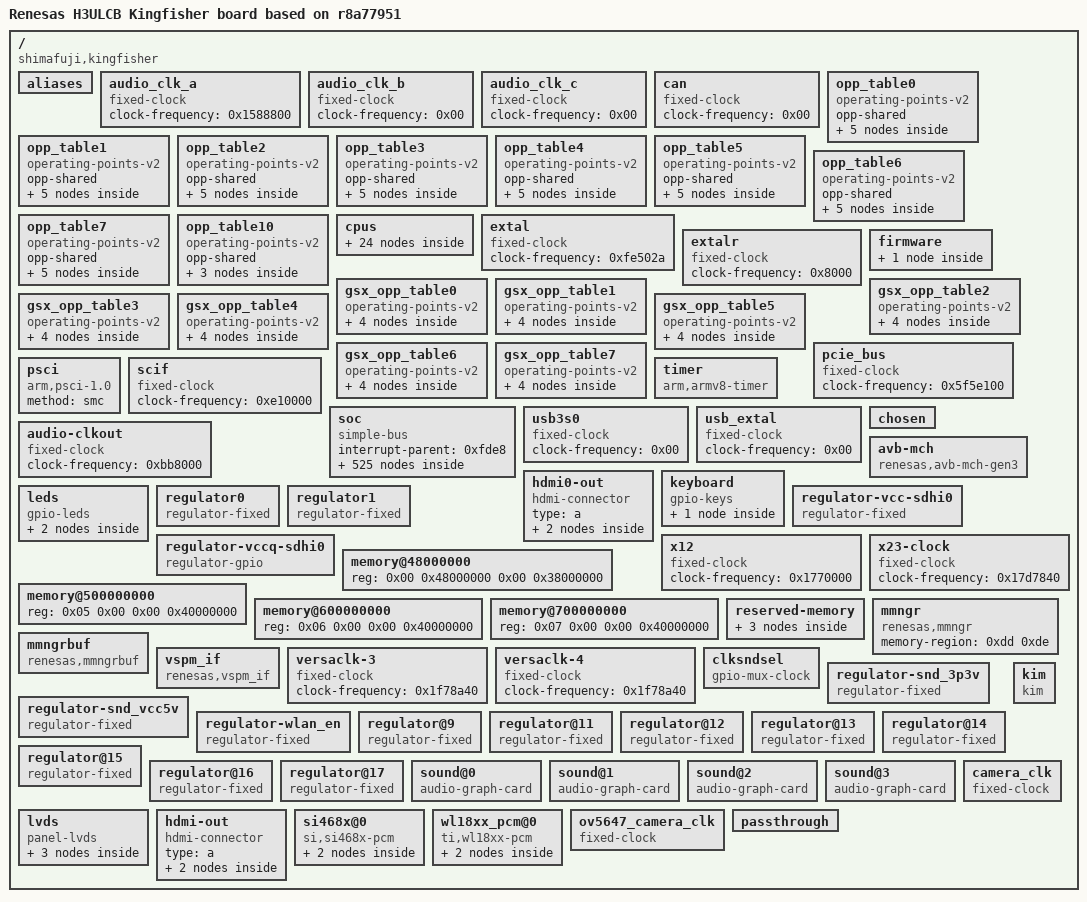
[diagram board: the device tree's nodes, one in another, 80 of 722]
/dts-v1/;

/ {
	compatible = "shimafuji,kingfisher\0renesas,h3ulcb\0renesas,r8a7795";
	#address-cells = <0x02>;
	#size-cells = <0x02>;
	model = "Renesas H3ULCB Kingfisher board based on r8a77951";

	aliases {
		i2c0 = "/soc/i2c@e6500000";
		i2c1 = "/soc/i2c@e6508000";
		i2c2 = "/soc/i2c@e6510000";
		i2c3 = "/soc/i2c@e66d0000";
		i2c4 = "/soc/i2c@e66d8000";
		i2c5 = "/soc/i2c@e66e0000";
		i2c6 = "/soc/i2c@e66e8000";
		i2c7 = "/soc/i2c@e60b0000";
		spi0 = "/soc/spi@e6e90000";
		spi1 = "/soc/spi@e6ea0000";
		spi2 = "/soc/spi@e6c00000";
		spi3 = "/soc/spi@e6c10000";
		serial0 = "/soc/serial@e6e88000";
		ethernet0 = "/soc/ethernet@e6800000";
		mmc0 = "/soc/mmc@ee140000";
		mmc1 = "/soc/mmc@ee100000";
		serial1 = "/soc/serial@e6540000";
		serial2 = "/soc/serial@e6e68000";
		serial3 = "/soc/serial@e6550000";
		mmc2 = "/soc/mmc@ee160000";
	};

	audio_clk_a {
		compatible = "fixed-clock";
		#clock-cells = <0x00>;
		clock-frequency = <0x1588800>;
		phandle = <0x79>;
	};

	audio_clk_b {
		compatible = "fixed-clock";
		#clock-cells = <0x00>;
		clock-frequency = <0x00>;
		phandle = <0xe9>;
	};

	audio_clk_c {
		compatible = "fixed-clock";
		#clock-cells = <0x00>;
		clock-frequency = <0x00>;
		phandle = <0x7a>;
	};

	can {
		compatible = "fixed-clock";
		#clock-cells = <0x00>;
		clock-frequency = <0x00>;
		phandle = <0x58>;
	};

	opp_table0 {
		compatible = "operating-points-v2";
		opp-shared;
		phandle = <0x0d>;

		opp-500000000 {
			opp-hz = <0x00 0x1dcd6500>;
			opp-microvolt = <0xcaa30>;
			clock-latency-ns = <0x493e0>;
		};

		opp-1000000000 {
			opp-hz = <0x00 0x3b9aca00>;
			opp-microvolt = <0xcaa30>;
			clock-latency-ns = <0x493e0>;
		};

		opp-1500000000 {
			opp-hz = <0x00 0x59682f00>;
			opp-microvolt = <0xcaa30>;
			clock-latency-ns = <0x493e0>;
			opp-suspend;
		};

		opp-1600000000 {
			opp-hz = <0x00 0x5f5e1000>;
			opp-microvolt = <0xdbba0>;
			clock-latency-ns = <0x493e0>;
			turbo-mode;
		};

		opp-1700000000 {
			opp-hz = <0x00 0x6553f100>;
			opp-microvolt = <0xea600>;
			clock-latency-ns = <0x493e0>;
			turbo-mode;
		};
	};

	opp_table1 {
		compatible = "operating-points-v2";
		opp-shared;
		phandle = <0x0e>;

		opp-500000000 {
			opp-hz = <0x00 0x1dcd6500>;
			opp-microvolt = <0xc8320>;
			clock-latency-ns = <0x493e0>;
		};

		opp-1000000000 {
			opp-hz = <0x00 0x3b9aca00>;
			opp-microvolt = <0xc8320>;
			clock-latency-ns = <0x493e0>;
		};

		opp-1500000000 {
			opp-hz = <0x00 0x59682f00>;
			opp-microvolt = <0xc8320>;
			clock-latency-ns = <0x493e0>;
			opp-suspend;
		};

		opp-1600000000 {
			opp-hz = <0x00 0x5f5e1000>;
			opp-microvolt = <0xd9490>;
			clock-latency-ns = <0x493e0>;
			turbo-mode;
		};

		opp-1700000000 {
			opp-hz = <0x00 0x6553f100>;
			opp-microvolt = <0xe7ef0>;
			clock-latency-ns = <0x493e0>;
			turbo-mode;
		};
	};

	opp_table2 {
		compatible = "operating-points-v2";
		opp-shared;
		phandle = <0x0f>;

		opp-500000000 {
			opp-hz = <0x00 0x1dcd6500>;
			opp-microvolt = <0xc5c10>;
			clock-latency-ns = <0x493e0>;
		};

		opp-1000000000 {
			opp-hz = <0x00 0x3b9aca00>;
			opp-microvolt = <0xc5c10>;
			clock-latency-ns = <0x493e0>;
		};

		opp-1500000000 {
			opp-hz = <0x00 0x59682f00>;
			opp-microvolt = <0xc5c10>;
			clock-latency-ns = <0x493e0>;
			opp-suspend;
		};

		opp-1600000000 {
			opp-hz = <0x00 0x5f5e1000>;
			opp-microvolt = <0xd6d80>;
			clock-latency-ns = <0x493e0>;
			turbo-mode;
		};

		opp-1700000000 {
			opp-hz = <0x00 0x6553f100>;
			opp-microvolt = <0xe30d0>;
			clock-latency-ns = <0x493e0>;
			turbo-mode;
		};
	};

	opp_table3 {
		compatible = "operating-points-v2";
		opp-shared;
		phandle = <0x10>;

		opp-500000000 {
			opp-hz = <0x00 0x1dcd6500>;
			opp-microvolt = "\0\f5";
			clock-latency-ns = <0x493e0>;
		};

		opp-1000000000 {
			opp-hz = <0x00 0x3b9aca00>;
			opp-microvolt = "\0\f5";
			clock-latency-ns = <0x493e0>;
		};

		opp-1500000000 {
			opp-hz = <0x00 0x59682f00>;
			opp-microvolt = "\0\f5";
			clock-latency-ns = <0x493e0>;
			opp-suspend;
		};

		opp-1600000000 {
			opp-hz = <0x00 0x5f5e1000>;
			opp-microvolt = <0xd4670>;
			clock-latency-ns = <0x493e0>;
			turbo-mode;
		};

		opp-1700000000 {
			opp-hz = <0x00 0x6553f100>;
			opp-microvolt = <0xde2b0>;
			clock-latency-ns = <0x493e0>;
			turbo-mode;
		};
	};

	opp_table4 {
		compatible = "operating-points-v2";
		opp-shared;
		phandle = <0x11>;

		opp-500000000 {
			opp-hz = <0x00 0x1dcd6500>;
			opp-microvolt = <0xc0df0>;
			clock-latency-ns = <0x493e0>;
		};

		opp-1000000000 {
			opp-hz = <0x00 0x3b9aca00>;
			opp-microvolt = <0xc0df0>;
			clock-latency-ns = <0x493e0>;
		};

		opp-1500000000 {
			opp-hz = <0x00 0x59682f00>;
			opp-microvolt = <0xc0df0>;
			clock-latency-ns = <0x493e0>;
			opp-suspend;
		};

		opp-1600000000 {
			opp-hz = <0x00 0x5f5e1000>;
			opp-microvolt = <0xd1f60>;
			clock-latency-ns = <0x493e0>;
			turbo-mode;
		};

		opp-1700000000 {
			opp-hz = <0x00 0x6553f100>;
			opp-microvolt = <0xd9490>;
			clock-latency-ns = <0x493e0>;
			turbo-mode;
		};
	};

	opp_table5 {
		compatible = "operating-points-v2";
		opp-shared;
		phandle = <0x12>;

		opp-500000000 {
			opp-hz = <0x00 0x1dcd6500>;
			opp-microvolt = <0xbe6e0>;
			clock-latency-ns = <0x493e0>;
		};

		opp-1000000000 {
			opp-hz = <0x00 0x3b9aca00>;
			opp-microvolt = <0xbe6e0>;
			clock-latency-ns = <0x493e0>;
		};

		opp-1500000000 {
			opp-hz = <0x00 0x59682f00>;
			opp-microvolt = <0xbe6e0>;
			clock-latency-ns = <0x493e0>;
			opp-suspend;
		};

		opp-1600000000 {
			opp-hz = <0x00 0x5f5e1000>;
			opp-microvolt = <0xcf850>;
			clock-latency-ns = <0x493e0>;
			turbo-mode;
		};

		opp-1700000000 {
			opp-hz = <0x00 0x6553f100>;
			opp-microvolt = <0xd6d80>;
			clock-latency-ns = <0x493e0>;
			turbo-mode;
		};
	};

	opp_table6 {
		compatible = "operating-points-v2";
		opp-shared;
		phandle = <0x13>;

		opp-500000000 {
			opp-hz = <0x00 0x1dcd6500>;
			opp-microvolt = <0xbbfd0>;
			clock-latency-ns = <0x493e0>;
		};

		opp-1000000000 {
			opp-hz = <0x00 0x3b9aca00>;
			opp-microvolt = <0xbbfd0>;
			clock-latency-ns = <0x493e0>;
		};

		opp-1500000000 {
			opp-hz = <0x00 0x59682f00>;
			opp-microvolt = <0xbbfd0>;
			clock-latency-ns = <0x493e0>;
			opp-suspend;
		};

		opp-1600000000 {
			opp-hz = <0x00 0x5f5e1000>;
			opp-microvolt = <0xcd140>;
			clock-latency-ns = <0x493e0>;
			turbo-mode;
		};

		opp-1700000000 {
			opp-hz = <0x00 0x6553f100>;
			opp-microvolt = <0xd4670>;
			clock-latency-ns = <0x493e0>;
			turbo-mode;
		};
	};

	opp_table7 {
		compatible = "operating-points-v2";
		opp-shared;
		phandle = <0x14>;

		opp-500000000 {
			opp-hz = <0x00 0x1dcd6500>;
			opp-microvolt = <0xb98c0>;
			clock-latency-ns = <0x493e0>;
		};

		opp-1000000000 {
			opp-hz = <0x00 0x3b9aca00>;
			opp-microvolt = <0xb98c0>;
			clock-latency-ns = <0x493e0>;
		};

		opp-1500000000 {
			opp-hz = <0x00 0x59682f00>;
			opp-microvolt = <0xb98c0>;
			clock-latency-ns = <0x493e0>;
			opp-suspend;
		};

		opp-1600000000 {
			opp-hz = <0x00 0x5f5e1000>;
			opp-microvolt = <0xcaa30>;
			clock-latency-ns = <0x493e0>;
			turbo-mode;
		};

		opp-1700000000 {
			opp-hz = <0x00 0x6553f100>;
			opp-microvolt = <0xd1f60>;
			clock-latency-ns = <0x493e0>;
			turbo-mode;
		};
	};

	opp_table10 {
		compatible = "operating-points-v2";
		opp-shared;
		phandle = <0x18>;

		opp-800000000 {
			opp-hz = <0x00 0x2faf0800>;
			opp-microvolt = <0xc8320>;
			clock-latency-ns = <0x493e0>;
		};

		opp-1000000000 {
			opp-hz = <0x00 0x3b9aca00>;
			opp-microvolt = <0xc8320>;
			clock-latency-ns = <0x493e0>;
		};

		opp-1200000000 {
			opp-hz = <0x00 0x47868c00>;
			opp-microvolt = <0xc8320>;
			clock-latency-ns = <0x493e0>;
			opp-suspend;
		};
	};

	cpus {
		#address-cells = <0x01>;
		#size-cells = <0x00>;

		cpu-map {

			cluster0 {

				core0 {
					cpu = <0x01>;
				};

				core1 {
					cpu = <0x02>;
				};

				core2 {
					cpu = <0x03>;
				};

				core3 {
					cpu = <0x04>;
				};
			};

			cluster1 {

				core0 {
					cpu = <0x05>;
				};

				core1 {
					cpu = <0x06>;
				};

				core2 {
					cpu = <0x07>;
				};

				core3 {
					cpu = <0x08>;
				};
			};
		};

		cpu@0 {
			compatible = "arm,cortex-a57";
			reg = <0x00>;
			device_type = "cpu";
			power-domains = <0x09 0x00>;
			next-level-cache = <0x0a>;
			enable-method = "psci";
			cpu-idle-states = <0x0b>;
			dynamic-power-coefficient = <0x356>;
			cooling-min-level = <0x00>;
			cooling-max-level = <0x02>;
			clocks = <0x0c 0x00 0x00>;
			operating-points-v2 = <0x0d 0x0e 0x0f 0x10 0x11 0x12 0x13 0x14>;
			capacity-dmips-mhz = <0x400>;
			#cooling-cells = <0x02>;
			cpu-supply = <0x15>;
			phandle = <0x01>;
		};

		cpu@1 {
			compatible = "arm,cortex-a57";
			reg = <0x01>;
			device_type = "cpu";
			power-domains = <0x09 0x01>;
			next-level-cache = <0x0a>;
			enable-method = "psci";
			cpu-idle-states = <0x0b>;
			clocks = <0x0c 0x00 0x00>;
			operating-points-v2 = <0x0d 0x0e 0x0f 0x10 0x11 0x12 0x13 0x14>;
			capacity-dmips-mhz = <0x400>;
			#cooling-cells = <0x02>;
			phandle = <0x02>;
		};

		cpu@2 {
			compatible = "arm,cortex-a57";
			reg = <0x02>;
			device_type = "cpu";
			power-domains = <0x09 0x02>;
			next-level-cache = <0x0a>;
			enable-method = "psci";
			cpu-idle-states = <0x0b>;
			clocks = <0x0c 0x00 0x00>;
			operating-points-v2 = <0x0d 0x0e 0x0f 0x10 0x11 0x12 0x13 0x14>;
			capacity-dmips-mhz = <0x400>;
			#cooling-cells = <0x02>;
			phandle = <0x03>;
		};

		cpu@3 {
			compatible = "arm,cortex-a57";
			reg = <0x03>;
			device_type = "cpu";
			power-domains = <0x09 0x03>;
			next-level-cache = <0x0a>;
			enable-method = "psci";
			cpu-idle-states = <0x0b>;
			clocks = <0x0c 0x00 0x00>;
			operating-points-v2 = <0x0d 0x0e 0x0f 0x10 0x11 0x12 0x13 0x14>;
			capacity-dmips-mhz = <0x400>;
			#cooling-cells = <0x02>;
			phandle = <0x04>;
		};

		cpu@100 {
			compatible = "arm,cortex-a53";
			reg = <0x100>;
			device_type = "cpu";
			power-domains = <0x09 0x05>;
			next-level-cache = <0x16>;
			enable-method = "psci";
			cpu-idle-states = <0x17>;
			#cooling-cells = <0x02>;
			dynamic-power-coefficient = <0x115>;
			cooling-min-level = <0x00>;
			cooling-max-level = <0x02>;
			clocks = <0x0c 0x00 0x01>;
			operating-points-v2 = <0x18>;
			capacity-dmips-mhz = <0x21c>;
			phandle = <0x05>;
		};

		cpu@101 {
			compatible = "arm,cortex-a53";
			reg = <0x101>;
			device_type = "cpu";
			power-domains = <0x09 0x06>;
			next-level-cache = <0x16>;
			enable-method = "psci";
			cpu-idle-states = <0x17>;
			clocks = <0x0c 0x00 0x01>;
			operating-points-v2 = <0x18>;
			capacity-dmips-mhz = <0x21c>;
			phandle = <0x06>;
		};

		cpu@102 {
			compatible = "arm,cortex-a53";
			reg = <0x102>;
			device_type = "cpu";
			power-domains = <0x09 0x07>;
			next-level-cache = <0x16>;
			enable-method = "psci";
			cpu-idle-states = <0x17>;
			clocks = <0x0c 0x00 0x01>;
			operating-points-v2 = <0x18>;
			capacity-dmips-mhz = <0x21c>;
			phandle = <0x07>;
		};

		cpu@103 {
			compatible = "arm,cortex-a53";
			reg = <0x103>;
			device_type = "cpu";
			power-domains = <0x09 0x08>;
			next-level-cache = <0x16>;
			enable-method = "psci";
			cpu-idle-states = <0x17>;
			clocks = <0x0c 0x00 0x01>;
			operating-points-v2 = <0x18>;
			capacity-dmips-mhz = <0x21c>;
			phandle = <0x08>;
		};

		cache-controller-0 {
			compatible = "cache";
			power-domains = <0x09 0x0c>;
			cache-unified;
			cache-level = <0x02>;
			phandle = <0x0a>;
		};

		cache-controller-1 {
			compatible = "cache";
			power-domains = <0x09 0x15>;
			cache-unified;
			cache-level = <0x02>;
			phandle = <0x16>;
		};

		idle-states {
			entry-method = "psci";

			cpu-sleep-0 {
				compatible = "arm,idle-state";
				arm,psci-suspend-param = <0x10000>;
				local-timer-stop;
				entry-latency-us = <0x190>;
				exit-latency-us = <0x1f4>;
				min-residency-us = <0xfa0>;
				phandle = <0x0b>;
			};

			cpu-sleep-1 {
				compatible = "arm,idle-state";
				arm,psci-suspend-param = <0x10000>;
				local-timer-stop;
				entry-latency-us = <0x2bc>;
				exit-latency-us = <0x2bc>;
				min-residency-us = <0x1388>;
				phandle = <0x17>;
			};
		};
	};

	extal {
		compatible = "fixed-clock";
		#clock-cells = <0x00>;
		clock-frequency = <0xfe502a>;
		phandle = <0x1c>;
	};

	extalr {
		compatible = "fixed-clock";
		#clock-cells = <0x00>;
		clock-frequency = <0x8000>;
		phandle = <0x1d>;
	};

	firmware {

		optee {
			compatible = "linaro,optee-tz";
			method = "smc";
		};
	};

	gsx_opp_table0 {
		compatible = "operating-points-v2";
		phandle = <0xa5>;

		opp-200000000 {
			opp-hz = <0x00 0xbebc200>;
			opp-microvolt = <0xcaa30>;
		};

		opp-300000000 {
			opp-hz = <0x00 0x11e1a300>;
			opp-microvolt = <0xcaa30>;
		};

		opp-400000000 {
			opp-hz = <0x00 0x17d78400>;
			opp-microvolt = <0xcaa30>;
		};

		opp-600000000 {
			opp-hz = <0x00 0x23c34600>;
			opp-microvolt = <0xcaa30>;
		};
	};

	gsx_opp_table1 {
		compatible = "operating-points-v2";
		phandle = <0xa6>;

		opp-200000000 {
			opp-hz = <0x00 0xbebc200>;
			opp-microvolt = <0xc8320>;
		};

		opp-300000000 {
			opp-hz = <0x00 0x11e1a300>;
			opp-microvolt = <0xc8320>;
		};

		opp-400000000 {
			opp-hz = <0x00 0x17d78400>;
			opp-microvolt = <0xc8320>;
		};

		opp-600000000 {
			opp-hz = <0x00 0x23c34600>;
			opp-microvolt = <0xc8320>;
		};
	};

	gsx_opp_table2 {
		compatible = "operating-points-v2";
		phandle = <0xa7>;

		opp-200000000 {
			opp-hz = <0x00 0xbebc200>;
			opp-microvolt = <0xc5c10>;
		};

		opp-300000000 {
			opp-hz = <0x00 0x11e1a300>;
			opp-microvolt = <0xc5c10>;
		};

		opp-400000000 {
			opp-hz = <0x00 0x17d78400>;
			opp-microvolt = <0xc5c10>;
		};

		opp-600000000 {
			opp-hz = <0x00 0x23c34600>;
			opp-microvolt = <0xc5c10>;
		};
	};

	gsx_opp_table3 {
		compatible = "operating-points-v2";
		phandle = <0xa8>;

		opp-200000000 {
			opp-hz = <0x00 0xbebc200>;
			opp-microvolt = "\0\f5";
		};

		opp-300000000 {
			opp-hz = <0x00 0x11e1a300>;
			opp-microvolt = "\0\f5";
		};

		opp-400000000 {
			opp-hz = <0x00 0x17d78400>;
			opp-microvolt = "\0\f5";
		};

		opp-600000000 {
			opp-hz = <0x00 0x23c34600>;
			opp-microvolt = "\0\f5";
		};
	};

	gsx_opp_table4 {
		compatible = "operating-points-v2";
		phandle = <0xa9>;

		opp-200000000 {
			opp-hz = <0x00 0xbebc200>;
			opp-microvolt = <0xc0df0>;
		};

		opp-300000000 {
			opp-hz = <0x00 0x11e1a300>;
			opp-microvolt = <0xc0df0>;
		};

		opp-400000000 {
			opp-hz = <0x00 0x17d78400>;
			opp-microvolt = <0xc0df0>;
		};

		opp-600000000 {
			opp-hz = <0x00 0x23c34600>;
			opp-microvolt = <0xc0df0>;
		};
	};

	gsx_opp_table5 {
		compatible = "operating-points-v2";
		phandle = <0xaa>;

		opp-200000000 {
			opp-hz = <0x00 0xbebc200>;
			opp-microvolt = <0xbe6e0>;
		};

		opp-300000000 {
			opp-hz = <0x00 0x11e1a300>;
			opp-microvolt = <0xbe6e0>;
		};

		opp-400000000 {
			opp-hz = <0x00 0x17d78400>;
			opp-microvolt = <0xbe6e0>;
		};

		opp-600000000 {
			opp-hz = <0x00 0x23c34600>;
			opp-microvolt = <0xbe6e0>;
		};
	};

	gsx_opp_table6 {
		compatible = "operating-points-v2";
		phandle = <0xab>;

		opp-200000000 {
			opp-hz = <0x00 0xbebc200>;
			opp-microvolt = <0xbbfd0>;
		};

		opp-300000000 {
			opp-hz = <0x00 0x11e1a300>;
			opp-microvolt = <0xbbfd0>;
		};

		opp-400000000 {
			opp-hz = <0x00 0x17d78400>;
			opp-microvolt = <0xbbfd0>;
		};

		opp-600000000 {
			opp-hz = <0x00 0x23c34600>;
			opp-microvolt = <0xbbfd0>;
		};
	};

	gsx_opp_table7 {
		compatible = "operating-points-v2";
		phandle = <0xac>;

		opp-200000000 {
			opp-hz = <0x00 0xbebc200>;
			opp-microvolt = <0xb98c0>;
		};

		opp-300000000 {
			opp-hz = <0x00 0x11e1a300>;
			opp-microvolt = <0xb98c0>;
		};

		opp-400000000 {
			opp-hz = <0x00 0x17d78400>;
			opp-microvolt = <0xb98c0>;
		};

		opp-600000000 {
			opp-hz = <0x00 0x23c34600>;
			opp-microvolt = <0xb98c0>;
		};
	};

	pcie_bus {
		compatible = "fixed-clock";
		#clock-cells = <0x00>;
		clock-frequency = <0x5f5e100>;
		status = "okay";
		phandle = <0xae>;
	};

	psci {
		compatible = "arm,psci-1.0\0arm,psci-0.2";
		method = "smc";
	};

	scif {
		compatible = "fixed-clock";
		#clock-cells = <0x00>;
		clock-frequency = <0xe10000>;
		phandle = <0x48>;
	};

	soc {
		compatible = "simple-bus";
		interrupt-parent = <0xfde8>;
		#address-cells = <0x02>;
		#size-cells = <0x02>;
		ranges;
		phandle = <0xea>;

		mfis@e6260000 {
			compatible = "renesas,mfis-lock-r8a7795\0renesas,mfis-lock";
			reg = <0x00 0xe6260000 0x00 0x1000>;
			#hwlock-cells = <0x01>;
			phandle = <0xeb>;
		};

		watchdog@e6020000 {
			compatible = "renesas,r8a7795-wdt\0renesas,rcar-gen3-wdt";
			reg = <0x00 0xe6020000 0x00 0x0c>;
			clocks = <0x0c 0x01 0x192>;
			power-domains = <0x09 0x20>;
			resets = <0x0c 0x192>;
			status = "okay";
			timeout-sec = <0x3c>;
			phandle = <0xec>;
		};

		gpio@e6050000 {
			compatible = "renesas,gpio-r8a7795\0renesas,rcar-gen3-gpio";
			reg = <0x00 0xe6050000 0x00 0x50>;
			interrupts = <0x00 0x04 0x04>;
			#gpio-cells = <0x02>;
			gpio-controller;
			gpio-ranges = <0x19 0x00 0x00 0x10>;
			#interrupt-cells = <0x02>;
			interrupt-controller;
			clocks = <0x0c 0x01 0x390>;
			power-domains = <0x09 0x20>;
			resets = <0x0c 0x390>;
			phandle = <0xed>;
		};

		gpio@e6051000 {
			compatible = "renesas,gpio-r8a7795\0renesas,rcar-gen3-gpio";
			reg = <0x00 0xe6051000 0x00 0x50>;
			interrupts = <0x00 0x05 0x04>;
			#gpio-cells = <0x02>;
			gpio-controller;
			gpio-ranges = <0x19 0x00 0x20 0x1d>;
			#interrupt-cells = <0x02>;
			interrupt-controller;
			clocks = <0x0c 0x01 0x38f>;
			power-domains = <0x09 0x20>;
			resets = <0x0c 0x38f>;
			phandle = <0xa4>;
		};

		gpio@e6052000 {
			compatible = "renesas,gpio-r8a7795\0renesas,rcar-gen3-gpio";
			reg = <0x00 0xe6052000 0x00 0x50>;
			interrupts = <0x00 0x06 0x04>;
			#gpio-cells = <0x02>;
			gpio-controller;
			gpio-ranges = <0x19 0x00 0x40 0x0f>;
			#interrupt-cells = <0x02>;
			interrupt-controller;
			clocks = <0x0c 0x01 0x38e>;
			power-domains = <0x09 0x20>;
			resets = <0x0c 0x38e>;
			phandle = <0x57>;

			gpio@3 {
				gpio-hog;
				gpios = <0x03 0x00>;
				output-high;
				line-name = "BL PWM 100%";
			};
		};

		gpio@e6053000 {
			compatible = "renesas,gpio-r8a7795\0renesas,rcar-gen3-gpio";
			reg = <0x00 0xe6053000 0x00 0x50>;
			interrupts = <0x00 0x07 0x04>;
			#gpio-cells = <0x02>;
			gpio-controller;
			gpio-ranges = <0x19 0x00 0x60 0x10>;
			#interrupt-cells = <0x02>;
			interrupt-controller;
			clocks = <0x0c 0x01 0x38d>;
			power-domains = <0x09 0x20>;
			resets = <0x0c 0x38d>;
			phandle = <0x31>;
		};

		gpio@e6054000 {
			compatible = "renesas,gpio-r8a7795\0renesas,rcar-gen3-gpio";
			reg = <0x00 0xe6054000 0x00 0x50>;
			interrupts = <0x00 0x08 0x04>;
			#gpio-cells = <0x02>;
			gpio-controller;
			gpio-ranges = <0x19 0x00 0x80 0x12>;
			#interrupt-cells = <0x02>;
			interrupt-controller;
			clocks = <0x0c 0x01 0x38c>;
			power-domains = <0x09 0x20>;
			resets = <0x0c 0x38c>;
			phandle = <0xee>;

			most_rst {
				gpio-hog;
				gpios = <0x0e 0x00>;
				output-high;
				line-name = "MOST RST";
			};
		};

		gpio@e6055000 {
			compatible = "renesas,gpio-r8a7795\0renesas,rcar-gen3-gpio";
			reg = <0x00 0xe6055000 0x00 0x50>;
			interrupts = <0x00 0x09 0x04>;
			#gpio-cells = <0x02>;
			gpio-controller;
			gpio-ranges = <0x19 0x00 0xa0 0x1a>;
			#interrupt-cells = <0x02>;
			interrupt-controller;
			clocks = <0x0c 0x01 0x38b>;
			power-domains = <0x09 0x20>;
			resets = <0x0c 0x38b>;
			phandle = <0x26>;
		};

		gpio@e6055400 {
			compatible = "renesas,gpio-r8a7795\0renesas,rcar-gen3-gpio";
			reg = <0x00 0xe6055400 0x00 0x50>;
			interrupts = <0x00 0x0a 0x04>;
			#gpio-cells = <0x02>;
			gpio-controller;
			gpio-ranges = <0x19 0x00 0xc0 0x20>;
			#interrupt-cells = <0x02>;
			interrupt-controller;
			clocks = <0x0c 0x01 0x38a>;
			power-domains = <0x09 0x20>;
			resets = <0x0c 0x38a>;
			phandle = <0x2e>;

			audio_sw {
				gpio-hog;
				gpios = <0x15 0x00>;
				output-high;
				line-name = "Onboard MCh Audio";
			};
		};

		gpio@e6055800 {
			compatible = "renesas,gpio-r8a7795\0renesas,rcar-gen3-gpio";
			reg = <0x00 0xe6055800 0x00 0x50>;
			interrupts = <0x00 0x0b 0x04>;
			#gpio-cells = <0x02>;
			gpio-controller;
			gpio-ranges = <0x19 0x00 0xe0 0x04>;
			#interrupt-cells = <0x02>;
			interrupt-controller;
			clocks = <0x0c 0x01 0x389>;
			power-domains = <0x09 0x20>;
			resets = <0x0c 0x389>;
			phandle = <0x45>;
		};

		pinctrl@e6060000 {
			compatible = "renesas,pfc-r8a7795";
			reg = <0x00 0xe6060000 0x00 0x50c>;
			pinctrl-0 = <0x1a>;
			pinctrl-names = "default";
			phandle = <0x19>;

			avb {
				phandle = <0x55>;

				mux {
					groups = "avb_link\0avb_mdio\0avb_mii";
					function = "avb";
				};

				pins_mdio {
					groups = "avb_mdio";
					drive-strength = <0x18>;
				};

				pins_mii_tx {
					pins = "PIN_AVB_TX_CTL\0PIN_AVB_TXC\0PIN_AVB_TD0\0PIN_AVB_TD1\0PIN_AVB_TD2\0PIN_AVB_TD3";
					drive-strength = <0x0c>;
				};
			};

			i2c2 {
				groups = "i2c2_a";
				function = "i2c2";
				phandle = <0x20>;
			};

			irq0 {
				groups = "intc_ex_irq0";
				function = "intc_ex";
				phandle = <0x46>;
			};

			scif2 {
				groups = "scif2_data_a";
				function = "scif2";
				phandle = <0x5e>;
			};

			scif_clk {
				groups = "scif_clk_a";
				function = "scif_clk";
				phandle = <0x1a>;
			};

			sd0 {
				groups = "sdhi0_data4\0sdhi0_ctrl";
				function = "sdhi0";
				power-source = <0xce4>;
				phandle = <0x9a>;
			};

			sd0_uhs {
				groups = "sdhi0_data4\0sdhi0_ctrl";
				function = "sdhi0";
				power-source = <0x708>;
				phandle = <0x9b>;
			};

			sd2 {
				groups = "sdhi2_data8\0sdhi2_ctrl\0sdhi2_ds";
				function = "sdhi2";
				power-source = <0x708>;
				phandle = <0x9e>;
			};

			sound {
				groups = "ssi01239_ctrl\0ssi0_data\0ssi1_data_a";
				function = "ssi";
				phandle = <0x7b>;
			};

			sound-clk {
				groups = "audio_clk_a_a\0audio_clk_b_a\0audio_clk_c_a\0audio_clkout_a\0audio_clkout3_a";
				function = "audio_clk";
				phandle = <0x7c>;
			};

			usb1 {
				groups = "usb1";
				function = "usb1";
				phandle = <0x99>;
			};

			can0 {
				groups = "can0_data_a";
				function = "can0";
				phandle = <0x59>;
			};

			can1 {
				groups = "can1_data";
				function = "can1";
				phandle = <0x5a>;
			};

			canfd0 {
				groups = "canfd0_data_a";
				function = "canfd0";
				phandle = <0x5b>;
			};

			canfd1 {
				groups = "canfd1_data";
				function = "canfd1";
				phandle = <0x5c>;
			};

			du {
				groups = "du_rgb888\0du_sync\0du_clk_out_0\0du_disp";
				function = "du";
				phandle = <0xd4>;
			};

			hscif0 {
				groups = "hscif0_data\0hscif0_ctrl";
				function = "hscif0";
				phandle = <0x49>;
			};

			hscif1 {
				groups = "hscif1_data_a\0hscif1_ctrl_a";
				function = "hscif1";
				phandle = <0x4b>;
			};

			scif1 {
				groups = "scif1_data_b";
				function = "scif1";
				phandle = <0x5d>;
			};

			sdhi3 {
				groups = "sdhi3_data4\0sdhi3_ctrl";
				function = "sdhi3";
				power-source = <0xce4>;
				phandle = <0xa2>;
			};

			sound-pcm {
				groups = "ssi349_ctrl\0ssi3_data\0ssi4_data\0ssi6_ctrl\0ssi6_data\0ssi78_ctrl\0ssi7_data\0ssi8_data";
				function = "ssi";
				phandle = <0x7d>;
			};

			usb0 {
				groups = "usb0";
				function = "usb0";
				phandle = <0x98>;
			};

			vin5 {
				groups = "vin5_data8\0vin5_sync\0vin5_clk";
				function = "vin5";
				phandle = <0x69>;
			};
		};

		timer@e60f0000 {
			compatible = "renesas,r8a7795-cmt0\0renesas,rcar-gen3-cmt0";
			reg = <0x00 0xe60f0000 0x00 0x1004>;
			interrupts = <0x00 0x8e 0x04 0x00 0x8f 0x04>;
			clocks = <0x0c 0x01 0x12f>;
			clock-names = "fck";
			power-domains = <0x09 0x20>;
			resets = <0x0c 0x12f>;
			status = "disabled";
			phandle = <0xef>;
		};

		timer@e6130000 {
			compatible = "renesas,r8a7795-cmt1\0renesas,rcar-gen3-cmt1";
			reg = <0x00 0xe6130000 0x00 0x1004>;
			interrupts = <0x00 0x78 0x04 0x00 0x79 0x04 0x00 0x7a 0x04 0x00 0x7b 0x04 0x00 0x7c 0x04 0x00 0x7d 0x04 0x00 0x7e 0x04 0x00 0x7f 0x04>;
			clocks = <0x0c 0x01 0x12e>;
			clock-names = "fck";
			power-domains = <0x09 0x20>;
			resets = <0x0c 0x12e>;
			status = "disabled";
			phandle = <0xf0>;
		};

		timer@e6140000 {
			compatible = "renesas,r8a7795-cmt1\0renesas,rcar-gen3-cmt1";
			reg = <0x00 0xe6140000 0x00 0x1004>;
			interrupts = <0x00 0x18e 0x04 0x00 0x18f 0x04 0x00 0x190 0x04 0x00 0x191 0x04 0x00 0x192 0x04 0x00 0x193 0x04 0x00 0x194 0x04 0x00 0x195 0x04>;
			clocks = <0x0c 0x01 0x12d>;
			clock-names = "fck";
			power-domains = <0x09 0x20>;
			resets = <0x0c 0x12d>;
			status = "disabled";
			phandle = <0xf1>;
		};

		timer@e6148000 {
			compatible = "renesas,r8a7795-cmt1\0renesas,rcar-gen3-cmt1";
			reg = <0x00 0xe6148000 0x00 0x1004>;
			interrupts = <0x00 0x1d6 0x04 0x00 0x1d7 0x04 0x00 0x1d8 0x04 0x00 0x1d9 0x04 0x00 0x1da 0x04 0x00 0x1db 0x04 0x00 0x1dc 0x04 0x00 0x1dd 0x04>;
			clocks = <0x0c 0x01 0x12c>;
			clock-names = "fck";
			power-domains = <0x09 0x20>;
			resets = <0x0c 0x12c>;
			status = "disabled";
			phandle = <0xf2>;
		};

		avs@e60a013c {
			compatible = "renesas,r8a77951-avs\0renesas,rcar-gen3-avs";
			reg = <0x00 0xe60a013c 0x00 0x04>;
			clocks = <0x0c 0x01 0x39d>;
			resets = <0x0c 0x39d>;
			target_devices = <0x01 0x02 0x03 0x04 0x1b>;
			phandle = <0xf3>;
		};

		clock-controller@e6150000 {
			compatible = "renesas,r8a7795-cpg-mssr";
			reg = <0x00 0xe6150000 0x00 0x1000>;
			clocks = <0x1c 0x1d>;
			clock-names = "extal\0extalr";
			#clock-cells = <0x02>;
			#power-domain-cells = <0x00>;
			#reset-cells = <0x01>;
			phandle = <0x0c>;
		};

		reset-controller@e6160000 {
			compatible = "renesas,r8a7795-rst";
			reg = <0x00 0xe6160000 0x00 0x200>;
			phandle = <0xf4>;
		};

		system-controller@e6180000 {
			compatible = "renesas,r8a7795-sysc";
			reg = <0x00 0xe6180000 0x00 0x400>;
			#power-domain-cells = <0x01>;
			phandle = <0x09>;
		};

		thermal@e6198000 {
			compatible = "renesas,r8a7795-thermal";
			reg = <0x00 0xe6198000 0x00 0x100 0x00 0xe61a0000 0x00 0x100 0x00 0xe61a8000 0x00 0x100>;
			interrupts = <0x00 0x43 0x04 0x00 0x44 0x04 0x00 0x45 0x04>;
			clocks = <0x0c 0x01 0x20a>;
			power-domains = <0x09 0x20>;
			resets = <0x0c 0x20a>;
			#thermal-sensor-cells = <0x01>;
			phandle = <0xf5>;
		};

		interrupt-controller@e61c0000 {
			compatible = "renesas,intc-ex-r8a7795\0renesas,irqc";
			#interrupt-cells = <0x02>;
			interrupt-controller;
			reg = <0x00 0xe61c0000 0x00 0x200>;
			interrupts = <0x00 0x00 0x04 0x00 0x01 0x04 0x00 0x02 0x04 0x00 0x03 0x04 0x00 0x12 0x04 0x00 0xa1 0x04>;
			power-domains = <0x09 0x20>;
			phandle = <0x47>;
		};

		timer@e61e0000 {
			compatible = "renesas,tmu-r8a7795\0renesas,tmu";
			reg = <0x00 0xe61e0000 0x00 0x30>;
			interrupts = <0x00 0x88 0x04 0x00 0x89 0x04 0x00 0x8a 0x04>;
			clocks = <0x0c 0x01 0x7d>;
			clock-names = "fck";
			power-domains = <0x09 0x20>;
			resets = <0x0c 0x7d>;
			status = "disabled";
			phandle = <0xf6>;
		};

		timer@e6fc0000 {
			compatible = "renesas,tmu-r8a7795\0renesas,tmu";
			reg = <0x00 0xe6fc0000 0x00 0x30>;
			interrupts = <0x00 0x80 0x04 0x00 0x81 0x04 0x00 0x82 0x04>;
			clocks = <0x0c 0x01 0x7c>;
			clock-names = "fck";
			power-domains = <0x09 0x20>;
			resets = <0x0c 0x7c>;
			status = "disabled";
			phandle = <0xf7>;
		};

		timer@e6fd0000 {
			compatible = "renesas,tmu-r8a7795\0renesas,tmu";
			reg = <0x00 0xe6fd0000 0x00 0x30>;
			interrupts = <0x00 0x12f 0x04 0x00 0x130 0x04 0x00 0x131 0x04>;
			clocks = <0x0c 0x01 0x7b>;
			clock-names = "fck";
			power-domains = <0x09 0x20>;
			resets = <0x0c 0x7b>;
			status = "disabled";
			phandle = <0xf8>;
		};

		timer@e6fe0000 {
			compatible = "renesas,tmu-r8a7795\0renesas,tmu";
			reg = <0x00 0xe6fe0000 0x00 0x30>;
			interrupts = <0x00 0x83 0x04 0x00 0x84 0x04 0x00 0x85 0x04>;
			clocks = <0x0c 0x01 0x7a>;
			clock-names = "fck";
			power-domains = <0x09 0x20>;
			resets = <0x0c 0x7a>;
			status = "disabled";
			phandle = <0xf9>;
		};

		timer@ffc00000 {
			compatible = "renesas,tmu-r8a7795\0renesas,tmu";
			reg = <0x00 0xffc00000 0x00 0x30>;
			interrupts = <0x00 0x196 0x04 0x00 0x197 0x04 0x00 0x198 0x04>;
			clocks = <0x0c 0x01 0x79>;
			clock-names = "fck";
			power-domains = <0x09 0x20>;
			resets = <0x0c 0x79>;
			status = "disabled";
			phandle = <0xfa>;
		};

		i2c@e6500000 {
			#address-cells = <0x01>;
			#size-cells = <0x00>;
			compatible = "renesas,i2c-r8a7795\0renesas,rcar-gen3-i2c";
			reg = <0x00 0xe6500000 0x00 0x40>;
			interrupts = <0x00 0x11f 0x04>;
			clocks = <0x0c 0x01 0x3a3>;
			power-domains = <0x09 0x20>;
			resets = <0x0c 0x3a3>;
			dmas = <0x1e 0x91 0x1e 0x90 0x1f 0x91 0x1f 0x90>;
			dma-names = "tx\0rx\0tx\0rx";
			i2c-scl-internal-delay-ns = <0x6e>;
			status = "disabled";
			phandle = <0xfb>;
		};

		i2c@e6508000 {
			#address-cells = <0x01>;
			#size-cells = <0x00>;
			compatible = "renesas,i2c-r8a7795\0renesas,rcar-gen3-i2c";
			reg = <0x00 0xe6508000 0x00 0x40>;
			interrupts = <0x00 0x120 0x04>;
			clocks = <0x0c 0x01 0x3a2>;
			power-domains = <0x09 0x20>;
			resets = <0x0c 0x3a2>;
			dmas = <0x1e 0x93 0x1e 0x92 0x1f 0x93 0x1f 0x92>;
			dma-names = "tx\0rx\0tx\0rx";
			i2c-scl-internal-delay-ns = <0x06>;
			status = "disabled";
			phandle = <0xfc>;
		};

		i2c@e6510000 {
			#address-cells = <0x01>;
			#size-cells = <0x00>;
			compatible = "renesas,i2c-r8a7795\0renesas,rcar-gen3-i2c";
			reg = <0x00 0xe6510000 0x00 0x40>;
			interrupts = <0x00 0x11e 0x04>;
			clocks = <0x0c 0x01 0x3a1>;
			power-domains = <0x09 0x20>;
			resets = <0x0c 0x3a1>;
			dmas = <0x1e 0x95 0x1e 0x94 0x1f 0x95 0x1f 0x94>;
			dma-names = "tx\0rx\0tx\0rx";
			i2c-scl-internal-delay-ns = <0x06>;
			status = "okay";
			pinctrl-0 = <0x20>;
			pinctrl-names = "default";
			clock-frequency = <0x186a0>;
			phandle = <0xfd>;

			codec@10 {
				compatible = "asahi-kasei,ak4613";
				#sound-dai-cells = <0x00>;
				reg = <0x10>;
				clocks = <0x21 0x03>;
				asahi-kasei,in1-single-end;
				asahi-kasei,in2-single-end;
				asahi-kasei,out1-single-end;
				asahi-kasei,out2-single-end;
				asahi-kasei,out3-single-end;
				asahi-kasei,out4-single-end;
				asahi-kasei,out5-single-end;
				asahi-kasei,out6-single-end;
				phandle = <0xfe>;

				port {

					endpoint {
						remote-endpoint = <0x22>;
						phandle = <0x80>;
					};
				};
			};

			clk-multiplier@4f {
				#clock-cells = <0x00>;
				compatible = "cirrus,cs2000-cp";
				reg = <0x4f>;
				clocks = <0x23 0x24>;
				clock-names = "clk_in\0ref_clk";
				assigned-clocks = <0x25>;
				assigned-clock-rates = <0x1770000>;
				phandle = <0x25>;
			};

			i2c-switch@71 {
				compatible = "nxp,pca9548";
				#address-cells = <0x01>;
				#size-cells = <0x00>;
				reg = <0x71>;
				reset-gpios = <0x26 0x03 0x01>;
				i2c-mux-idle-disconnect;
				phandle = <0xff>;

				i2c@0 {
					#address-cells = <0x01>;
					#size-cells = <0x00>;
					reg = <0x00>;
				};

				i2c@1 {
					#address-cells = <0x01>;
					#size-cells = <0x00>;
					reg = <0x01>;
				};

				i2c@2 {
					#address-cells = <0x01>;
					#size-cells = <0x00>;
					reg = <0x02>;
				};

				i2c@3 {
					#address-cells = <0x01>;
					#size-cells = <0x00>;
					reg = <0x03>;
				};

				i2c@4 {
					#address-cells = <0x01>;
					#size-cells = <0x00>;
					reg = <0x04>;

					hdmi@3d {
						compatible = "adi,adv7513";
						reg = <0x3d>;
						pd-gpios = <0x27 0x05 0x01>;
						interlace-allowed;
						adi,input-depth = <0x08>;
						adi,input-colorspace = "rgb";
						adi,input-clock = "1x";
						adi,input-style = <0x01>;
						adi,input-justification = "evenly";
						adi,clock-delay = <0x4b0>;
						limit-frequency = <0x5f5e100>;

						ports {
							#address-cells = <0x01>;
							#size-cells = <0x00>;

							port@0 {
								reg = <0x00>;

								endpoint {
									remote-endpoint = <0x28>;
									phandle = <0xd5>;
								};
							};

							port@1 {
								reg = <0x01>;

								endpoint {
									remote-endpoint = <0x29>;
									phandle = <0xe6>;
								};
							};
						};
					};
				};

				i2c@5 {
					#address-cells = <0x01>;
					#size-cells = <0x00>;
					reg = <0x05>;
				};

				i2c@6 {
					#address-cells = <0x01>;
					#size-cells = <0x00>;
					reg = <0x06>;

					edt-ft5x06@38 {
						compatible = "edt,edt-ft5x06";
						reg = <0x38>;
						interrupt-parent = <0x26>;
						interrupts = <0x06 0x02>;
						phandle = <0x100>;
					};
				};

				i2c@7 {
					#address-cells = <0x01>;
					#size-cells = <0x00>;
					reg = <0x07>;

					audio-codec@44 {
						#sound-dai-cells = <0x00>;
						compatible = "ti,pcm3168a";
						reg = <0x44>;
						clocks = <0x2a>;
						clock-names = "scki";
						tdm;
						VDD1-supply = <0x2b>;
						VDD2-supply = <0x2b>;
						VCCAD1-supply = <0x2c>;
						VCCAD2-supply = <0x2c>;
						VCCDA1-supply = <0x2c>;
						VCCDA2-supply = <0x2c>;
						phandle = <0x101>;

						port {

							endpoint {
								remote-endpoint = <0x2d>;
								clocks = <0x2a>;
								phandle = <0x8a>;
							};
						};
					};

					lsm9ds0_acc_mag@1d {
						compatible = "st,lsm9ds0-imu";
						reg = <0x1d>;
					};

					lsm9ds0_gyr@6b {
						compatible = "st,lsm9ds0-gyro";
						reg = <0x6b>;
					};
				};
			};

			gpio@74 {
				compatible = "ti,tca9539";
				reg = <0x74>;
				gpio-controller;
				#gpio-cells = <0x02>;
				phandle = <0x4a>;

				audio-out-off-hog {
					gpio-hog;
					gpios = <0x00 0x00>;
					output-high;
					line-name = "Audio_Out_OFF";
				};

				hub-pwen-hog {
					gpio-hog;
					gpios = <0x06 0x00>;
					output-high;
					line-name = "HUB pwen";
				};

				hub-rst-hog {
					gpio-hog;
					gpios = <0x07 0x00>;
					output-high;
					line-name = "HUB rst";
				};

				otg-extlpn-hog {
					gpio-hog;
					gpios = <0x09 0x00>;
					output-high;
					line-name = "OTG EXTLPn";
				};

				otg-offvbusn-hog {
					gpio-hog;
					gpios = <0x08 0x00>;
					output-low;
					line-name = "OTG OFFVBUSn";
				};

				snd-rst-hog {
					gpio-hog;
					gpios = <0x0f 0x00>;
					output-high;
					line-name = "SND_RST";
				};
			};

			gpio@75 {
				compatible = "ti,tca9539";
				reg = <0x75>;
				gpio-controller;
				#gpio-cells = <0x02>;
				interrupt-controller;
				interrupt-parent = <0x2e>;
				interrupts = <0x04 0x02>;
				phandle = <0x27>;

				gps_rst {
					gpio-hog;
					gpios = <0x06 0x00>;
					output-high;
					line-name = "GPS rst";
				};

				fpdl_shdn {
					gpio-hog;
					gpios = <0x09 0x00>;
					output-high;
					line-name = "FPDLink shdn";
				};
			};
		};

		i2c@e66d0000 {
			#address-cells = <0x01>;
			#size-cells = <0x00>;
			compatible = "renesas,i2c-r8a7795\0renesas,rcar-gen3-i2c";
			reg = <0x00 0xe66d0000 0x00 0x40>;
			interrupts = <0x00 0x122 0x04>;
			clocks = <0x0c 0x01 0x3a0>;
			power-domains = <0x09 0x20>;
			resets = <0x0c 0x3a0>;
			dmas = <0x2f 0x97 0x2f 0x96>;
			dma-names = "tx\0rx";
			i2c-scl-internal-delay-ns = <0x6e>;
			status = "disabled";
			phandle = <0x102>;
		};

		i2c@e66d8000 {
			#address-cells = <0x01>;
			#size-cells = <0x00>;
			compatible = "renesas,i2c-r8a7795\0renesas,rcar-gen3-i2c";
			reg = <0x00 0xe66d8000 0x00 0x40>;
			interrupts = <0x00 0x13 0x04>;
			clocks = <0x0c 0x01 0x39f>;
			power-domains = <0x09 0x20>;
			resets = <0x0c 0x39f>;
			dmas = <0x2f 0x99 0x2f 0x98>;
			dma-names = "tx\0rx";
			i2c-scl-internal-delay-ns = <0x6e>;
			status = "okay";
			clock-frequency = <0x61a80>;
			phandle = <0x103>;

			clock-generator@6a {
				compatible = "idt,5p49v5925";
				reg = <0x6a>;
				#clock-cells = <0x01>;
				clocks = <0x30>;
				clock-names = "xin";
				phandle = <0xca>;
			};

			i2c-switch@71 {
				compatible = "nxp,pca9548";
				#address-cells = <0x01>;
				#size-cells = <0x00>;
				reg = <0x71>;
				reset-gpios = <0x31 0x0f 0x01>;
				phandle = <0x104>;

				i2c@0 {
					#address-cells = <0x01>;
					#size-cells = <0x00>;
					reg = <0x00>;
				};

				i2c@1 {
					#address-cells = <0x01>;
					#size-cells = <0x00>;
					reg = <0x01>;
					phandle = <0x105>;

					deser@2c {
						compatible = "maxim,max9286\0ti,ub9x4";
						#address-cells = <0x01>;
						#size-cells = <0x00>;
						reg = <0x2c 0x3a>;
						reg-names = "max9286\0ub9x4";
						regs = <0x0c 0x0d 0x0e 0x0f>;
						maxim,sensor_delay = <0x15e>;
						shutdown-gpios = <0x32 0x0d 0x01>;
						poc0-supply = <0x33>;
						poc1-supply = <0x34>;
						poc2-supply = <0x35>;
						poc3-supply = <0x36>;

						ports {
							#address-cells = <0x01>;
							#size-cells = <0x00>;

							port@0 {
								reg = <0x00>;

								endpoint {
									remote-endpoint = <0x37>;
									phandle = <0x3c>;
								};
							};

							port@1 {
								reg = <0x01>;

								endpoint {
									remote-endpoint = <0x38>;
									phandle = <0x3d>;
								};
							};

							port@2 {
								reg = <0x02>;

								endpoint {
									remote-endpoint = <0x39>;
									phandle = <0x3e>;
								};
							};

							port@3 {
								reg = <0x03>;

								endpoint {
									remote-endpoint = <0x3a>;
									phandle = <0x3f>;
								};
							};

							port@4 {
								reg = <0x04>;

								endpoint {
									clock-lanes = <0x00>;
									data-lanes = <0x01 0x02 0x03 0x04>;
									remote-endpoint = <0x3b>;
									phandle = <0xbe>;
								};
							};
						};

						i2c@0 {
							#address-cells = <0x01>;
							#size-cells = <0x00>;
							reg = <0x00>;

							camera@60 {
								compatible = "ovti,ov490";
								group = <0x05>;
								reg = <0x60 0x0c>;

								port {

									endpoint {
										remote-endpoint = <0x3c>;
										phandle = <0x37>;
									};
								};
							};
						};

						i2c@1 {
							#address-cells = <0x01>;
							#size-cells = <0x00>;
							reg = <0x01>;

							camera@61 {
								compatible = "ovti,ov490";
								group = <0x05>;
								reg = <0x61 0x0d>;

								port {

									endpoint {
										remote-endpoint = <0x3d>;
										phandle = <0x38>;
									};
								};
							};
						};

						i2c@2 {
							#address-cells = <0x01>;
							#size-cells = <0x00>;
							reg = <0x02>;

							camera@62 {
								compatible = "ovti,ov490";
								group = <0x05>;
								reg = <0x62 0x0e>;

								port {

									endpoint {
										remote-endpoint = <0x3e>;
										phandle = <0x39>;
									};
								};
							};
						};

						i2c@3 {
							#address-cells = <0x01>;
							#size-cells = <0x00>;
							reg = <0x03>;

							camera@63 {
								compatible = "ovti,ov490";
								group = <0x05>;
								reg = <0x63 0x0f>;

								port {

									endpoint {
										remote-endpoint = <0x3f>;
										phandle = <0x3a>;
									};
								};
							};
						};
					};
				};

				i2c@3 {
					#address-cells = <0x01>;
					#size-cells = <0x00>;
					reg = <0x03>;
				};

				i2c@4 {
					#address-cells = <0x01>;
					#size-cells = <0x00>;
					reg = <0x04>;

					ov5647@36 {
						compatible = "ovti,ov5647";
						reg = <0x36>;
						clocks = <0x40>;
						phandle = <0x106>;

						port@0 {

							endpoint {
								clock-lanes = <0x00>;
								data-lanes = <0x01 0x02>;
								remote-endpoint = <0x41>;
								phandle = <0xb5>;
							};
						};
					};
				};

				i2c@5 {
					#address-cells = <0x01>;
					#size-cells = <0x00>;
					reg = <0x05>;

					ov5642@3c {
						compatible = "ovti,ov5642";
						reg = <0x3c>;
						clocks = <0x42>;
						clock-names = "mclk";
						pwdn-gpios = <0x43 0x08 0x00>;
						resetb-gpios = <0x43 0x09 0x00>;
						phandle = <0x107>;

						port@0 {

							endpoint {
								remote-endpoint = <0x44>;
								phandle = <0x6c>;
							};
						};
					};
				};

				i2c@7 {
					#address-cells = <0x01>;
					#size-cells = <0x00>;
					reg = <0x07>;
					phandle = <0x108>;

					gpio@5c {
						compatible = "maxim,max7325";
						reg = <0x5c>;
						gpio-controller;
						#gpio-cells = <0x02>;
						phandle = <0x32>;

						video_a_des_cfg2 {
							gpio-hog;
							gpios = <0x04 0x00>;
							input;
							line-name = "Video-A cfg2";
						};

						video_a_des_cfg1 {
							gpio-hog;
							gpios = <0x06 0x00>;
							input;
							line-name = "Video-A cfg1";
						};

						video_a_des_cfg0 {
							gpio-hog;
							gpios = <0x07 0x00>;
							input;
							line-name = "Video-A cfg0";
						};

						video_a_pwr_shdn {
							gpio-hog;
							gpios = <0x0e 0x00>;
							output-high;
							line-name = "Video-A PWR_SHDN";
						};

						video_a_led {
							gpio-hog;
							gpios = <0x0c 0x00>;
							output-low;
							line-name = "Video-A LED";
						};
					};
				};
			};

			gpio@76 {
				compatible = "ti,tca9539";
				reg = <0x76>;
				gpio-controller;
				#gpio-cells = <0x02>;
				interrupt-controller;
				interrupt-parent = <0x45>;
				interrupts = <0x03 0x02>;
				phandle = <0x43>;

				port_b_a0 {
					gpio-hog;
					gpios = <0x00 0x00>;
					output-low;
					line-name = "Video-B A0";
				};

				port_b_a1 {
					gpio-hog;
					gpios = <0x01 0x00>;
					output-high;
					line-name = "Video-B A1";
				};

				port_a_a0 {
					gpio-hog;
					gpios = <0x02 0x00>;
					output-low;
					line-name = "Video-A A0";
				};

				port_a_a1 {
					gpio-hog;
					gpios = <0x03 0x00>;
					output-high;
					line-name = "Video-A A1";
				};

				rpi_cam_io_1 {
					gpio-hog;
					gpios = <0x0a 0x00>;
					output-high;
					line-name = "RaspB_IO1";
				};

				rpi_cam_io_0 {
					gpio-hog;
					gpios = <0x0b 0x00>;
					output-high;
					line-name = "RaspB_IO0";
				};

				sam_rst {
					gpio-hog;
					gpios = <0x04 0x00>;
					output-high;
					line-name = "SAM RST";
				};

				sam_pwr {
					gpio-hog;
					gpios = <0x05 0x00>;
					output-low;
					line-name = "SAM PWR";
				};

				lvds_vs_fpdl {
					gpio-hog;
					gpios = <0x0e 0x00>;
					output-high;
					line-name = "LVDS switch";
				};
			};

			gpio@77 {
				compatible = "ti,tca9539";
				reg = <0x77>;
				gpio-controller;
				#gpio-cells = <0x02>;
				phandle = <0xdf>;

				mpcie_wake {
					gpio-hog;
					gpios = <0x00 0x00>;
					output-low;
					line-name = "mPCIe WAKE#";
				};

				mpcie_wdisable {
					gpio-hog;
					gpios = <0x01 0x00>;
					output-high;
					line-name = "mPCIe W_DISABLE";
				};

				mpcie_clreq {
					gpio-hog;
					gpios = <0x02 0x00>;
					input;
					line-name = "mPCIe CLKREQ#";
				};

				mpcie_ovc {
					gpio-hog;
					gpios = <0x03 0x00>;
					input;
					line-name = "mPCIe OVC";
				};
			};
		};

		i2c@e66e0000 {
			#address-cells = <0x01>;
			#size-cells = <0x00>;
			compatible = "renesas,i2c-r8a7795\0renesas,rcar-gen3-i2c";
			reg = <0x00 0xe66e0000 0x00 0x40>;
			interrupts = <0x00 0x14 0x04>;
			clocks = <0x0c 0x01 0x397>;
			power-domains = <0x09 0x20>;
			resets = <0x0c 0x397>;
			dmas = <0x2f 0x9b 0x2f 0x9a>;
			dma-names = "tx\0rx";
			i2c-scl-internal-delay-ns = <0x6e>;
			status = "disabled";
			phandle = <0x109>;
		};

		i2c@e66e8000 {
			#address-cells = <0x01>;
			#size-cells = <0x00>;
			compatible = "renesas,i2c-r8a7795\0renesas,rcar-gen3-i2c";
			reg = <0x00 0xe66e8000 0x00 0x40>;
			interrupts = <0x00 0x15 0x04>;
			clocks = <0x0c 0x01 0x396>;
			power-domains = <0x09 0x20>;
			resets = <0x0c 0x396>;
			dmas = <0x2f 0x9d 0x2f 0x9c>;
			dma-names = "tx\0rx";
			i2c-scl-internal-delay-ns = <0x06>;
			status = "disabled";
			phandle = <0x10a>;
		};

		i2c@e60b0000 {
			#address-cells = <0x01>;
			#size-cells = <0x00>;
			compatible = "renesas,iic-r8a7795\0renesas,rcar-gen3-iic\0renesas,rmobile-iic";
			reg = <0x00 0xe60b0000 0x00 0x425>;
			interrupts = <0x00 0xad 0x04>;
			clocks = <0x0c 0x01 0x39e>;
			power-domains = <0x09 0x20>;
			resets = <0x0c 0x39e>;
			dmas = <0x2f 0x11 0x2f 0x10>;
			dma-names = "tx\0rx";
			status = "okay";
			clock-frequency = <0x61a80>;
			phandle = <0x10b>;

			pmic@30 {
				pinctrl-0 = <0x46>;
				pinctrl-names = "default";
				compatible = "rohm,bd9571mwv";
				reg = <0x30>;
				interrupt-parent = <0x47>;
				interrupts = <0x00 0x08>;
				interrupt-controller;
				#interrupt-cells = <0x02>;
				gpio-controller;
				#gpio-cells = <0x02>;
				rohm,ddr-backup-power = <0x0f>;
				rohm,rstbmode-pulse;
				phandle = <0x10c>;

				regulators {

					dvfs {
						regulator-name = "dvfs";
						regulator-min-microvolt = <0xb71b0>;
						regulator-max-microvolt = <0xfb770>;
						regulator-boot-on;
						regulator-always-on;
						phandle = <0x15>;
					};
				};
			};
		};

		serial@e6540000 {
			compatible = "renesas,hscif-r8a7795\0renesas,rcar-gen3-hscif\0renesas,hscif";
			reg = <0x00 0xe6540000 0x00 0x60>;
			interrupts = <0x00 0x9a 0x04>;
			clocks = <0x0c 0x01 0x208 0x0c 0x00 0x10 0x48>;
			clock-names = "fck\0brg_int\0scif_clk";
			dmas = <0x1e 0x31 0x1e 0x30 0x1f 0x31 0x1f 0x30>;
			dma-names = "tx\0rx\0tx\0rx";
			power-domains = <0x09 0x20>;
			resets = <0x0c 0x208>;
			status = "okay";
			pinctrl-0 = <0x49>;
			pinctrl-names = "default";
			uart-has-rtscts;
			phandle = <0x10d>;

			bluetooth {
				compatible = "ti,wl1837-st";
				enable-gpios = <0x4a 0x03 0x00>;
			};
		};

		serial@e6550000 {
			compatible = "renesas,hscif-r8a7795\0renesas,rcar-gen3-hscif\0renesas,hscif";
			reg = <0x00 0xe6550000 0x00 0x60>;
			interrupts = <0x00 0x9b 0x04>;
			clocks = <0x0c 0x01 0x207 0x0c 0x00 0x10 0x48>;
			clock-names = "fck\0brg_int\0scif_clk";
			dmas = <0x1e 0x33 0x1e 0x32 0x1f 0x33 0x1f 0x32>;
			dma-names = "tx\0rx\0tx\0rx";
			power-domains = <0x09 0x20>;
			resets = <0x0c 0x207>;
			status = "okay";
			pinctrl-0 = <0x4b>;
			pinctrl-names = "default";
			phandle = <0x10e>;
		};

		serial@e6560000 {
			compatible = "renesas,hscif-r8a7795\0renesas,rcar-gen3-hscif\0renesas,hscif";
			reg = <0x00 0xe6560000 0x00 0x60>;
			interrupts = <0x00 0x90 0x04>;
			clocks = <0x0c 0x01 0x206 0x0c 0x00 0x10 0x48>;
			clock-names = "fck\0brg_int\0scif_clk";
			dmas = <0x1e 0x35 0x1e 0x34 0x1f 0x35 0x1f 0x34>;
			dma-names = "tx\0rx\0tx\0rx";
			power-domains = <0x09 0x20>;
			resets = <0x0c 0x206>;
			status = "disabled";
			phandle = <0x10f>;
		};

		serial@e66a0000 {
			compatible = "renesas,hscif-r8a7795\0renesas,rcar-gen3-hscif\0renesas,hscif";
			reg = <0x00 0xe66a0000 0x00 0x60>;
			interrupts = <0x00 0x91 0x04>;
			clocks = <0x0c 0x01 0x205 0x0c 0x00 0x10 0x48>;
			clock-names = "fck\0brg_int\0scif_clk";
			dmas = <0x2f 0x37 0x2f 0x36>;
			dma-names = "tx\0rx";
			power-domains = <0x09 0x20>;
			resets = <0x0c 0x205>;
			status = "disabled";
			phandle = <0x110>;
		};

		serial@e66b0000 {
			compatible = "renesas,hscif-r8a7795\0renesas,rcar-gen3-hscif\0renesas,hscif";
			reg = <0x00 0xe66b0000 0x00 0x60>;
			interrupts = <0x00 0x92 0x04>;
			clocks = <0x0c 0x01 0x204 0x0c 0x00 0x10 0x48>;
			clock-names = "fck\0brg_int\0scif_clk";
			dmas = <0x2f 0x39 0x2f 0x38>;
			dma-names = "tx\0rx";
			power-domains = <0x09 0x20>;
			resets = <0x0c 0x204>;
			status = "disabled";
			phandle = <0x111>;
		};

		usb@e6590000 {
			compatible = "renesas,usbhs-r8a7795\0renesas,rcar-gen3-usbhs";
			reg = <0x00 0xe6590000 0x00 0x200>;
			interrupts = <0x00 0x6b 0x04>;
			clocks = <0x0c 0x01 0x2c0 0x0c 0x01 0x2bf>;
			dmas = <0x4c 0x00 0x4c 0x01 0x4d 0x00 0x4d 0x01>;
			dma-names = "ch0\0ch1\0ch2\0ch3";
			renesas,buswait = <0x0b>;
			phys = <0x4e 0x03>;
			phy-names = "usb";
			power-domains = <0x09 0x20>;
			resets = <0x0c 0x2c0 0x0c 0x2bf>;
			status = "okay";
			dr_mode = "otg";
			phandle = <0x112>;
		};

		usb@e659c000 {
			compatible = "renesas,usbhs-r8a7795\0renesas,rcar-gen3-usbhs";
			reg = <0x00 0xe659c000 0x00 0x200>;
			interrupts = <0x00 0x25 0x04>;
			clocks = <0x0c 0x01 0x2c1 0x0c 0x01 0x2bc>;
			dmas = <0x4f 0x00 0x4f 0x01 0x50 0x00 0x50 0x01>;
			dma-names = "ch0\0ch1\0ch2\0ch3";
			renesas,buswait = <0x0b>;
			phys = <0x51 0x03>;
			phy-names = "usb";
			power-domains = <0x09 0x20>;
			resets = <0x0c 0x2c1 0x0c 0x2bc>;
			status = "disabled";
			phandle = <0x113>;
		};

		dma-controller@e65a0000 {
			compatible = "renesas,r8a7795-usb-dmac\0renesas,usb-dmac";
			reg = <0x00 0xe65a0000 0x00 0x100>;
			interrupts = <0x00 0x6d 0x04 0x00 0x6d 0x04>;
			interrupt-names = "ch0\0ch1";
			clocks = <0x0c 0x01 0x14a>;
			power-domains = <0x09 0x20>;
			resets = <0x0c 0x14a>;
			#dma-cells = <0x01>;
			dma-channels = <0x02>;
			phandle = <0x4c>;
		};

		dma-controller@e65b0000 {
			compatible = "renesas,r8a7795-usb-dmac\0renesas,usb-dmac";
			reg = <0x00 0xe65b0000 0x00 0x100>;
			interrupts = <0x00 0x6e 0x04 0x00 0x6e 0x04>;
			interrupt-names = "ch0\0ch1";
			clocks = <0x0c 0x01 0x14b>;
			power-domains = <0x09 0x20>;
			resets = <0x0c 0x14b>;
			#dma-cells = <0x01>;
			dma-channels = <0x02>;
			phandle = <0x4d>;
		};

		dma-controller@e6460000 {
			compatible = "renesas,r8a7795-usb-dmac\0renesas,usb-dmac";
			reg = <0x00 0xe6460000 0x00 0x100>;
			interrupts = <0x00 0x22 0x04 0x00 0x22 0x04>;
			interrupt-names = "ch0\0ch1";
			clocks = <0x0c 0x01 0x146>;
			power-domains = <0x09 0x20>;
			resets = <0x0c 0x146>;
			#dma-cells = <0x01>;
			dma-channels = <0x02>;
			phandle = <0x4f>;
		};

		dma-controller@e6470000 {
			compatible = "renesas,r8a7795-usb-dmac\0renesas,usb-dmac";
			reg = <0x00 0xe6470000 0x00 0x100>;
			interrupts = <0x00 0x23 0x04 0x00 0x23 0x04>;
			interrupt-names = "ch0\0ch1";
			clocks = <0x0c 0x01 0x149>;
			power-domains = <0x09 0x20>;
			resets = <0x0c 0x149>;
			#dma-cells = <0x01>;
			dma-channels = <0x02>;
			phandle = <0x50>;
		};

		usb-phy@e65ee000 {
			compatible = "renesas,r8a7795-usb3-phy\0renesas,rcar-gen3-usb3-phy";
			reg = <0x00 0xe65ee000 0x00 0x90>;
			clocks = <0x0c 0x01 0x148 0x52 0x53>;
			clock-names = "usb3-if\0usb3s_clk\0usb_extal";
			power-domains = <0x09 0x20>;
			resets = <0x0c 0x148>;
			#phy-cells = <0x00>;
			status = "disabled";
			phandle = <0x114>;
		};

		crypto@e6601000 {
			compatible = "arm,cryptocell-630p-ree";
			interrupts = <0x00 0x47 0x04>;
			reg = <0x00 0xe6601000 0x00 0x1000>;
			power-domains = <0x09 0x20>;
			phandle = <0x115>;
		};

		dma-controller@e6700000 {
			compatible = "renesas,dmac-r8a7795\0renesas,rcar-dmac";
			reg = <0x00 0xe6700000 0x00 0x10000>;
			interrupts = <0x00 0xc7 0x04 0x00 0xc8 0x04 0x00 0xc9 0x04 0x00 0xca 0x04 0x00 0xcb 0x04 0x00 0xcc 0x04 0x00 0xcd 0x04 0x00 0xce 0x04 0x00 0xcf 0x04 0x00 0xd0 0x04 0x00 0xd1 0x04 0x00 0xd2 0x04 0x00 0xd3 0x04 0x00 0xd4 0x04 0x00 0xd5 0x04 0x00 0xd6 0x04 0x00 0xd7 0x04>;
			interrupt-names = "error\0ch0\0ch1\0ch2\0ch3\0ch4\0ch5\0ch6\0ch7\0ch8\0ch9\0ch10\0ch11\0ch12\0ch13\0ch14\0ch15";
			clocks = <0x0c 0x01 0xdb>;
			clock-names = "fck";
			power-domains = <0x09 0x20>;
			resets = <0x0c 0xdb>;
			#dma-cells = <0x01>;
			dma-channels = <0x10>;
			phandle = <0x2f>;
		};

		dma-controller@e7300000 {
			compatible = "renesas,dmac-r8a7795\0renesas,rcar-dmac";
			reg = <0x00 0xe7300000 0x00 0x10000>;
			interrupts = <0x00 0xdc 0x04 0x00 0xd8 0x04 0x00 0xd9 0x04 0x00 0xda 0x04 0x00 0xdb 0x04 0x00 0x134 0x04 0x00 0x135 0x04 0x00 0x136 0x04 0x00 0x137 0x04 0x00 0x138 0x04 0x00 0x139 0x04 0x00 0x13a 0x04 0x00 0x13b 0x04 0x00 0x13c 0x04 0x00 0x13d 0x04 0x00 0x13e 0x04 0x00 0x13f 0x04>;
			interrupt-names = "error\0ch0\0ch1\0ch2\0ch3\0ch4\0ch5\0ch6\0ch7\0ch8\0ch9\0ch10\0ch11\0ch12\0ch13\0ch14\0ch15";
			clocks = <0x0c 0x01 0xda>;
			clock-names = "fck";
			power-domains = <0x09 0x20>;
			resets = <0x0c 0xda>;
			#dma-cells = <0x01>;
			dma-channels = <0x10>;
			phandle = <0x1e>;
		};

		dma-controller@e7310000 {
			compatible = "renesas,dmac-r8a7795\0renesas,rcar-dmac";
			reg = <0x00 0xe7310000 0x00 0x10000>;
			interrupts = <0x00 0x1a0 0x04 0x00 0x1a1 0x04 0x00 0x1a2 0x04 0x00 0x1a3 0x04 0x00 0x1a4 0x04 0x00 0x1a5 0x04 0x00 0x1a6 0x04 0x00 0x1a7 0x04 0x00 0x1a8 0x04 0x00 0x1a9 0x04 0x00 0x1aa 0x04 0x00 0x1ab 0x04 0x00 0x1ac 0x04 0x00 0x1ad 0x04 0x00 0x1ae 0x04 0x00 0x1af 0x04 0x00 0x18d 0x04>;
			interrupt-names = "error\0ch0\0ch1\0ch2\0ch3\0ch4\0ch5\0ch6\0ch7\0ch8\0ch9\0ch10\0ch11\0ch12\0ch13\0ch14\0ch15";
			clocks = <0x0c 0x01 0xd9>;
			clock-names = "fck";
			power-domains = <0x09 0x20>;
			resets = <0x0c 0xd9>;
			#dma-cells = <0x01>;
			dma-channels = <0x10>;
			phandle = <0x1f>;
		};

		iommu@e67b0000 {
			compatible = "renesas,ipmmu-r8a7795";
			reg = <0x00 0xe67b0000 0x00 0x1000>;
			interrupts = <0x00 0xc4 0x04 0x00 0xc5 0x04>;
			power-domains = <0x09 0x20>;
			#iommu-cells = <0x01>;
			phandle = <0x54>;
		};

		iommu@e6740000 {
			compatible = "renesas,ipmmu-r8a7795";
			reg = <0x00 0xe6740000 0x00 0x1000>;
			renesas,ipmmu-main = <0x54 0x00>;
			power-domains = <0x09 0x20>;
			#iommu-cells = <0x01>;
			status = "disabled";
			phandle = <0x116>;
		};

		iommu@e7740000 {
			compatible = "renesas,ipmmu-r8a7795";
			reg = <0x00 0xe7740000 0x00 0x1000>;
			renesas,ipmmu-main = <0x54 0x01>;
			power-domains = <0x09 0x20>;
			#iommu-cells = <0x01>;
			phandle = <0x9f>;
		};

		iommu@e6570000 {
			compatible = "renesas,ipmmu-r8a7795";
			reg = <0x00 0xe6570000 0x00 0x1000>;
			renesas,ipmmu-main = <0x54 0x02>;
			power-domains = <0x09 0x20>;
			#iommu-cells = <0x01>;
			status = "disabled";
			phandle = <0x117>;
		};

		iommu@ff8b0000 {
			compatible = "renesas,ipmmu-r8a7795";
			reg = <0x00 0xff8b0000 0x00 0x1000>;
			renesas,ipmmu-main = <0x54 0x03>;
			power-domains = <0x09 0x18>;
			#iommu-cells = <0x01>;
			status = "disabled";
			phandle = <0x118>;
		};

		iommu@ec670000 {
			compatible = "renesas,ipmmu-r8a7795";
			reg = <0x00 0xec670000 0x00 0x1000>;
			renesas,ipmmu-main = <0x54 0x04>;
			power-domains = <0x09 0x20>;
			#iommu-cells = <0x01>;
			status = "disabled";
			phandle = <0x119>;
		};

		iommu@fd800000 {
			compatible = "renesas,ipmmu-r8a7795";
			reg = <0x00 0xfd800000 0x00 0x1000>;
			renesas,ipmmu-main = <0x54 0x06>;
			power-domains = <0x09 0x20>;
			#iommu-cells = <0x01>;
			status = "disabled";
			phandle = <0x11a>;
		};

		iommu@fd950000 {
			compatible = "renesas,ipmmu-r8a7795";
			reg = <0x00 0xfd950000 0x00 0x1000>;
			renesas,ipmmu-main = <0x54 0x07>;
			power-domains = <0x09 0x20>;
			#iommu-cells = <0x01>;
			status = "disabled";
			phandle = <0x11b>;
		};

		iommu@fd960000 {
			compatible = "renesas,ipmmu-r8a7795";
			reg = <0x00 0xfd960000 0x00 0x1000>;
			renesas,ipmmu-main = <0x54 0x08>;
			power-domains = <0x09 0x20>;
			#iommu-cells = <0x01>;
			status = "disabled";
			phandle = <0x11c>;
		};

		iommu@fd970000 {
			compatible = "renesas,ipmmu-r8a7795";
			reg = <0x00 0xfd970000 0x00 0x1000>;
			renesas,ipmmu-main = <0x54 0x09>;
			power-domains = <0x09 0x20>;
			#iommu-cells = <0x01>;
			status = "disabled";
			phandle = <0x11d>;
		};

		iommu@ffc80000 {
			compatible = "renesas,ipmmu-r8a7795";
			reg = <0x00 0xffc80000 0x00 0x1000>;
			renesas,ipmmu-main = <0x54 0x0a>;
			power-domains = <0x09 0x20>;
			#iommu-cells = <0x01>;
			status = "disabled";
			phandle = <0x11e>;
		};

		iommu@fe6b0000 {
			compatible = "renesas,ipmmu-mmu-r8a7795";
			reg = <0x00 0xfe6b0000 0x00 0x1000>;
			renesas,ipmmu-main = <0x54 0x0c>;
			power-domains = <0x09 0x0e>;
			#iommu-cells = <0x01>;
			status = "disabled";
			phandle = <0x11f>;
		};

		iommu@fe6f0000 {
			compatible = "renesas,ipmmu-mmu-r8a7795";
			reg = <0x00 0xfe6f0000 0x00 0x1000>;
			renesas,ipmmu-main = <0x54 0x0d>;
			power-domains = <0x09 0x0e>;
			#iommu-cells = <0x01>;
			status = "disabled";
			phandle = <0x120>;
		};

		iommu@febd0000 {
			compatible = "renesas,ipmmu-r8a7795";
			reg = <0x00 0xfebd0000 0x00 0x1000>;
			renesas,ipmmu-main = <0x54 0x0e>;
			power-domains = <0x09 0x20>;
			#iommu-cells = <0x01>;
			phandle = <0x121>;
		};

		iommu@febe0000 {
			compatible = "renesas,ipmmu-r8a7795";
			reg = <0x00 0xfebe0000 0x00 0x1000>;
			renesas,ipmmu-main = <0x54 0x0f>;
			power-domains = <0x09 0x20>;
			#iommu-cells = <0x01>;
			status = "disabled";
			phandle = <0x122>;
		};

		iommu@fe990000 {
			compatible = "renesas,ipmmu-mmu-r8a7795";
			reg = <0x00 0xfe990000 0x00 0x1000>;
			renesas,ipmmu-main = <0x54 0x10>;
			power-domains = <0x09 0x09>;
			#iommu-cells = <0x01>;
			status = "disabled";
			phandle = <0x123>;
		};

		iommu@fe980000 {
			compatible = "renesas,ipmmu-mmu-r8a7795";
			reg = <0x00 0xfe980000 0x00 0x1000>;
			renesas,ipmmu-main = <0x54 0x11>;
			power-domains = <0x09 0x09>;
			#iommu-cells = <0x01>;
			phandle = <0x124>;
		};

		qos@e67e0000 {
			compatible = "renesas,qos";
			reg = <0x00 0xe67e0000 0x00 0x10090>;
		};

		ethernet@e6800000 {
			compatible = "renesas,etheravb-r8a7795\0renesas,etheravb-rcar-gen3";
			reg = <0x00 0xe6800000 0x00 0x800 0x00 0xe6a00000 0x00 0x10000>;
			interrupts = <0x00 0x27 0x04 0x00 0x28 0x04 0x00 0x29 0x04 0x00 0x2a 0x04 0x00 0x2b 0x04 0x00 0x2c 0x04 0x00 0x2d 0x04 0x00 0x2e 0x04 0x00 0x2f 0x04 0x00 0x30 0x04 0x00 0x31 0x04 0x00 0x32 0x04 0x00 0x33 0x04 0x00 0x34 0x04 0x00 0x35 0x04 0x00 0x36 0x04 0x00 0x37 0x04 0x00 0x38 0x04 0x00 0x39 0x04 0x00 0x3a 0x04 0x00 0x3b 0x04 0x00 0x3c 0x04 0x00 0x3d 0x04 0x00 0x3e 0x04 0x00 0x3f 0x04>;
			interrupt-names = "ch0\0ch1\0ch2\0ch3\0ch4\0ch5\0ch6\0ch7\0ch8\0ch9\0ch10\0ch11\0ch12\0ch13\0ch14\0ch15\0ch16\0ch17\0ch18\0ch19\0ch20\0ch21\0ch22\0ch23\0ch24";
			clocks = <0x0c 0x01 0x32c>;
			power-domains = <0x09 0x20>;
			resets = <0x0c 0x32c>;
			phy-mode = "rgmii";
			rx-internal-delay-ps = <0x00>;
			tx-internal-delay-ps = <0x7d0>;
			#address-cells = <0x01>;
			#size-cells = <0x00>;
			status = "okay";
			pinctrl-0 = <0x55>;
			pinctrl-names = "default";
			phy-handle = <0x56>;
			phandle = <0x125>;

			ethernet-phy@0 {
				rxc-skew-ps = <0x5dc>;
				reg = <0x00>;
				interrupt-parent = <0x57>;
				interrupts = <0x0b 0x08>;
				reset-gpios = <0x57 0x0a 0x01>;
				phandle = <0x56>;
			};
		};

		can@e6c30000 {
			compatible = "renesas,can-r8a7795\0renesas,rcar-gen3-can";
			reg = <0x00 0xe6c30000 0x00 0x1000>;
			interrupts = <0x00 0xba 0x04>;
			clocks = <0x0c 0x01 0x394 0x0c 0x00 0x27 0x58>;
			clock-names = "clkp1\0clkp2\0can_clk";
			assigned-clocks = <0x0c 0x00 0x27>;
			assigned-clock-rates = <0x2625a00>;
			power-domains = <0x09 0x20>;
			resets = <0x0c 0x394>;
			status = "okay";
			pinctrl-0 = <0x59>;
			pinctrl-names = "default";
			phandle = <0x126>;
		};

		can@e6c38000 {
			compatible = "renesas,can-r8a7795\0renesas,rcar-gen3-can";
			reg = <0x00 0xe6c38000 0x00 0x1000>;
			interrupts = <0x00 0xbb 0x04>;
			clocks = <0x0c 0x01 0x393 0x0c 0x00 0x27 0x58>;
			clock-names = "clkp1\0clkp2\0can_clk";
			assigned-clocks = <0x0c 0x00 0x27>;
			assigned-clock-rates = <0x2625a00>;
			power-domains = <0x09 0x20>;
			resets = <0x0c 0x393>;
			status = "okay";
			pinctrl-0 = <0x5a>;
			pinctrl-names = "default";
			phandle = <0x127>;
		};

		can@e66c0000 {
			compatible = "renesas,r8a7795-canfd\0renesas,rcar-gen3-canfd";
			reg = <0x00 0xe66c0000 0x00 0x8000>;
			interrupts = <0x00 0x1d 0x04 0x00 0x1e 0x04>;
			clocks = <0x0c 0x01 0x392 0x0c 0x00 0x27 0x58>;
			clock-names = "fck\0canfd\0can_clk";
			assigned-clocks = <0x0c 0x00 0x27>;
			assigned-clock-rates = <0x2625a00>;
			power-domains = <0x09 0x20>;
			resets = <0x0c 0x392>;
			status = "disabled";
			pinctrl-0 = <0x5b 0x5c>;
			pinctrl-names = "default";
			phandle = <0x128>;

			channel0 {
				status = "okay";
			};

			channel1 {
				status = "okay";
			};
		};

		pwm@e6e30000 {
			compatible = "renesas,pwm-r8a7795\0renesas,pwm-rcar";
			reg = <0x00 0xe6e30000 0x00 0x08>;
			clocks = <0x0c 0x01 0x20b>;
			power-domains = <0x09 0x20>;
			resets = <0x0c 0x20b>;
			#pwm-cells = <0x02>;
			status = "disabled";
			phandle = <0x129>;
		};

		pwm@e6e31000 {
			compatible = "renesas,pwm-r8a7795\0renesas,pwm-rcar";
			reg = <0x00 0xe6e31000 0x00 0x08>;
			clocks = <0x0c 0x01 0x20b>;
			power-domains = <0x09 0x20>;
			resets = <0x0c 0x20b>;
			#pwm-cells = <0x02>;
			status = "disabled";
			phandle = <0x12a>;
		};

		pwm@e6e32000 {
			compatible = "renesas,pwm-r8a7795\0renesas,pwm-rcar";
			reg = <0x00 0xe6e32000 0x00 0x08>;
			clocks = <0x0c 0x01 0x20b>;
			power-domains = <0x09 0x20>;
			resets = <0x0c 0x20b>;
			#pwm-cells = <0x02>;
			status = "disabled";
			phandle = <0x12b>;
		};

		pwm@e6e33000 {
			compatible = "renesas,pwm-r8a7795\0renesas,pwm-rcar";
			reg = <0x00 0xe6e33000 0x00 0x08>;
			clocks = <0x0c 0x01 0x20b>;
			power-domains = <0x09 0x20>;
			resets = <0x0c 0x20b>;
			#pwm-cells = <0x02>;
			status = "disabled";
			phandle = <0x12c>;
		};

		pwm@e6e34000 {
			compatible = "renesas,pwm-r8a7795\0renesas,pwm-rcar";
			reg = <0x00 0xe6e34000 0x00 0x08>;
			clocks = <0x0c 0x01 0x20b>;
			power-domains = <0x09 0x20>;
			resets = <0x0c 0x20b>;
			#pwm-cells = <0x02>;
			status = "disabled";
			phandle = <0x12d>;
		};

		pwm@e6e35000 {
			compatible = "renesas,pwm-r8a7795\0renesas,pwm-rcar";
			reg = <0x00 0xe6e35000 0x00 0x08>;
			clocks = <0x0c 0x01 0x20b>;
			power-domains = <0x09 0x20>;
			resets = <0x0c 0x20b>;
			#pwm-cells = <0x02>;
			status = "disabled";
			phandle = <0x12e>;
		};

		pwm@e6e36000 {
			compatible = "renesas,pwm-r8a7795\0renesas,pwm-rcar";
			reg = <0x00 0xe6e36000 0x00 0x08>;
			clocks = <0x0c 0x01 0x20b>;
			power-domains = <0x09 0x20>;
			resets = <0x0c 0x20b>;
			#pwm-cells = <0x02>;
			status = "disabled";
			phandle = <0x12f>;
		};

		serial@e6e60000 {
			compatible = "renesas,scif-r8a7795\0renesas,rcar-gen3-scif\0renesas,scif";
			reg = <0x00 0xe6e60000 0x00 0x40>;
			interrupts = <0x00 0x98 0x04>;
			clocks = <0x0c 0x01 0xcf 0x0c 0x00 0x10 0x48>;
			clock-names = "fck\0brg_int\0scif_clk";
			dmas = <0x1e 0x51 0x1e 0x50 0x1f 0x51 0x1f 0x50>;
			dma-names = "tx\0rx\0tx\0rx";
			power-domains = <0x09 0x20>;
			resets = <0x0c 0xcf>;
			status = "disabled";
			phandle = <0x130>;
		};

		serial@e6e68000 {
			compatible = "renesas,scif-r8a7795\0renesas,rcar-gen3-scif\0renesas,scif";
			reg = <0x00 0xe6e68000 0x00 0x40>;
			interrupts = <0x00 0x99 0x04>;
			clocks = <0x0c 0x01 0xce 0x0c 0x00 0x10 0x48>;
			clock-names = "fck\0brg_int\0scif_clk";
			dmas = <0x1e 0x53 0x1e 0x52 0x1f 0x53 0x1f 0x52>;
			dma-names = "tx\0rx\0tx\0rx";
			power-domains = <0x09 0x20>;
			resets = <0x0c 0xce>;
			status = "okay";
			pinctrl-0 = <0x5d>;
			pinctrl-names = "default";
			phandle = <0x131>;
		};

		serial@e6e88000 {
			compatible = "renesas,scif-r8a7795\0renesas,rcar-gen3-scif\0renesas,scif";
			reg = <0x00 0xe6e88000 0x00 0x40>;
			interrupts = <0x00 0xa4 0x04>;
			clocks = <0x0c 0x01 0x136 0x0c 0x00 0x10 0x48>;
			clock-names = "fck\0brg_int\0scif_clk";
			power-domains = <0x09 0x20>;
			resets = <0x0c 0x136>;
			status = "disabled";
			pinctrl-0 = <0x5e>;
			pinctrl-names = "default";
			phandle = <0x132>;
		};

		serial@e6c50000 {
			compatible = "renesas,scif-r8a7795\0renesas,rcar-gen3-scif\0renesas,scif";
			reg = <0x00 0xe6c50000 0x00 0x40>;
			interrupts = <0x00 0x17 0x04>;
			clocks = <0x0c 0x01 0xcc 0x0c 0x00 0x10 0x48>;
			clock-names = "fck\0brg_int\0scif_clk";
			dmas = <0x2f 0x57 0x2f 0x56>;
			dma-names = "tx\0rx";
			power-domains = <0x09 0x20>;
			resets = <0x0c 0xcc>;
			status = "disabled";
			phandle = <0x133>;
		};

		serial@e6c40000 {
			compatible = "renesas,scif-r8a7795\0renesas,rcar-gen3-scif\0renesas,scif";
			reg = <0x00 0xe6c40000 0x00 0x40>;
			interrupts = <0x00 0x10 0x04>;
			clocks = <0x0c 0x01 0xcb 0x0c 0x00 0x10 0x48>;
			clock-names = "fck\0brg_int\0scif_clk";
			dmas = <0x2f 0x59 0x2f 0x58>;
			dma-names = "tx\0rx";
			power-domains = <0x09 0x20>;
			resets = <0x0c 0xcb>;
			status = "disabled";
			phandle = <0x134>;
		};

		serial@e6f30000 {
			compatible = "renesas,scif-r8a7795\0renesas,rcar-gen3-scif\0renesas,scif";
			reg = <0x00 0xe6f30000 0x00 0x40>;
			interrupts = <0x00 0x11 0x04>;
			clocks = <0x0c 0x01 0xca 0x0c 0x00 0x10 0x48>;
			clock-names = "fck\0brg_int\0scif_clk";
			dmas = <0x1e 0x5b 0x1e 0x5a 0x1f 0x5b 0x1f 0x5a>;
			dma-names = "tx\0rx\0tx\0rx";
			power-domains = <0x09 0x20>;
			resets = <0x0c 0xca>;
			status = "disabled";
			phandle = <0x135>;
		};

		pwm@e6e80000 {
			compatible = "renesas,tpu-r8a7795\0renesas,tpu";
			reg = <0x00 0xe6e80000 0x00 0x148>;
			interrupts = <0x00 0x87 0x04>;
			clocks = <0x0c 0x01 0x130>;
			power-domains = <0x09 0x20>;
			resets = <0x0c 0x130>;
			#pwm-cells = <0x03>;
			status = "disabled";
			phandle = <0x136>;
		};

		mlp@ec520000 {
			compatible = "rcar,medialb-dim2";
			reg = <0x00 0xec520000 0x00 0x800>;
			interrupts = <0x00 0x180 0x04 0x00 0x181 0x04 0x00 0x182 0x04 0x00 0x183 0x04 0x00 0x184 0x04>;
			clocks = <0x0c 0x01 0x322>;
			power-domains = <0x09 0x20>;
			status = "disabled";
			phandle = <0x137>;
		};

		spi@e6e90000 {
			compatible = "renesas,msiof-r8a7795\0renesas,rcar-gen3-msiof";
			reg = <0x00 0xe6e90000 0x00 0x64>;
			interrupts = <0x00 0x9c 0x04>;
			clocks = <0x0c 0x01 0xd3 0x0c 0x00 0x26>;
			clock-names = "msiof_clk\0mso";
			assigned-clocks = <0x0c 0x00 0x26>;
			assigned-clock-rates = <0x1312d00>;
			dmas = <0x1e 0x41 0x1e 0x40 0x1f 0x41 0x1f 0x40>;
			dma-names = "tx\0rx\0tx\0rx";
			power-domains = <0x09 0x20>;
			resets = <0x0c 0xd3>;
			#address-cells = <0x01>;
			#size-cells = <0x00>;
			status = "disabled";
			phandle = <0x138>;
		};

		spi@e6ea0000 {
			compatible = "renesas,msiof-r8a7795\0renesas,rcar-gen3-msiof";
			reg = <0x00 0xe6ea0000 0x00 0x64>;
			interrupts = <0x00 0x9d 0x04>;
			clocks = <0x0c 0x01 0xd2 0x0c 0x00 0x26>;
			clock-names = "msiof_clk\0mso";
			assigned-clocks = <0x0c 0x00 0x26>;
			assigned-clock-rates = <0x1312d00>;
			dmas = <0x1e 0x43 0x1e 0x42 0x1f 0x43 0x1f 0x42>;
			dma-names = "tx\0rx\0tx\0rx";
			power-domains = <0x09 0x20>;
			resets = <0x0c 0xd2>;
			#address-cells = <0x01>;
			#size-cells = <0x00>;
			status = "disabled";
			phandle = <0x139>;
		};

		spi@e6c00000 {
			compatible = "renesas,msiof-r8a7795\0renesas,rcar-gen3-msiof";
			reg = <0x00 0xe6c00000 0x00 0x64>;
			interrupts = <0x00 0x9e 0x04>;
			clocks = <0x0c 0x01 0xd1 0x0c 0x00 0x26>;
			clock-names = "msiof_clk\0mso";
			assigned-clocks = <0x0c 0x00 0x26>;
			assigned-clock-rates = <0x1312d00>;
			dmas = <0x2f 0x45 0x2f 0x44>;
			dma-names = "tx\0rx";
			power-domains = <0x09 0x20>;
			resets = <0x0c 0xd1>;
			#address-cells = <0x01>;
			#size-cells = <0x00>;
			status = "disabled";
			phandle = <0x13a>;
		};

		spi@e6c10000 {
			compatible = "renesas,msiof-r8a7795\0renesas,rcar-gen3-msiof";
			reg = <0x00 0xe6c10000 0x00 0x64>;
			interrupts = <0x00 0x9f 0x04>;
			clocks = <0x0c 0x01 0xd0 0x0c 0x00 0x26>;
			clock-names = "msiof_clk\0mso";
			assigned-clocks = <0x0c 0x00 0x26>;
			assigned-clock-rates = <0x1312d00>;
			dmas = <0x2f 0x47 0x2f 0x46>;
			dma-names = "tx\0rx";
			power-domains = <0x09 0x20>;
			resets = <0x0c 0xd0>;
			#address-cells = <0x01>;
			#size-cells = <0x00>;
			status = "disabled";
			phandle = <0x13b>;
		};

		rpc0@ee200000 {
			compatible = "renesas,r8a77951-rpc-if\0renesas,rcar-gen3-rpc-if";
			reg = <0x00 0xee200000 0x00 0x1f0 0x00 0x8000000 0x00 0x4000000 0x00 0xee208000 0x00 0x100>;
			interrupts = <0x00 0x26 0x04>;
			clocks = <0x0c 0x01 0x395>;
			power-domains = <0x09 0x20>;
			#address-cells = <0x01>;
			#size-cells = <0x00>;
			status = "okay";
			phandle = <0x13c>;

			flash@0 {
				compatible = "cfi-flash";
				reg = <0x00>;

				partitions {
					compatible = "fixed-partitions";
					#address-cells = <0x01>;
					#size-cells = <0x01>;

					bootparam@0 {
						reg = <0x00 0x40000>;
						read-only;
					};

					bl2@00040000 {
						reg = <0x40000 0x140000>;
						read-only;
					};

					cert_header_sa6@00180000 {
						reg = <0x180000 0x40000>;
						read-only;
					};

					bl31@001C0000 {
						reg = <0x1c0000 0x40000>;
						read-only;
					};

					tee@00200000 {
						reg = <0x200000 0x440000>;
						read-only;
					};

					uboot@00640000 {
						reg = <0x640000 0xc0000>;
						read-only;
					};

					uboot-env@00700000 {
						reg = <0x700000 0x40000>;
						read-only;
					};

					dtb@00740000 {
						reg = <0x740000 0x80000>;
					};

					kernel@007C0000 {
						reg = <0x7c0000 0x1400000>;
					};

					user@01BC0000 {
						reg = <0x1bc0000 0x2440000>;
					};
				};
			};
		};

		video@e6ef0000 {
			compatible = "renesas,vin-r8a7795";
			reg = <0x00 0xe6ef0000 0x00 0x1000>;
			interrupts = <0x00 0xbc 0x04>;
			clocks = <0x0c 0x01 0x32b>;
			power-domains = <0x09 0x20>;
			resets = <0x0c 0x32b>;
			renesas,id = <0x00>;
			status = "okay";
			phandle = <0x13d>;

			ports {
				#address-cells = <0x01>;
				#size-cells = <0x00>;

				port@1 {
					#address-cells = <0x01>;
					#size-cells = <0x00>;
					reg = <0x01>;

					endpoint@0 {
						reg = <0x00>;
						remote-endpoint = <0x5f>;
						phandle = <0xb6>;
					};

					endpoint@2 {
						reg = <0x02>;
						remote-endpoint = <0x60>;
						phandle = <0xbf>;
					};
				};
			};
		};

		video@e6ef1000 {
			compatible = "renesas,vin-r8a7795";
			reg = <0x00 0xe6ef1000 0x00 0x1000>;
			interrupts = <0x00 0xbd 0x04>;
			clocks = <0x0c 0x01 0x32a>;
			power-domains = <0x09 0x20>;
			resets = <0x0c 0x32a>;
			renesas,id = <0x01>;
			status = "okay";
			phandle = <0x13e>;

			ports {
				#address-cells = <0x01>;
				#size-cells = <0x00>;

				port@1 {
					#address-cells = <0x01>;
					#size-cells = <0x00>;
					reg = <0x01>;

					endpoint@0 {
						reg = <0x00>;
						remote-endpoint = <0x61>;
						phandle = <0xb7>;
					};

					endpoint@2 {
						reg = <0x02>;
						remote-endpoint = <0x62>;
						phandle = <0xc0>;
					};
				};
			};
		};

		video@e6ef2000 {
			compatible = "renesas,vin-r8a7795";
			reg = <0x00 0xe6ef2000 0x00 0x1000>;
			interrupts = <0x00 0xbe 0x04>;
			clocks = <0x0c 0x01 0x329>;
			power-domains = <0x09 0x20>;
			resets = <0x0c 0x329>;
			renesas,id = <0x02>;
			status = "okay";
			phandle = <0x13f>;

			ports {
				#address-cells = <0x01>;
				#size-cells = <0x00>;

				port@1 {
					#address-cells = <0x01>;
					#size-cells = <0x00>;
					reg = <0x01>;

					endpoint@0 {
						reg = <0x00>;
						remote-endpoint = <0x63>;
						phandle = <0xb8>;
					};

					endpoint@2 {
						reg = <0x02>;
						remote-endpoint = <0x64>;
						phandle = <0xc1>;
					};
				};
			};
		};

		video@e6ef3000 {
			compatible = "renesas,vin-r8a7795";
			reg = <0x00 0xe6ef3000 0x00 0x1000>;
			interrupts = <0x00 0xbf 0x04>;
			clocks = <0x0c 0x01 0x328>;
			power-domains = <0x09 0x20>;
			resets = <0x0c 0x328>;
			renesas,id = <0x03>;
			status = "okay";
			phandle = <0x140>;

			ports {
				#address-cells = <0x01>;
				#size-cells = <0x00>;

				port@1 {
					#address-cells = <0x01>;
					#size-cells = <0x00>;
					reg = <0x01>;

					endpoint@0 {
						reg = <0x00>;
						remote-endpoint = <0x65>;
						phandle = <0xb9>;
					};

					endpoint@2 {
						reg = <0x02>;
						remote-endpoint = <0x66>;
						phandle = <0xc2>;
					};
				};
			};
		};

		video@e6ef4000 {
			compatible = "renesas,vin-r8a7795";
			reg = <0x00 0xe6ef4000 0x00 0x1000>;
			interrupts = <0x00 0xae 0x04>;
			clocks = <0x0c 0x01 0x327>;
			power-domains = <0x09 0x20>;
			resets = <0x0c 0x327>;
			renesas,id = <0x04>;
			status = "okay";
			phandle = <0x141>;

			ports {
				#address-cells = <0x01>;
				#size-cells = <0x00>;

				port@1 {
					#address-cells = <0x01>;
					#size-cells = <0x00>;
					reg = <0x01>;

					endpoint@0 {
						reg = <0x00>;
						remote-endpoint = <0x67>;
						phandle = <0xba>;
					};

					endpoint@3 {
						reg = <0x03>;
						remote-endpoint = <0x68>;
						phandle = <0xc3>;
					};
				};
			};
		};

		video@e6ef5000 {
			compatible = "renesas,vin-r8a7795";
			reg = <0x00 0xe6ef5000 0x00 0x1000>;
			interrupts = <0x00 0xaf 0x04>;
			clocks = <0x0c 0x01 0x326>;
			power-domains = <0x09 0x20>;
			resets = <0x0c 0x326>;
			renesas,id = <0x05>;
			status = "okay";
			pinctrl-0 = <0x69>;
			pinctrl-names = "default";
			phandle = <0x142>;

			ports {
				#address-cells = <0x01>;
				#size-cells = <0x00>;

				port@1 {
					#address-cells = <0x01>;
					#size-cells = <0x00>;
					reg = <0x01>;

					endpoint@0 {
						reg = <0x00>;
						remote-endpoint = <0x6a>;
						phandle = <0xbb>;
					};

					endpoint@3 {
						reg = <0x03>;
						remote-endpoint = <0x6b>;
						phandle = <0xc4>;
					};
				};

				port@0 {

					endpoint@0 {
						bus-width = <0x08>;
						vsync-active = <0x01>;
						hsync-active = <0x00>;
						data-enable-active = <0x00>;
						remote-endpoint = <0x6c>;
						phandle = <0x44>;
					};
				};
			};
		};

		video@e6ef6000 {
			compatible = "renesas,vin-r8a7795";
			reg = <0x00 0xe6ef6000 0x00 0x1000>;
			interrupts = <0x00 0xb0 0x04>;
			clocks = <0x0c 0x01 0x325>;
			power-domains = <0x09 0x20>;
			resets = <0x0c 0x325>;
			renesas,id = <0x06>;
			status = "disabled";
			phandle = <0x143>;

			ports {
				#address-cells = <0x01>;
				#size-cells = <0x00>;

				port@1 {
					#address-cells = <0x01>;
					#size-cells = <0x00>;
					reg = <0x01>;

					endpoint@0 {
						reg = <0x00>;
						remote-endpoint = <0x6d>;
						phandle = <0xbc>;
					};

					endpoint@3 {
						reg = <0x03>;
						remote-endpoint = <0x6e>;
						phandle = <0xc5>;
					};
				};
			};
		};

		video@e6ef7000 {
			compatible = "renesas,vin-r8a7795";
			reg = <0x00 0xe6ef7000 0x00 0x1000>;
			interrupts = <0x00 0xab 0x04>;
			clocks = <0x0c 0x01 0x324>;
			power-domains = <0x09 0x20>;
			resets = <0x0c 0x324>;
			renesas,id = <0x07>;
			status = "disabled";
			phandle = <0x144>;

			ports {
				#address-cells = <0x01>;
				#size-cells = <0x00>;

				port@1 {
					#address-cells = <0x01>;
					#size-cells = <0x00>;
					reg = <0x01>;

					endpoint@0 {
						reg = <0x00>;
						remote-endpoint = <0x6f>;
						phandle = <0xbd>;
					};

					endpoint@3 {
						reg = <0x03>;
						remote-endpoint = <0x70>;
						phandle = <0xc6>;
					};
				};
			};
		};

		rif@e6f40000 {
			compatible = "renesas,r8a7795-drif\0renesas,rcar-gen3-drif";
			reg = <0x00 0xe6f40000 0x00 0x64>;
			interrupts = <0x00 0x0c 0x04>;
			clocks = <0x0c 0x01 0x203>;
			clock-names = "fck";
			dmas = <0x1e 0x20 0x1f 0x20>;
			dma-names = "rx\0rx";
			power-domains = <0x09 0x20>;
			resets = <0x0c 0x203>;
			renesas,bonding = <0x71>;
			status = "disabled";
			phandle = <0x72>;
		};

		rif@e6f50000 {
			compatible = "renesas,r8a7795-drif\0renesas,rcar-gen3-drif";
			reg = <0x00 0xe6f50000 0x00 0x64>;
			interrupts = <0x00 0x0d 0x04>;
			clocks = <0x0c 0x01 0x202>;
			clock-names = "fck";
			dmas = <0x1e 0x22 0x1f 0x22>;
			dma-names = "rx\0rx";
			power-domains = <0x09 0x20>;
			resets = <0x0c 0x202>;
			renesas,bonding = <0x72>;
			status = "disabled";
			phandle = <0x71>;
		};

		rif@e6f60000 {
			compatible = "renesas,r8a7795-drif\0renesas,rcar-gen3-drif";
			reg = <0x00 0xe6f60000 0x00 0x64>;
			interrupts = <0x00 0x0e 0x04>;
			clocks = <0x0c 0x01 0x201>;
			clock-names = "fck";
			dmas = <0x1e 0x24 0x1f 0x24>;
			dma-names = "rx\0rx";
			power-domains = <0x09 0x20>;
			resets = <0x0c 0x201>;
			renesas,bonding = <0x73>;
			status = "disabled";
			phandle = <0x74>;
		};

		rif@e6f70000 {
			compatible = "renesas,r8a7795-drif\0renesas,rcar-gen3-drif";
			reg = <0x00 0xe6f70000 0x00 0x64>;
			interrupts = <0x00 0x0f 0x04>;
			clocks = <0x0c 0x01 0x200>;
			clock-names = "fck";
			dmas = <0x1e 0x26 0x1f 0x26>;
			dma-names = "rx\0rx";
			power-domains = <0x09 0x20>;
			resets = <0x0c 0x200>;
			renesas,bonding = <0x74>;
			status = "disabled";
			phandle = <0x73>;
		};

		rif@e6f80000 {
			compatible = "renesas,r8a7795-drif\0renesas,rcar-gen3-drif";
			reg = <0x00 0xe6f80000 0x00 0x64>;
			interrupts = <0x00 0x18 0x04>;
			clocks = <0x0c 0x01 0x1ff>;
			clock-names = "fck";
			dmas = <0x1e 0x28 0x1f 0x28>;
			dma-names = "rx\0rx";
			power-domains = <0x09 0x20>;
			resets = <0x0c 0x1ff>;
			renesas,bonding = <0x75>;
			status = "disabled";
			phandle = <0x76>;
		};

		rif@e6f90000 {
			compatible = "renesas,r8a7795-drif\0renesas,rcar-gen3-drif";
			reg = <0x00 0xe6f90000 0x00 0x64>;
			interrupts = <0x00 0x19 0x04>;
			clocks = <0x0c 0x01 0x1fe>;
			clock-names = "fck";
			dmas = <0x1e 0x2a 0x1f 0x2a>;
			dma-names = "rx\0rx";
			power-domains = <0x09 0x20>;
			resets = <0x0c 0x1fe>;
			renesas,bonding = <0x76>;
			status = "disabled";
			phandle = <0x75>;
		};

		rif@e6fa0000 {
			compatible = "renesas,r8a7795-drif\0renesas,rcar-gen3-drif";
			reg = <0x00 0xe6fa0000 0x00 0x64>;
			interrupts = <0x00 0x1a 0x04>;
			clocks = <0x0c 0x01 0x1fd>;
			clock-names = "fck";
			dmas = <0x1e 0x2c 0x1f 0x2c>;
			dma-names = "rx\0rx";
			power-domains = <0x09 0x20>;
			resets = <0x0c 0x1fd>;
			renesas,bonding = <0x77>;
			status = "disabled";
			phandle = <0x78>;
		};

		rif@e6fb0000 {
			compatible = "renesas,r8a7795-drif\0renesas,rcar-gen3-drif";
			reg = <0x00 0xe6fb0000 0x00 0x64>;
			interrupts = <0x00 0x1b 0x04>;
			clocks = <0x0c 0x01 0x1fc>;
			clock-names = "fck";
			dmas = <0x1e 0x2e 0x1f 0x2e>;
			dma-names = "rx\0rx";
			power-domains = <0x09 0x20>;
			resets = <0x0c 0x1fc>;
			renesas,bonding = <0x78>;
			status = "disabled";
			phandle = <0x77>;
		};

		sound@ec500000 {
			compatible = "renesas,rcar_sound-r8a7795\0renesas,rcar_sound-gen3";
			reg = <0x00 0xec500000 0x00 0x1000 0x00 0xec5a0000 0x00 0x100 0x00 0xec540000 0x00 0x1000 0x00 0xec541000 0x00 0x280 0x00 0xec760000 0x00 0x200 0x00 0xec000000 0x00 0x1000 0x00 0xec008000 0x00 0x1000 0x00 0xec100000 0x00 0x100000>;
			reg-names = "scu\0adg\0ssiu\0ssi\0audmapp";
			clocks = <0x0c 0x01 0x3ed 0x0c 0x01 0x3ee 0x0c 0x01 0x3ef 0x0c 0x01 0x3f0 0x0c 0x01 0x3f1 0x0c 0x01 0x3f2 0x0c 0x01 0x3f3 0x0c 0x01 0x3f4 0x0c 0x01 0x3f5 0x0c 0x01 0x3f6 0x0c 0x01 0x3f7 0x0c 0x01 0x3fe 0x0c 0x01 0x3ff 0x0c 0x01 0x400 0x0c 0x01 0x401 0x0c 0x01 0x402 0x0c 0x01 0x403 0x0c 0x01 0x404 0x0c 0x01 0x405 0x0c 0x01 0x406 0x0c 0x01 0x407 0x0c 0x01 0x3fc 0x0c 0x01 0x3fd 0x0c 0x01 0x3fc 0x0c 0x01 0x3fd 0x0c 0x01 0x3fb 0x0c 0x01 0x3fa 0x79 0x25 0x7a 0x0c 0x00 0x09>;
			clock-names = "ssi-all\0ssi.9\0ssi.8\0ssi.7\0ssi.6\0ssi.5\0ssi.4\0ssi.3\0ssi.2\0ssi.1\0ssi.0\0src.9\0src.8\0src.7\0src.6\0src.5\0src.4\0src.3\0src.2\0src.1\0src.0\0mix.1\0mix.0\0ctu.1\0ctu.0\0dvc.0\0dvc.1\0clk_a\0clk_b\0clk_c\0clk_i";
			power-domains = <0x09 0x20>;
			resets = <0x0c 0x3ed 0x0c 0x3ee 0x0c 0x3ef 0x0c 0x3f0 0x0c 0x3f1 0x0c 0x3f2 0x0c 0x3f3 0x0c 0x3f4 0x0c 0x3f5 0x0c 0x3f6 0x0c 0x3f7>;
			reset-names = "ssi-all\0ssi.9\0ssi.8\0ssi.7\0ssi.6\0ssi.5\0ssi.4\0ssi.3\0ssi.2\0ssi.1\0ssi.0";
			status = "okay";
			pinctrl-0 = <0x7b 0x7c 0x7d>;
			pinctrl-names = "default";
			#sound-dai-cells = <0x01>;
			#clock-cells = <0x01>;
			clock-frequency = <0xbb8000 0xac4400>;
			phandle = <0x21>;

			rcar_sound,dvc {

				dvc-0 {
					dmas = <0x7e 0xbc>;
					dma-names = "tx";
					phandle = <0x83>;
				};

				dvc-1 {
					dmas = <0x7e 0xbe>;
					dma-names = "tx";
					phandle = <0x86>;
				};
			};

			rcar_sound,mix {

				mix-0 {
					phandle = <0x145>;
				};

				mix-1 {
					phandle = <0x146>;
				};
			};

			rcar_sound,ctu {

				ctu-0 {
					phandle = <0x147>;
				};

				ctu-1 {
					phandle = <0x148>;
				};

				ctu-2 {
					phandle = <0x149>;
				};

				ctu-3 {
					phandle = <0x14a>;
				};

				ctu-4 {
					phandle = <0x14b>;
				};

				ctu-5 {
					phandle = <0x14c>;
				};

				ctu-6 {
					phandle = <0x14d>;
				};

				ctu-7 {
					phandle = <0x14e>;
				};
			};

			rcar_sound,src {

				src-0 {
					interrupts = <0x00 0x160 0x04>;
					dmas = <0x7f 0x85 0x7e 0x9a>;
					dma-names = "rx\0tx";
					phandle = <0x82>;
				};

				src-1 {
					interrupts = <0x00 0x161 0x04>;
					dmas = <0x7f 0x87 0x7e 0x9c>;
					dma-names = "rx\0tx";
					phandle = <0x85>;
				};

				src-2 {
					interrupts = <0x00 0x162 0x04>;
					dmas = <0x7f 0x89 0x7e 0x9e>;
					dma-names = "rx\0tx";
					phandle = <0x14f>;
				};

				src-3 {
					interrupts = <0x00 0x163 0x04>;
					dmas = <0x7f 0x8b 0x7e 0xa0>;
					dma-names = "rx\0tx";
					phandle = <0x150>;
				};

				src-4 {
					interrupts = <0x00 0x164 0x04>;
					dmas = <0x7f 0x8d 0x7e 0xb0>;
					dma-names = "rx\0tx";
					phandle = <0x151>;
				};

				src-5 {
					interrupts = <0x00 0x165 0x04>;
					dmas = <0x7f 0x8f 0x7e 0xb2>;
					dma-names = "rx\0tx";
					phandle = <0x152>;
				};

				src-6 {
					interrupts = <0x00 0x166 0x04>;
					dmas = <0x7f 0x91 0x7e 0xb4>;
					dma-names = "rx\0tx";
					phandle = <0x153>;
				};

				src-7 {
					interrupts = <0x00 0x167 0x04>;
					dmas = <0x7f 0x93 0x7e 0xb6>;
					dma-names = "rx\0tx";
					phandle = <0x154>;
				};

				src-8 {
					interrupts = <0x00 0x168 0x04>;
					dmas = <0x7f 0x95 0x7e 0xb8>;
					dma-names = "rx\0tx";
					phandle = <0x155>;
				};

				src-9 {
					interrupts = <0x00 0x169 0x04>;
					dmas = <0x7f 0x97 0x7e 0xba>;
					dma-names = "rx\0tx";
					phandle = <0x156>;
				};
			};

			rcar_sound,ssiu {

				ssiu-0 {
					dmas = <0x7f 0x15 0x7e 0x16>;
					dma-names = "rx\0tx";
					phandle = <0x157>;
				};

				ssiu-1 {
					dmas = <0x7f 0x35 0x7e 0x36>;
					dma-names = "rx\0tx";
					phandle = <0x158>;
				};

				ssiu-2 {
					dmas = <0x7f 0x37 0x7e 0x38>;
					dma-names = "rx\0tx";
					phandle = <0x159>;
				};

				ssiu-3 {
					dmas = <0x7f 0x47 0x7e 0x48>;
					dma-names = "rx\0tx";
					phandle = <0x15a>;
				};

				ssiu-4 {
					dmas = <0x7f 0x3f 0x7e 0x40>;
					dma-names = "rx\0tx";
					phandle = <0x15b>;
				};

				ssiu-5 {
					dmas = <0x7f 0x43 0x7e 0x44>;
					dma-names = "rx\0tx";
					phandle = <0x15c>;
				};

				ssiu-6 {
					dmas = <0x7f 0x4f 0x7e 0x50>;
					dma-names = "rx\0tx";
					phandle = <0x15d>;
				};

				ssiu-7 {
					dmas = <0x7f 0x53 0x7e 0x54>;
					dma-names = "rx\0tx";
					phandle = <0x15e>;
				};

				ssiu-8 {
					dmas = <0x7f 0x49 0x7e 0x4a>;
					dma-names = "rx\0tx";
					phandle = <0x15f>;
				};

				ssiu-9 {
					dmas = <0x7f 0x4b 0x7e 0x4c>;
					dma-names = "rx\0tx";
					phandle = <0x160>;
				};

				ssiu-10 {
					dmas = <0x7f 0x57 0x7e 0x58>;
					dma-names = "rx\0tx";
					phandle = <0x161>;
				};

				ssiu-11 {
					dmas = <0x7f 0x59 0x7e 0x5a>;
					dma-names = "rx\0tx";
					phandle = <0x162>;
				};

				ssiu-12 {
					dmas = <0x7f 0x5f 0x7e 0x60>;
					dma-names = "rx\0tx";
					phandle = <0x163>;
				};

				ssiu-13 {
					dmas = <0x7f 0xc3 0x7e 0xc4>;
					dma-names = "rx\0tx";
					phandle = <0x164>;
				};

				ssiu-14 {
					dmas = <0x7f 0xc7 0x7e 0xc8>;
					dma-names = "rx\0tx";
					phandle = <0x165>;
				};

				ssiu-15 {
					dmas = <0x7f 0xcb 0x7e 0xcc>;
					dma-names = "rx\0tx";
					phandle = <0x166>;
				};

				ssiu-16 {
					dmas = <0x7f 0x63 0x7e 0x64>;
					dma-names = "rx\0tx";
					phandle = <0x167>;
				};

				ssiu-17 {
					dmas = <0x7f 0x67 0x7e 0x68>;
					dma-names = "rx\0tx";
					phandle = <0x168>;
				};

				ssiu-18 {
					dmas = <0x7f 0x6b 0x7e 0x6c>;
					dma-names = "rx\0tx";
					phandle = <0x169>;
				};

				ssiu-19 {
					dmas = <0x7f 0x6d 0x7e 0x6e>;
					dma-names = "rx\0tx";
					phandle = <0x16a>;
				};

				ssiu-20 {
					dmas = <0x7f 0xcf 0x7e 0xce>;
					dma-names = "rx\0tx";
					phandle = <0x16b>;
				};

				ssiu-21 {
					dmas = <0x7f 0xeb 0x7e 0xec>;
					dma-names = "rx\0tx";
					phandle = <0x16c>;
				};

				ssiu-22 {
					dmas = <0x7f 0xed 0x7e 0xee>;
					dma-names = "rx\0tx";
					phandle = <0x16d>;
				};

				ssiu-23 {
					dmas = <0x7f 0xef 0x7e 0xf0>;
					dma-names = "rx\0tx";
					phandle = <0x16e>;
				};

				ssiu-24 {
					dmas = <0x7f 0x6f 0x7e 0x70>;
					dma-names = "rx\0tx";
					phandle = <0x16f>;
				};

				ssiu-25 {
					dmas = <0x7f 0x21 0x7e 0x22>;
					dma-names = "rx\0tx";
					phandle = <0x170>;
				};

				ssiu-26 {
					dmas = <0x7f 0x23 0x7e 0x24>;
					dma-names = "rx\0tx";
					phandle = <0x171>;
				};

				ssiu-27 {
					dmas = <0x7f 0x25 0x7e 0x26>;
					dma-names = "rx\0tx";
					phandle = <0x172>;
				};

				ssiu-28 {
					dmas = <0x7f 0x27 0x7e 0x28>;
					dma-names = "rx\0tx";
					phandle = <0x173>;
				};

				ssiu-29 {
					dmas = <0x7f 0x29 0x7e 0x2a>;
					dma-names = "rx\0tx";
					phandle = <0x174>;
				};

				ssiu-30 {
					dmas = <0x7f 0x2b 0x7e 0x2c>;
					dma-names = "rx\0tx";
					phandle = <0x175>;
				};

				ssiu-31 {
					dmas = <0x7f 0x2d 0x7e 0x2e>;
					dma-names = "rx\0tx";
					phandle = <0x176>;
				};

				ssiu-32 {
					dmas = <0x7f 0x71 0x7e 0x72>;
					dma-names = "rx\0tx";
					phandle = <0x177>;
				};

				ssiu-33 {
					dmas = <0x7f 0x17 0x7e 0x18>;
					dma-names = "rx\0tx";
					phandle = <0x178>;
				};

				ssiu-34 {
					dmas = <0x7f 0x19 0x7e 0x1a>;
					dma-names = "rx\0tx";
					phandle = <0x179>;
				};

				ssiu-35 {
					dmas = <0x7f 0x1b 0x7e 0x1c>;
					dma-names = "rx\0tx";
					phandle = <0x17a>;
				};

				ssiu-36 {
					dmas = <0x7f 0x1d 0x7e 0x1e>;
					dma-names = "rx\0tx";
					phandle = <0x17b>;
				};

				ssiu-37 {
					dmas = <0x7f 0x1f 0x7e 0x20>;
					dma-names = "rx\0tx";
					phandle = <0x17c>;
				};

				ssiu-38 {
					dmas = <0x7f 0x31 0x7e 0x32>;
					dma-names = "rx\0tx";
					phandle = <0x17d>;
				};

				ssiu-39 {
					dmas = <0x7f 0x33 0x7e 0x34>;
					dma-names = "rx\0tx";
					phandle = <0x17e>;
				};

				ssiu-40 {
					dmas = <0x7f 0x73 0x7e 0x74>;
					dma-names = "rx\0tx";
					phandle = <0x17f>;
				};

				ssiu-41 {
					dmas = <0x7f 0x75 0x7e 0x76>;
					dma-names = "rx\0tx";
					phandle = <0x180>;
				};

				ssiu-42 {
					dmas = <0x7f 0x79 0x7e 0x7a>;
					dma-names = "rx\0tx";
					phandle = <0x181>;
				};

				ssiu-43 {
					dmas = <0x7f 0x7b 0x7e 0x7c>;
					dma-names = "rx\0tx";
					phandle = <0x182>;
				};

				ssiu-44 {
					dmas = <0x7f 0x7d 0x7e 0x7e>;
					dma-names = "rx\0tx";
					phandle = <0x183>;
				};

				ssiu-45 {
					dmas = <0x7f 0x7f 0x7e 0x80>;
					dma-names = "rx\0tx";
					phandle = <0x184>;
				};

				ssiu-46 {
					dmas = <0x7f 0x81 0x7e 0x82>;
					dma-names = "rx\0tx";
					phandle = <0x185>;
				};

				ssiu-47 {
					dmas = <0x7f 0x83 0x7e 0x84>;
					dma-names = "rx\0tx";
					phandle = <0x186>;
				};

				ssiu-48 {
					dmas = <0x7f 0xa3 0x7e 0xa4>;
					dma-names = "rx\0tx";
					phandle = <0x187>;
				};

				ssiu-49 {
					dmas = <0x7f 0xa5 0x7e 0xa6>;
					dma-names = "rx\0tx";
					phandle = <0x188>;
				};

				ssiu-50 {
					dmas = <0x7f 0xa7 0x7e 0xa8>;
					dma-names = "rx\0tx";
					phandle = <0x189>;
				};

				ssiu-51 {
					dmas = <0x7f 0xa9 0x7e 0xaa>;
					dma-names = "rx\0tx";
					phandle = <0x18a>;
				};
			};

			rcar_sound,ssi {

				ssi-0 {
					interrupts = <0x00 0x172 0x04>;
					dmas = <0x7f 0x01 0x7e 0x02>;
					dma-names = "rx\0tx";
					phandle = <0x81>;
				};

				ssi-1 {
					interrupts = <0x00 0x173 0x04>;
					dmas = <0x7f 0x03 0x7e 0x04>;
					dma-names = "rx\0tx";
					shared-pin;
					phandle = <0x84>;
				};

				ssi-2 {
					interrupts = <0x00 0x174 0x04>;
					dmas = <0x7f 0x05 0x7e 0x06>;
					dma-names = "rx\0tx";
					phandle = <0x89>;
				};

				ssi-3 {
					interrupts = <0x00 0x175 0x04>;
					dmas = <0x7f 0x07 0x7e 0x08>;
					dma-names = "rx\0tx";
					phandle = <0x8b>;
				};

				ssi-4 {
					interrupts = <0x00 0x176 0x04>;
					dmas = <0x7f 0x09 0x7e 0x0a>;
					dma-names = "rx\0tx";
					shared-pin;
					phandle = <0x8c>;
				};

				ssi-5 {
					interrupts = <0x00 0x177 0x04>;
					dmas = <0x7f 0x0b 0x7e 0x0c>;
					dma-names = "rx\0tx";
					phandle = <0x18b>;
				};

				ssi-6 {
					interrupts = <0x00 0x178 0x04>;
					dmas = <0x7f 0x0d 0x7e 0x0e>;
					dma-names = "rx\0tx";
					phandle = <0x8e>;
				};

				ssi-7 {
					interrupts = <0x00 0x179 0x04>;
					dmas = <0x7f 0x0f 0x7e 0x10>;
					dma-names = "rx\0tx";
					phandle = <0x90>;
				};

				ssi-8 {
					interrupts = <0x00 0x17a 0x04>;
					dmas = <0x7f 0x11 0x7e 0x12>;
					dma-names = "rx\0tx";
					shared-pin;
					phandle = <0x91>;
				};

				ssi-9 {
					interrupts = <0x00 0x17b 0x04>;
					dmas = <0x7f 0x13 0x7e 0x14>;
					dma-names = "rx\0tx";
					phandle = <0x18c>;
				};
			};

			ports {
				#address-cells = <0x01>;
				#size-cells = <0x00>;

				port@0 {
					reg = <0x00>;
					phandle = <0xe0>;

					endpoint {
						remote-endpoint = <0x80>;
						dai-format = "left_j";
						bitclock-master = <0x22>;
						frame-master = <0x22>;
						playback = <0x81 0x82 0x83>;
						capture = <0x84 0x85 0x86>;
						phandle = <0x22>;
					};
				};

				port@1 {
					reg = <0x01>;
					phandle = <0xe1>;

					endpoint {
						remote-endpoint = <0x87>;
						dai-format = "i2s";
						bitclock-master = <0x88>;
						frame-master = <0x88>;
						playback = <0x89>;
						phandle = <0x88>;
					};
				};

				port@2 {
					reg = <0x02>;
					phandle = <0xe2>;

					endpoint {
						remote-endpoint = <0x8a>;
						dai-format = "i2s";
						bitclock-master = <0x2d>;
						frame-master = <0x2d>;
						dai-tdm-slot-num = <0x08>;
						dai-tdm-slot-width = <0x20>;
						playback = <0x8b>;
						capture = <0x8c>;
						phandle = <0x2d>;
					};
				};

				port@3 {
					reg = <0x03>;
					phandle = <0xe3>;

					endpoint {
						remote-endpoint = <0x8d>;
						dai-format = "i2s";
						bitclock-master = <0x8d>;
						frame-master = <0x8d>;
						capture = <0x8e>;
						phandle = <0xe7>;
					};
				};

				port@4 {
					reg = <0x04>;
					phandle = <0xe4>;

					endpoint {
						remote-endpoint = <0x8f>;
						simple-audio-card,format = "i2s";
						bitclock-master = <0x8f>;
						frame-master = <0x8f>;
						playback = <0x90>;
						capture = <0x91>;
						phandle = <0xe8>;
					};
				};
			};
		};

		dma-controller@ec700000 {
			compatible = "renesas,dmac-r8a7795\0renesas,rcar-dmac";
			reg = <0x00 0xec700000 0x00 0x10000>;
			interrupts = <0x00 0x15e 0x04 0x00 0x140 0x04 0x00 0x141 0x04 0x00 0x142 0x04 0x00 0x143 0x04 0x00 0x144 0x04 0x00 0x145 0x04 0x00 0x146 0x04 0x00 0x147 0x04 0x00 0x148 0x04 0x00 0x149 0x04 0x00 0x14a 0x04 0x00 0x14b 0x04 0x00 0x14c 0x04 0x00 0x14d 0x04 0x00 0x14e 0x04 0x00 0x14f 0x04>;
			interrupt-names = "error\0ch0\0ch1\0ch2\0ch3\0ch4\0ch5\0ch6\0ch7\0ch8\0ch9\0ch10\0ch11\0ch12\0ch13\0ch14\0ch15";
			clocks = <0x0c 0x01 0x1f6>;
			clock-names = "fck";
			power-domains = <0x09 0x20>;
			resets = <0x0c 0x1f6>;
			#dma-cells = <0x01>;
			dma-channels = <0x10>;
			phandle = <0x7f>;
		};

		dma-controller@ec720000 {
			compatible = "renesas,dmac-r8a7795\0renesas,rcar-dmac";
			reg = <0x00 0xec720000 0x00 0x10000>;
			interrupts = <0x00 0x15f 0x04 0x00 0x150 0x04 0x00 0x151 0x04 0x00 0x152 0x04 0x00 0x153 0x04 0x00 0x154 0x04 0x00 0x155 0x04 0x00 0x156 0x04 0x00 0x157 0x04 0x00 0x158 0x04 0x00 0x159 0x04 0x00 0x15a 0x04 0x00 0x15b 0x04 0x00 0x15c 0x04 0x00 0x15d 0x04 0x00 0x17e 0x04 0x00 0x17f 0x04>;
			interrupt-names = "error\0ch0\0ch1\0ch2\0ch3\0ch4\0ch5\0ch6\0ch7\0ch8\0ch9\0ch10\0ch11\0ch12\0ch13\0ch14\0ch15";
			clocks = <0x0c 0x01 0x1f5>;
			clock-names = "fck";
			power-domains = <0x09 0x20>;
			resets = <0x0c 0x1f5>;
			#dma-cells = <0x01>;
			dma-channels = <0x10>;
			phandle = <0x7e>;
		};

		usb@ee000000 {
			compatible = "renesas,xhci-r8a7795\0renesas,rcar-gen3-xhci";
			reg = <0x00 0xee000000 0x00 0xc00>;
			interrupts = <0x00 0x66 0x04>;
			clocks = <0x0c 0x01 0x148>;
			power-domains = <0x09 0x20>;
			resets = <0x0c 0x148>;
			status = "okay";
			phandle = <0x18d>;
		};

		usb@ee020000 {
			compatible = "renesas,r8a7795-usb3-peri\0renesas,rcar-gen3-usb3-peri";
			reg = <0x00 0xee020000 0x00 0x400>;
			interrupts = <0x00 0x68 0x04>;
			clocks = <0x0c 0x01 0x148>;
			power-domains = <0x09 0x20>;
			resets = <0x0c 0x148>;
			status = "disabled";
			phandle = <0x18e>;
		};

		usb@ee080000 {
			compatible = "generic-ohci";
			reg = <0x00 0xee080000 0x00 0x100>;
			interrupts = <0x00 0x6c 0x04>;
			clocks = <0x0c 0x01 0x2bf 0x0c 0x01 0x2c0>;
			phys = <0x4e 0x01>;
			phy-names = "usb";
			power-domains = <0x09 0x20>;
			resets = <0x0c 0x2bf 0x0c 0x2c0>;
			status = "okay";
			dr_mode = "otg";
			phandle = <0x94>;
		};

		usb@ee0a0000 {
			compatible = "generic-ohci";
			reg = <0x00 0xee0a0000 0x00 0x100>;
			interrupts = <0x00 0x70 0x04>;
			clocks = <0x0c 0x01 0x2be>;
			phys = <0x92 0x01>;
			phy-names = "usb";
			power-domains = <0x09 0x20>;
			resets = <0x0c 0x2be>;
			status = "okay";
			phandle = <0x95>;
		};

		usb@ee0c0000 {
			compatible = "generic-ohci";
			reg = <0x00 0xee0c0000 0x00 0x100>;
			interrupts = <0x00 0x71 0x04>;
			clocks = <0x0c 0x01 0x2bd>;
			phys = <0x93 0x01>;
			phy-names = "usb";
			power-domains = <0x09 0x20>;
			resets = <0x0c 0x2bd>;
			status = "disabled";
			phandle = <0x96>;
		};

		usb@ee0e0000 {
			compatible = "generic-ohci";
			reg = <0x00 0xee0e0000 0x00 0x100>;
			interrupts = <0x00 0x24 0x04>;
			clocks = <0x0c 0x01 0x2bc 0x0c 0x01 0x2c1>;
			phys = <0x51 0x01>;
			phy-names = "usb";
			power-domains = <0x09 0x20>;
			resets = <0x0c 0x2bc 0x0c 0x2c1>;
			status = "disabled";
			phandle = <0x97>;
		};

		usb@ee080100 {
			compatible = "generic-ehci";
			reg = <0x00 0xee080100 0x00 0x100>;
			interrupts = <0x00 0x6c 0x04>;
			clocks = <0x0c 0x01 0x2bf 0x0c 0x01 0x2c0>;
			phys = <0x4e 0x02>;
			phy-names = "usb";
			companion = <0x94>;
			power-domains = <0x09 0x20>;
			resets = <0x0c 0x2bf 0x0c 0x2c0>;
			status = "okay";
			dr_mode = "otg";
			phandle = <0x18f>;
		};

		usb@ee0a0100 {
			compatible = "generic-ehci";
			reg = <0x00 0xee0a0100 0x00 0x100>;
			interrupts = <0x00 0x70 0x04>;
			clocks = <0x0c 0x01 0x2be>;
			phys = <0x92 0x02>;
			phy-names = "usb";
			companion = <0x95>;
			power-domains = <0x09 0x20>;
			resets = <0x0c 0x2be>;
			status = "okay";
			phandle = <0x190>;
		};

		usb@ee0c0100 {
			compatible = "generic-ehci";
			reg = <0x00 0xee0c0100 0x00 0x100>;
			interrupts = <0x00 0x71 0x04>;
			clocks = <0x0c 0x01 0x2bd>;
			phys = <0x93 0x02>;
			phy-names = "usb";
			companion = <0x96>;
			power-domains = <0x09 0x20>;
			resets = <0x0c 0x2bd>;
			status = "disabled";
			phandle = <0x191>;
		};

		usb@ee0e0100 {
			compatible = "generic-ehci";
			reg = <0x00 0xee0e0100 0x00 0x100>;
			interrupts = <0x00 0x24 0x04>;
			clocks = <0x0c 0x01 0x2bc 0x0c 0x01 0x2c1>;
			phys = <0x51 0x02>;
			phy-names = "usb";
			companion = <0x97>;
			power-domains = <0x09 0x20>;
			resets = <0x0c 0x2bc 0x0c 0x2c1>;
			status = "disabled";
			phandle = <0x192>;
		};

		usb-phy@ee080200 {
			compatible = "renesas,usb2-phy-r8a7795\0renesas,rcar-gen3-usb2-phy";
			reg = <0x00 0xee080200 0x00 0x700>;
			interrupts = <0x00 0x6c 0x04>;
			clocks = <0x0c 0x01 0x2bf 0x0c 0x01 0x2c0>;
			power-domains = <0x09 0x20>;
			resets = <0x0c 0x2bf 0x0c 0x2c0>;
			#phy-cells = <0x01>;
			status = "okay";
			pinctrl-0 = <0x98>;
			pinctrl-names = "default";
			phandle = <0x4e>;
		};

		usb-phy@ee0a0200 {
			compatible = "renesas,usb2-phy-r8a7795\0renesas,rcar-gen3-usb2-phy";
			reg = <0x00 0xee0a0200 0x00 0x700>;
			clocks = <0x0c 0x01 0x2be>;
			power-domains = <0x09 0x20>;
			resets = <0x0c 0x2be>;
			#phy-cells = <0x01>;
			status = "okay";
			pinctrl-0 = <0x99>;
			pinctrl-names = "default";
			phandle = <0x92>;
		};

		usb-phy@ee0c0200 {
			compatible = "renesas,usb2-phy-r8a7795\0renesas,rcar-gen3-usb2-phy";
			reg = <0x00 0xee0c0200 0x00 0x700>;
			clocks = <0x0c 0x01 0x2bd>;
			power-domains = <0x09 0x20>;
			resets = <0x0c 0x2bd>;
			#phy-cells = <0x01>;
			status = "disabled";
			phandle = <0x93>;
		};

		usb-phy@ee0e0200 {
			compatible = "renesas,usb2-phy-r8a7795\0renesas,rcar-gen3-usb2-phy";
			reg = <0x00 0xee0e0200 0x00 0x700>;
			interrupts = <0x00 0x24 0x04>;
			clocks = <0x0c 0x01 0x2bc 0x0c 0x01 0x2c1>;
			power-domains = <0x09 0x20>;
			resets = <0x0c 0x2bc 0x0c 0x2c1>;
			#phy-cells = <0x01>;
			status = "disabled";
			phandle = <0x51>;
		};

		mmc@ee100000 {
			compatible = "renesas,sdhi-r8a7795\0renesas,rcar-gen3-sdhi";
			reg = <0x00 0xee100000 0x00 0x2000>;
			interrupts = <0x00 0xa5 0x04>;
			clocks = <0x0c 0x01 0x13a>;
			max-frequency = <0xbebc200>;
			power-domains = <0x09 0x20>;
			resets = <0x0c 0x13a>;
			status = "okay";
			pinctrl-0 = <0x9a>;
			pinctrl-1 = <0x9b>;
			pinctrl-names = "default\0state_uhs";
			vmmc-supply = <0x9c>;
			vqmmc-supply = <0x9d>;
			cd-gpios = <0x31 0x0c 0x01>;
			bus-width = <0x04>;
			sd-uhs-sdr50;
			sd-uhs-sdr104;
			phandle = <0x193>;
		};

		mmc@ee120000 {
			compatible = "renesas,sdhi-r8a7795\0renesas,rcar-gen3-sdhi";
			reg = <0x00 0xee120000 0x00 0x2000>;
			interrupts = <0x00 0xa6 0x04>;
			clocks = <0x0c 0x01 0x139>;
			max-frequency = <0xbebc200>;
			power-domains = <0x09 0x20>;
			resets = <0x0c 0x139>;
			status = "disabled";
			phandle = <0x194>;
		};

		mmc@ee140000 {
			compatible = "renesas,sdhi-r8a7795\0renesas,rcar-gen3-sdhi";
			reg = <0x00 0xee140000 0x00 0x2000>;
			interrupts = <0x00 0xa7 0x04>;
			clocks = <0x0c 0x01 0x138>;
			max-frequency = <0xbebc200>;
			power-domains = <0x09 0x20>;
			resets = <0x0c 0x138>;
			status = "okay";
			pinctrl-0 = <0x9e>;
			pinctrl-1 = <0x9e>;
			pinctrl-names = "default\0state_uhs";
			iommus = <0x9f 0x22>;
			vmmc-supply = <0xa0>;
			vqmmc-supply = <0xa1>;
			bus-width = <0x08>;
			mmc-hs200-1_8v;
			mmc-hs400-1_8v;
			no-sd;
			no-sdio;
			non-removable;
			full-pwr-cycle-in-suspend;
			phandle = <0x195>;
		};

		mmc@ee160000 {
			compatible = "renesas,sdhi-r8a7795\0renesas,rcar-gen3-sdhi";
			reg = <0x00 0xee160000 0x00 0x2000>;
			interrupts = <0x00 0xa8 0x04>;
			clocks = <0x0c 0x01 0x137>;
			max-frequency = <0x2faf080>;
			power-domains = <0x09 0x20>;
			resets = <0x0c 0x137>;
			status = "okay";
			pinctrl-0 = <0xa2>;
			pinctrl-names = "default";
			vmmc-supply = <0xa3>;
			vqmmc-supply = <0xa3>;
			bus-width = <0x04>;
			no-1-8-v;
			non-removable;
			cap-power-off-card;
			keep-power-in-suspend;
			#address-cells = <0x01>;
			#size-cells = <0x00>;
			phandle = <0x196>;

			wlcore@2 {
				compatible = "ti,wl1837";
				reg = <0x02>;
				interrupt-parent = <0xa4>;
				interrupts = <0x19 0x02>;
				phandle = <0x197>;
			};
		};

		sata@ee300000 {
			compatible = "renesas,sata-r8a7795\0renesas,rcar-gen3-sata";
			reg = <0x00 0xee300000 0x00 0x200000>;
			interrupts = <0x00 0x69 0x04>;
			clocks = <0x0c 0x01 0x32f>;
			power-domains = <0x09 0x20>;
			resets = <0x0c 0x32f>;
			status = "disabled";
			phandle = <0x198>;
		};

		interrupt-controller@f1010000 {
			compatible = [00];
			#interrupt-cells = <0x03>;
			#address-cells = <0x00>;
			interrupt-controller;
			reg = <0x00 0xf1010000 0x00 0x1000 0x00 0xf1020000 0x00 0x20000 0x00 0xf1040000 0x00 0x20000 0x00 0xf1060000 0x00 0x20000>;
			interrupts = <0x01 0x09 0xff04>;
			power-domains = <0x09 0x20>;
			phandle = <0xad>;
		};

		gsx@fd000000 {
			compatible = "renesas,gsx";
			reg = <0x00 0xfd000000 0x00 0x40000>;
			interrupts = <0x00 0x77 0x04>;
			clocks = <0x0c 0x01 0x70>;
			operating-points-v2 = <0xa5 0xa6 0xa7 0xa8 0xa9 0xaa 0xab 0xac>;
			power-domains = <0x09 0x16>;
			resets = <0x0c 0x70>;
			phandle = <0x1b>;
		};

		pcie@fe000000 {
			compatible = "renesas,pcie-r8a7795\0renesas,pcie-rcar-gen3";
			reg = <0x00 0xfe000000 0x00 0x80000>;
			#address-cells = <0x03>;
			#size-cells = <0x02>;
			bus-range = <0x00 0xff>;
			device_type = "pci";
			ranges = <0x1000000 0x00 0x00 0x00 0xfe100000 0x00 0x100000 0x2000000 0x00 0xfe200000 0x00 0xfe200000 0x00 0x200000 0x2000000 0x00 0x30000000 0x00 0x30000000 0x00 0x8000000 0x42000000 0x00 0x38000000 0x00 0x38000000 0x00 0x8000000>;
			dma-ranges = <0x42000000 0x00 0x40000000 0x00 0x40000000 0x00 0x40000000>;
			interrupts = <0x00 0x74 0x04 0x00 0x75 0x04 0x00 0x76 0x04>;
			#interrupt-cells = <0x01>;
			interrupt-map-mask = <0x00 0x00 0x00 0x00>;
			interrupt-map = <0x00 0x00 0x00 0x00 0xad 0x00 0x74 0x04>;
			clocks = <0x0c 0x01 0x13f 0xae>;
			clock-names = "pcie\0pcie_bus";
			power-domains = <0x09 0x20>;
			resets = <0x0c 0x13f>;
			status = "okay";
			phandle = <0x199>;
		};

		pcie@ee800000 {
			compatible = "renesas,pcie-r8a7795\0renesas,pcie-rcar-gen3";
			reg = <0x00 0xee800000 0x00 0x80000>;
			#address-cells = <0x03>;
			#size-cells = <0x02>;
			bus-range = <0x00 0xff>;
			device_type = "pci";
			ranges = <0x1000000 0x00 0x00 0x00 0xee900000 0x00 0x100000 0x2000000 0x00 0xeea00000 0x00 0xeea00000 0x00 0x200000 0x2000000 0x00 0xc0000000 0x00 0xc0000000 0x00 0x8000000 0x42000000 0x00 0xc8000000 0x00 0xc8000000 0x00 0x8000000>;
			dma-ranges = <0x42000000 0x00 0x40000000 0x00 0x40000000 0x00 0x40000000>;
			interrupts = <0x00 0x94 0x04 0x00 0x95 0x04 0x00 0x96 0x04>;
			#interrupt-cells = <0x01>;
			interrupt-map-mask = <0x00 0x00 0x00 0x00>;
			interrupt-map = <0x00 0x00 0x00 0x00 0xad 0x00 0x94 0x04>;
			clocks = <0x0c 0x01 0x13e 0xae>;
			clock-names = "pcie\0pcie_bus";
			power-domains = <0x09 0x20>;
			resets = <0x0c 0x13e>;
			status = "okay";
			pcie3v3-supply = <0xaf>;
			pcie1v8-supply = <0xb0>;
			phandle = <0x19a>;
		};

		pcie-ep@fe000000 {
			compatible = "renesas,r8a7795-pcie-ep\0renesas,rcar-gen3-pcie-ep";
			reg = <0x00 0xfe000000 0x00 0x80000 0x00 0xfe100000 0x00 0x100000 0x00 0xfe200000 0x00 0x200000 0x00 0x30000000 0x00 0x8000000 0x00 0x38000000 0x00 0x8000000>;
			reg-names = "apb-base\0memory0\0memory1\0memory2\0memory3";
			interrupts = <0x00 0x74 0x04 0x00 0x75 0x04 0x00 0x76 0x04>;
			clocks = <0x0c 0x01 0x13f>;
			clock-names = "pcie";
			resets = <0x0c 0x13f>;
			power-domains = <0x09 0x20>;
			status = "disabled";
			phandle = <0x19b>;
		};

		pcie-ep@ee800000 {
			compatible = "renesas,r8a7795-pcie-ep\0renesas,rcar-gen3-pcie-ep";
			reg = <0x00 0xee800000 0x00 0x80000 0x00 0xee900000 0x00 0x100000 0x00 0xeea00000 0x00 0x200000 0x00 0xc0000000 0x00 0x8000000 0x00 0xc8000000 0x00 0x8000000>;
			reg-names = "apb-base\0memory0\0memory1\0memory2\0memory3";
			interrupts = <0x00 0x94 0x04 0x00 0x95 0x04 0x00 0x96 0x04>;
			clocks = <0x0c 0x01 0x13e>;
			clock-names = "pcie";
			resets = <0x0c 0x13e>;
			power-domains = <0x09 0x20>;
			status = "disabled";
			phandle = <0x19c>;
		};

		imr_alloc {
			dma-coherent;
			phandle = <0xb1>;
		};

		imr-lx4@fe860000 {
			compatible = "renesas,r8a7795-imr-lx4\0renesas,imr-lx4";
			reg = <0x00 0xfe860000 0x00 0x2000>;
			interrupts = <0x00 0xc0 0x04>;
			clocks = <0x0c 0x01 0x337>;
			power-domains = <0x09 0x0e>;
			resets = <0x0c 0x337>;
			alloc-dev = <0xb1>;
		};

		imr-lx4@fe870000 {
			compatible = "renesas,r8a7795-imr-lx4\0renesas,imr-lx4";
			reg = <0x00 0xfe870000 0x00 0x2000>;
			interrupts = <0x00 0xc1 0x04>;
			clocks = <0x0c 0x01 0x336>;
			power-domains = <0x09 0x0e>;
			resets = <0x0c 0x336>;
			alloc-dev = <0xb1>;
		};

		imr-lx4@fe880000 {
			compatible = "renesas,r8a7795-imr-lx4\0renesas,imr-lx4";
			reg = <0x00 0xfe880000 0x00 0x2000>;
			interrupts = <0x00 0xc2 0x04>;
			clocks = <0x0c 0x01 0x335>;
			power-domains = <0x09 0x0e>;
			resets = <0x0c 0x335>;
			alloc-dev = <0xb1>;
		};

		imr-lx4@fe890000 {
			compatible = "renesas,r8a7795-imr-lx4\0renesas,imr-lx4";
			reg = <0x00 0xfe890000 0x00 0x2000>;
			interrupts = <0x00 0xc3 0x04>;
			clocks = <0x0c 0x01 0x334>;
			power-domains = <0x09 0x0e>;
			resets = <0x0c 0x334>;
			alloc-dev = <0xb1>;
		};

		vcp4@fe90f000 {
			compatible = "renesas,vcp4-fcpcs";
			reg = <0x00 0xfe90f000 0x00 0x200>;
			clocks = <0x0c 0x01 0x26b>;
			power-domains = <0x09 0x0e>;
			resets = <0x0c 0x26b>;
			renesas,#ch = <0x00>;
			phandle = <0x19d>;
		};

		vcp4@fe8d0000 {
			compatible = "renesas,vcp4-ivdp1c";
			reg = <0x00 0xfe8d0000 0x00 0x200 0x00 0xfe8d0200 0x00 0x200>;
			interrupts = <0x00 0x17c 0x04 0x00 0x17d 0x04 0x00 0xdf 0x04>;
			clocks = <0x0c 0x01 0x82>;
			power-domains = <0x09 0x1a>;
			resets = <0x0c 0x82>;
			renesas,#ch = <0x02>;
			renesas,#fcp_ch = <0x00>;
			phandle = <0x19e>;
		};

		vcp4@fe910000 {
			compatible = "renesas,vcp4-vcplf";
			reg = <0x00 0xfe910000 0x00 0x200 0x00 0xfe910200 0x00 0x200>;
			interrupts = <0x00 0x104 0x04 0x00 0x105 0x04>;
			clocks = <0x0c 0x01 0x82>;
			power-domains = <0x09 0x1a>;
			resets = <0x0c 0x82>;
			renesas,#ch = <0x00>;
			renesas,#fcp_ch = <0x00>;
			phandle = <0x19f>;
		};

		vcp4@fe900000 {
			compatible = "renesas,vcp4-vdpb";
			reg = <0x00 0xfe900000 0x00 0x200 0x00 0xfe900200 0x00 0x200>;
			interrupts = <0x00 0xf0 0x04 0x00 0xf1 0x04>;
			clocks = <0x0c 0x01 0x83>;
			power-domains = <0x09 0x1a>;
			resets = <0x0c 0x83>;
			renesas,#ch = <0x01>;
			renesas,#fcp_ch = <0x00>;
			phandle = <0x1a0>;
		};

		fdpm@fe940000 {
			compatible = "renesas,fdpm";
			reg = <0x00 0xfe940000 0x00 0x2400 0x00 0xfe950000 0x00 0x200>;
			interrupts = <0x00 0x106 0x04>;
			clocks = <0x0c 0x01 0x77 0x0c 0x01 0x267>;
			clock-names = "fdp\0fcp";
			power-domains = <0x09 0x09>;
			resets = <0x0c 0x77 0x0c 0x267>;
			reset-names = "fdp\0fcp";
			renesas,#ch = <0x00>;
			phandle = <0x1a1>;
		};

		fdpm@fe944000 {
			compatible = "renesas,fdpm";
			reg = <0x00 0xfe944000 0x00 0x2400 0x00 0xfe951000 0x00 0x200>;
			interrupts = <0x00 0x107 0x04>;
			clocks = <0x0c 0x01 0x76 0x0c 0x01 0x266>;
			clock-names = "fdp\0fcp";
			power-domains = <0x09 0x09>;
			resets = <0x0c 0x76 0x0c 0x266>;
			reset-names = "fdp\0fcp";
			renesas,#ch = <0x01>;
			phandle = <0x1a2>;
		};

		fcp@fea27000 {
			compatible = "renesas,fcpv";
			reg = <0x00 0xfea27000 0x00 0x200>;
			clocks = <0x0c 0x01 0x25b>;
			power-domains = <0x09 0x20>;
			resets = <0x0c 0x25b>;
			phandle = <0xb2>;
		};

		fcp@fea2f000 {
			compatible = "renesas,fcpv";
			reg = <0x00 0xfea2f000 0x00 0x200>;
			clocks = <0x0c 0x01 0x25a>;
			power-domains = <0x09 0x20>;
			resets = <0x0c 0x25a>;
			phandle = <0xb3>;
		};

		fcp@fea37000 {
			compatible = "renesas,fcpv";
			reg = <0x00 0xfea37000 0x00 0x200>;
			clocks = <0x0c 0x01 0x259>;
			power-domains = <0x09 0x20>;
			resets = <0x0c 0x259>;
			phandle = <0xb4>;
		};

		vsp@fe920000 {
			compatible = "renesas,vspm-vsp2";
			reg = <0x00 0xfe920000 0x00 0x8000>;
			renesas,has-bru;
			renesas,has-lut;
			renesas,has-clu;
			renesas,has-hgo;
			renesas,#rpf = <0x05>;
			renesas,#uds = <0x00>;
			renesas,#wpf = <0x01>;
		};

		vspm@fe920000 {
			compatible = "renesas,vspm";
			reg = <0x00 0xfe920000 0x00 0x8000 0x00 0xfe92f000 0x00 0x200>;
			interrupts = <0x00 0x1d1 0x04>;
			clocks = <0x0c 0x01 0x270 0x0c 0x01 0x25e>;
			clock-names = "vsp\0fcp";
			renesas,#ch = <0x04>;
			renesas,#rpf = <0x1f>;
			renesas,#rpf_clut = <0x06>;
			renesas,#wpf_rot = <0x00>;
			renesas,has-lut;
			renesas,has-clu;
			renesas,has-hgo;
			renesas,has-bru;
			renesas,#read_outstanding = <0x00>;
			renesas,#start_reservation = <0x02>;
			renesas,#burst_access = <0x01>;
			power-domains = <0x09 0x09>;
			resets = <0x0c 0x270 0x0c 0x25e>;
			reset-names = "vsp\0fcp";
			status = "okay";
			phandle = <0x1a3>;
		};

		vsp@fe960000 {
			compatible = "renesas,vspm-vsp2";
			reg = <0x00 0xfe960000 0x00 0x8000>;
			renesas,has-bru;
			renesas,#rpf = <0x05>;
			renesas,#uds = <0x00>;
			renesas,#wpf = <0x01>;
		};

		vspm@fe960000 {
			compatible = "renesas,vspm";
			reg = <0x00 0xfe960000 0x00 0x8000 0x00 0xfe96f000 0x00 0x200>;
			interrupts = <0x00 0x10a 0x04>;
			clocks = <0x0c 0x01 0x272 0x0c 0x01 0x25f>;
			clock-names = "vsp\0fcp";
			renesas,#ch = <0x03>;
			renesas,#rpf = <0x1f>;
			renesas,#rpf_clut = <0x06>;
			renesas,#wpf_rot = <0x00>;
			renesas,has-bru;
			renesas,#read_outstanding = <0x00>;
			renesas,#start_reservation = <0x02>;
			renesas,#burst_access = <0x00>;
			power-domains = <0x09 0x09>;
			resets = <0x0c 0x272 0x0c 0x25f>;
			reset-names = "vsp\0fcp";
			status = "okay";
			phandle = <0x1a4>;
		};

		vsp@fea20000 {
			compatible = "renesas,vsp2";
			reg = <0x00 0xfea20000 0x00 0x5000>;
			interrupts = <0x00 0x1d2 0x04>;
			clocks = <0x0c 0x01 0x26f>;
			power-domains = <0x09 0x20>;
			resets = <0x0c 0x26f>;
			renesas,#brs = <0x02>;
			renesas,fcp = <0xb2>;
			phandle = <0xd1>;
		};

		vsp@fea28000 {
			compatible = "renesas,vsp2";
			reg = <0x00 0xfea28000 0x00 0x5000>;
			interrupts = <0x00 0x1d3 0x04>;
			clocks = <0x0c 0x01 0x26e>;
			power-domains = <0x09 0x20>;
			resets = <0x0c 0x26e>;
			renesas,fcp = <0xb3>;
			phandle = <0xd2>;
		};

		vsp@fea30000 {
			compatible = "renesas,vsp2";
			reg = <0x00 0xfea30000 0x00 0x5000>;
			interrupts = <0x00 0x1d4 0x04>;
			clocks = <0x0c 0x01 0x26d>;
			power-domains = <0x09 0x20>;
			resets = <0x0c 0x26d>;
			renesas,fcp = <0xb4>;
			phandle = <0xd3>;
		};

		vsp@fe9a0000 {
			compatible = "renesas,vspm-vsp2";
			reg = <0x00 0xfe9a0000 0x00 0x8000>;
			renesas,has-lut;
			renesas,has-clu;
			renesas,has-hgo;
			renesas,has-hgt;
			renesas,#rpf = <0x01>;
			renesas,#uds = <0x01>;
			renesas,#wpf = <0x01>;
		};

		vspm@fe9a0000 {
			compatible = "renesas,vspm";
			reg = <0x00 0xfe9a0000 0x00 0x8000 0x00 0xfe9af000 0x00 0x200>;
			interrupts = <0x00 0x1bc 0x04>;
			clocks = <0x0c 0x01 0x277 0x0c 0x01 0x263>;
			clock-names = "vsp\0fcp";
			renesas,#ch = <0x00>;
			renesas,#rpf = <0x01>;
			renesas,#rpf_clut = <0x01>;
			renesas,#wpf_rot = <0x01>;
			renesas,has-sru;
			renesas,has-uds;
			renesas,has-lut;
			renesas,has-clu;
			renesas,has-hst;
			renesas,has-hsi;
			renesas,has-hgo;
			renesas,has-hgt;
			renesas,has-shp;
			renesas,#read_outstanding = <0x02>;
			renesas,#start_reservation = <0x02>;
			power-domains = <0x09 0x09>;
			resets = <0x0c 0x277 0x0c 0x263>;
			reset-names = "vsp\0fcp";
			status = "okay";
			phandle = <0x1a5>;
		};

		vsp@fe9b0000 {
			compatible = "renesas,vspm-vsp2";
			reg = <0x00 0xfe9b0000 0x00 0x8000>;
			renesas,has-lut;
			renesas,has-clu;
			renesas,has-hgo;
			renesas,has-hgt;
			renesas,#rpf = <0x01>;
			renesas,#uds = <0x01>;
			renesas,#wpf = <0x01>;
		};

		vspm@fe9b0000 {
			compatible = "renesas,vspm";
			reg = <0x00 0xfe9b0000 0x00 0x8000 0x00 0xfe9bf000 0x00 0x200>;
			interrupts = <0x00 0x1bd 0x04>;
			clocks = <0x0c 0x01 0x276 0x0c 0x01 0x262>;
			clock-names = "vsp\0fcp";
			renesas,#ch = <0x01>;
			renesas,#rpf = <0x01>;
			renesas,#rpf_clut = <0x01>;
			renesas,#wpf_rot = <0x01>;
			renesas,has-sru;
			renesas,has-uds;
			renesas,has-lut;
			renesas,has-clu;
			renesas,has-hst;
			renesas,has-hsi;
			renesas,has-hgo;
			renesas,has-hgt;
			renesas,has-shp;
			renesas,#read_outstanding = <0x02>;
			renesas,#start_reservation = <0x02>;
			power-domains = <0x09 0x09>;
			resets = <0x0c 0x276 0x0c 0x262>;
			reset-names = "vsp\0fcp";
			status = "okay";
			phandle = <0x1a6>;
		};

		cmm@fea40000 {
			compatible = "renesas,r8a7795-cmm\0renesas,rcar-gen3-cmm";
			reg = <0x00 0xfea40000 0x00 0x1000>;
			power-domains = <0x09 0x20>;
			clocks = <0x0c 0x01 0x2c7>;
			resets = <0x0c 0x2c7>;
			phandle = <0xcd>;
		};

		cmm@fea50000 {
			compatible = "renesas,r8a7795-cmm\0renesas,rcar-gen3-cmm";
			reg = <0x00 0xfea50000 0x00 0x1000>;
			power-domains = <0x09 0x20>;
			clocks = <0x0c 0x01 0x2c6>;
			resets = <0x0c 0x2c6>;
			phandle = <0xce>;
		};

		cmm@fea60000 {
			compatible = "renesas,r8a7795-cmm\0renesas,rcar-gen3-cmm";
			reg = <0x00 0xfea60000 0x00 0x1000>;
			power-domains = <0x09 0x20>;
			clocks = <0x0c 0x01 0x2c5>;
			resets = <0x0c 0x2c5>;
			phandle = <0xcf>;
		};

		cmm@fea70000 {
			compatible = "renesas,r8a7795-cmm\0renesas,rcar-gen3-cmm";
			reg = <0x00 0xfea70000 0x00 0x1000>;
			power-domains = <0x09 0x20>;
			clocks = <0x0c 0x01 0x2c4>;
			resets = <0x0c 0x2c4>;
			phandle = <0xd0>;
		};

		csi2@fea80000 {
			compatible = "renesas,r8a7795-csi2";
			reg = <0x00 0xfea80000 0x00 0x10000>;
			interrupts = <0x00 0xb8 0x04>;
			clocks = <0x0c 0x01 0x2ca>;
			power-domains = <0x09 0x20>;
			resets = <0x0c 0x2ca>;
			status = "okay";
			phandle = <0x1a7>;

			ports {
				#address-cells = <0x01>;
				#size-cells = <0x00>;

				port@0 {
					reg = <0x00>;

					endpoint {
						clock-lanes = <0x00>;
						data-lanes = <0x01 0x02>;
						remote-endpoint = <0xb5>;
						phandle = <0x41>;
					};
				};

				port@1 {
					#address-cells = <0x01>;
					#size-cells = <0x00>;
					reg = <0x01>;

					endpoint@0 {
						reg = <0x00>;
						remote-endpoint = <0xb6>;
						phandle = <0x5f>;
					};

					endpoint@1 {
						reg = <0x01>;
						remote-endpoint = <0xb7>;
						phandle = <0x61>;
					};

					endpoint@2 {
						reg = <0x02>;
						remote-endpoint = <0xb8>;
						phandle = <0x63>;
					};

					endpoint@3 {
						reg = <0x03>;
						remote-endpoint = <0xb9>;
						phandle = <0x65>;
					};

					endpoint@4 {
						reg = <0x04>;
						remote-endpoint = <0xba>;
						phandle = <0x67>;
					};

					endpoint@5 {
						reg = <0x05>;
						remote-endpoint = <0xbb>;
						phandle = <0x6a>;
					};

					endpoint@6 {
						reg = <0x06>;
						remote-endpoint = <0xbc>;
						phandle = <0x6d>;
					};

					endpoint@7 {
						reg = <0x07>;
						remote-endpoint = <0xbd>;
						phandle = <0x6f>;
					};
				};
			};
		};

		csi2@feaa0000 {
			compatible = "renesas,r8a7795-csi2";
			reg = <0x00 0xfeaa0000 0x00 0x10000>;
			interrupts = <0x00 0xf6 0x04>;
			clocks = <0x0c 0x01 0x2cc>;
			power-domains = <0x09 0x20>;
			resets = <0x0c 0x2cc>;
			status = "okay";
			phandle = <0x1a8>;

			ports {
				#address-cells = <0x01>;
				#size-cells = <0x00>;

				port@0 {
					reg = <0x00>;

					endpoint {
						clock-lanes = <0x00>;
						data-lanes = <0x01 0x02 0x03 0x04>;
						remote-endpoint = <0xbe>;
						phandle = <0x3b>;
					};
				};

				port@1 {
					#address-cells = <0x01>;
					#size-cells = <0x00>;
					reg = <0x01>;

					endpoint@0 {
						reg = <0x00>;
						remote-endpoint = <0xbf>;
						phandle = <0x60>;
					};

					endpoint@1 {
						reg = <0x01>;
						remote-endpoint = <0xc0>;
						phandle = <0x62>;
					};

					endpoint@2 {
						reg = <0x02>;
						remote-endpoint = <0xc1>;
						phandle = <0x64>;
					};

					endpoint@3 {
						reg = <0x03>;
						remote-endpoint = <0xc2>;
						phandle = <0x66>;
					};
				};
			};
		};

		csi2@feab0000 {
			compatible = "renesas,r8a7795-csi2";
			reg = <0x00 0xfeab0000 0x00 0x10000>;
			interrupts = <0x00 0xf7 0x04>;
			clocks = <0x0c 0x01 0x2cb>;
			power-domains = <0x09 0x20>;
			resets = <0x0c 0x2cb>;
			status = "disabled";
			phandle = <0x1a9>;

			ports {
				#address-cells = <0x01>;
				#size-cells = <0x00>;

				port@0 {
					reg = <0x00>;
				};

				port@1 {
					#address-cells = <0x01>;
					#size-cells = <0x00>;
					reg = <0x01>;

					endpoint@0 {
						reg = <0x00>;
						remote-endpoint = <0xc3>;
						phandle = <0x68>;
					};

					endpoint@1 {
						reg = <0x01>;
						remote-endpoint = <0xc4>;
						phandle = <0x6b>;
					};

					endpoint@2 {
						reg = <0x02>;
						remote-endpoint = <0xc5>;
						phandle = <0x6e>;
					};

					endpoint@3 {
						reg = <0x03>;
						remote-endpoint = <0xc6>;
						phandle = <0x70>;
					};
				};
			};
		};

		hdmi@fead0000 {
			compatible = "renesas,r8a7795-hdmi\0renesas,rcar-gen3-hdmi";
			reg = <0x00 0xfead0000 0x00 0x10000>;
			interrupts = <0x00 0x185 0x04>;
			clocks = <0x0c 0x01 0x2d9 0x0c 0x00 0x28>;
			clock-names = "iahb\0isfr";
			power-domains = <0x09 0x20>;
			resets = <0x0c 0x2d9>;
			status = "okay";
			phandle = <0x1aa>;

			ports {
				#address-cells = <0x01>;
				#size-cells = <0x00>;

				port@0 {
					reg = <0x00>;

					endpoint {
						remote-endpoint = <0xc7>;
						phandle = <0xd6>;
					};
				};

				port@1 {
					reg = <0x01>;

					endpoint {
						remote-endpoint = <0xc8>;
						phandle = <0xdc>;
					};
				};

				port@2 {
					reg = <0x02>;

					endpoint {
						remote-endpoint = <0x88>;
						phandle = <0x87>;
					};
				};
			};
		};

		hdmi@feae0000 {
			compatible = "renesas,r8a7795-hdmi\0renesas,rcar-gen3-hdmi";
			reg = <0x00 0xfeae0000 0x00 0x10000>;
			interrupts = <0x00 0x1b4 0x04>;
			clocks = <0x0c 0x01 0x2d8 0x0c 0x00 0x28>;
			clock-names = "iahb\0isfr";
			power-domains = <0x09 0x20>;
			resets = <0x0c 0x2d8>;
			status = "disabled";
			phandle = <0x1ab>;

			ports {
				#address-cells = <0x01>;
				#size-cells = <0x00>;

				port@0 {
					reg = <0x00>;

					endpoint {
						remote-endpoint = <0xc9>;
						phandle = <0xd7>;
					};
				};

				port@1 {
					reg = <0x01>;
				};

				port@2 {
					reg = <0x02>;
				};
			};
		};

		display@feb00000 {
			compatible = "renesas,du-r8a7795";
			reg = <0x00 0xfeb00000 0x00 0x80000>;
			interrupts = <0x00 0x100 0x04 0x00 0x10c 0x04 0x00 0x10d 0x04 0x00 0x10e 0x04>;
			clocks = <0x0c 0x01 0x2d4 0x0c 0x01 0x2d3 0x0c 0x01 0x2d2 0x0c 0x01 0x2d1 0xca 0x01 0xcb 0xcc 0xca 0x02>;
			clock-names = "du.0\0du.1\0du.2\0du.3\0dclkin.0\0dclkin.1\0dclkin.2\0dclkin.3";
			resets = <0x0c 0x2d4 0x0c 0x2d2>;
			reset-names = "du.0\0du.2";
			renesas,cmms = <0xcd 0xce 0xcf 0xd0>;
			renesas,vsps = <0xd1 0x00 0xd2 0x00 0xd3 0x00 0xd1 0x01>;
			status = "okay";
			pinctrl-0 = <0xd4>;
			pinctrl-names = "default";
			phandle = <0x1ac>;

			ports {
				#address-cells = <0x01>;
				#size-cells = <0x00>;

				port@0 {
					reg = <0x00>;

					endpoint {
						remote-endpoint = <0xd5>;
						phandle = <0x28>;
					};
				};

				port@1 {
					reg = <0x01>;

					endpoint {
						remote-endpoint = <0xd6>;
						phandle = <0xc7>;
					};
				};

				port@2 {
					reg = <0x02>;

					endpoint {
						remote-endpoint = <0xd7>;
						phandle = <0xc9>;
					};
				};

				port@3 {
					reg = <0x03>;

					endpoint {
						remote-endpoint = <0xd8>;
						phandle = <0xd9>;
					};
				};
			};
		};

		lvds@feb90000 {
			compatible = "renesas,r8a7795-lvds";
			reg = <0x00 0xfeb90000 0x00 0x14>;
			clocks = <0x0c 0x01 0x2d7>;
			power-domains = <0x09 0x20>;
			resets = <0x0c 0x2d7>;
			status = "okay";
			phandle = <0x1ad>;

			ports {
				#address-cells = <0x01>;
				#size-cells = <0x00>;

				port@0 {
					reg = <0x00>;

					endpoint {
						remote-endpoint = <0xd9>;
						phandle = <0xd8>;
					};
				};

				port@1 {
					reg = <0x01>;

					endpoint {
						remote-endpoint = <0xda>;
						phandle = <0xe5>;
					};
				};
			};
		};

		dma-controller@ffc10000 {
			compatible = "renesas,dmac-r8a7795\0renesas,rcar-dmac";
			reg = <0x00 0xffc10000 0x00 0x10000>;
			interrupts = <0x00 0x1c0 0x04 0x00 0x1c1 0x04 0x00 0x1c2 0x04 0x00 0x1c3 0x04 0x00 0x1c4 0x04 0x00 0x1c5 0x04 0x00 0x1c6 0x04 0x00 0x1c7 0x04 0x00 0x1c8 0x04>;
			interrupt-names = "error\0ch0\0ch1\0ch2\0ch3\0ch4\0ch5\0ch6\0ch7";
			clocks = <0x0c 0x01 0x15>;
			clock-names = "fck";
			power-domains = <0x09 0x20>;
			resets = <0x0c 0x15>;
			#dma-cells = <0x01>;
			dma-channels = <0x08>;
			phandle = <0x1ae>;
		};

		dma-controller@ffc20000 {
			compatible = "renesas,dmac-r8a7795\0renesas,rcar-dmac";
			reg = <0x00 0xffc20000 0x00 0x10000>;
			interrupts = <0x00 0x1d5 0x04 0x00 0x1c9 0x04 0x00 0x1ca 0x04 0x00 0x1cb 0x04 0x00 0x1cc 0x04 0x00 0x1cd 0x04 0x00 0x1ce 0x04 0x00 0x1cf 0x04 0x00 0x1d0 0x04>;
			interrupt-names = "error\0ch0\0ch1\0ch2\0ch3\0ch4\0ch5\0ch6\0ch7";
			clocks = <0x0c 0x01 0x10>;
			clock-names = "fck";
			power-domains = <0x09 0x20>;
			resets = <0x0c 0x10>;
			#dma-cells = <0x01>;
			dma-channels = <0x08>;
			phandle = <0x1af>;
		};

		chipid@fff00044 {
			compatible = "renesas,prr";
			reg = <0x00 0xfff00044 0x00 0x04>;
			phandle = <0x1b0>;
		};

		impdes0 {
			compatible = "renesas,impx4-distributer";
			reg = <0x00 0xffa00000 0x00 0x4000>;
			interrupts = <0x00 0x1b7 0x04>;
			clocks = <0x0c 0x01 0x338>;
			power-domains = <0x09 0x18>;
			interrupt-controller;
			#interrupt-cells = <0x01>;
			phandle = <0xdb>;
		};

		imp0 {
			compatible = "renesas,impx4-legacy";
			reg = <0x00 0xff900000 0x00 0x20000>;
			interrupt-parent = <0xdb>;
			interrupts = <0x00>;
			clocks = <0x0c 0x01 0x338>;
			power-domains = <0x09 0x18>;
		};

		imp1 {
			compatible = "renesas,impx4-legacy";
			reg = <0x00 0xff920000 0x00 0x20000>;
			interrupt-parent = <0xdb>;
			interrupts = <0x01>;
			clocks = <0x0c 0x01 0x338>;
			power-domains = <0x09 0x18>;
		};

		imp2 {
			compatible = "renesas,impx4-legacy";
			reg = <0x00 0xff940000 0x00 0x20000>;
			interrupt-parent = <0xdb>;
			interrupts = <0x02>;
			clocks = <0x0c 0x01 0x338>;
			power-domains = <0x09 0x18>;
		};

		imp3 {
			compatible = "renesas,impx4-legacy";
			reg = <0x00 0xff960000 0x00 0x20000>;
			interrupt-parent = <0xdb>;
			interrupts = <0x03>;
			clocks = <0x0c 0x01 0x338>;
			power-domains = <0x09 0x18>;
		};

		impsc0 {
			compatible = "renesas,impx4-shader";
			reg = <0x00 0xff980000 0x00 0x10000>;
			interrupt-parent = <0xdb>;
			interrupts = <0x04>;
			clocks = <0x0c 0x01 0x338>;
			power-domains = <0x09 0x18>;
		};

		impsc1 {
			compatible = "renesas,impx4-shader";
			reg = <0x00 0xff990000 0x00 0x10000>;
			interrupt-parent = <0xdb>;
			interrupts = <0x05>;
			clocks = <0x0c 0x01 0x338>;
			power-domains = <0x09 0x18>;
		};

		impsl0 {
			compatible = "renesas,impx4-legacy";
			reg = <0x00 0xff9c0000 0x00 0x10000>;
			interrupt-parent = <0xdb>;
			interrupts = <0x0c>;
			clocks = <0x0c 0x01 0x338>;
			power-domains = <0x09 0x18>;
		};

		impdm0 {
			compatible = "renesas,impx5-dmac";
			reg = <0x00 0xffa10000 0x00 0x4000>;
			interrupt-parent = <0xdb>;
			interrupts = <0x10>;
			clocks = <0x0c 0x01 0x338>;
			power-domains = <0x09 0x18>;
		};

		impc0 {
			compatible = "renesas,impx4-memory";
			reg = <0x00 0xffa40000 0x00 0x20000>;
			clocks = <0x0c 0x01 0x338>;
			power-domains = <0x09 0x18>;
		};

		imprtt {
			compatible = "renesas,impx5-rtt";
			reg = <0x00 0xff8d0000 0x00 0x1000 0x00 0xe6150000 0x00 0x1000>;
			interrupts = <0x00 0x189 0x04>;
			clocks = <0x0c 0x01 0x338>;
			power-domains = <0x09 0x18>;
		};

		imrlx4_imr0 {
			compatible = "generic-uio";
			reg = <0x00 0xfe860000 0x00 0x2000>;
			interrupts = <0x00 0xc0 0x04>;
			clocks = <0x0c 0x01 0x337>;
			power-domains = <0x09 0x0e>;
			resets = <0x0c 0x337>;
			linux,uio-name = "imr_00";
			ipmmu-id = <0x07 0x00>;
		};

		imrlx4_imr1 {
			compatible = "generic-uio";
			reg = <0x00 0xfe870000 0x00 0x2000>;
			interrupts = <0x00 0xc1 0x04>;
			clocks = <0x0c 0x01 0x336>;
			power-domains = <0x09 0x0e>;
			resets = <0x0c 0x336>;
			linux,uio-name = "imr_01";
			ipmmu-id = <0x07 0x00>;
		};

		imrlx4_imr2 {
			compatible = "generic-uio";
			reg = <0x00 0xfe880000 0x00 0x2000>;
			interrupts = <0x00 0xc2 0x04>;
			clocks = <0x0c 0x01 0x335>;
			power-domains = <0x09 0x0e>;
			resets = <0x0c 0x335>;
			linux,uio-name = "imr_02";
			ipmmu-id = <0x06 0x01>;
		};

		imrlx4_imr3 {
			compatible = "generic-uio";
			reg = <0x00 0xfe890000 0x00 0x2000>;
			interrupts = <0x00 0xc3 0x04>;
			clocks = <0x0c 0x01 0x334>;
			power-domains = <0x09 0x0e>;
			resets = <0x0c 0x334>;
			linux,uio-name = "imr_03";
			ipmmu-id = <0x06 0x01>;
		};
	};

	timer {
		compatible = "arm,armv8-timer";
		interrupts-extended = <0xad 0x01 0x0d 0xff08 0xad 0x01 0x0e 0xff08 0xad 0x01 0x0b 0xff08 0xad 0x01 0x0a 0xff08>;
	};

	usb3s0 {
		compatible = "fixed-clock";
		#clock-cells = <0x00>;
		clock-frequency = <0x00>;
		phandle = <0x52>;
	};

	usb_extal {
		compatible = "fixed-clock";
		#clock-cells = <0x00>;
		clock-frequency = <0x00>;
		phandle = <0x53>;
	};

	chosen {
		bootargs = "ignore_loglevel rw root=/dev/nfs ip=on";
		stdout-path = "serial0:115200n8";
	};

	audio-clkout {
		compatible = "fixed-clock";
		#clock-cells = <0x00>;
		clock-frequency = <0xbb8000>;
		phandle = <0x23>;
	};

	avb-mch {
		compatible = "renesas,avb-mch-gen3";
		reg = <0x00 0xec5a0100 0x00 0x100>;
		reg-name = "adg_avb";
		clocks = <0x0c 0x01 0x39a>;
		clock-names = "adg";
		resets = <0x0c 0x39a>;
		reset-names = "adg";
	};

	hdmi0-out {
		compatible = "hdmi-connector";
		type = "a";

		port {

			endpoint {
				remote-endpoint = <0xdc>;
				phandle = <0xc8>;
			};
		};
	};

	keyboard {
		compatible = "gpio-keys";

		key-1 {
			linux,code = <0x02>;
			label = "SW3";
			wakeup-source;
			debounce-interval = <0x14>;
			gpios = <0x2e 0x0b 0x01>;
		};
	};

	leds {
		compatible = "gpio-leds";

		led5 {
			gpios = <0x2e 0x0c 0x00>;
		};

		led6 {
			gpios = <0x2e 0x0d 0x00>;
		};
	};

	regulator0 {
		compatible = "regulator-fixed";
		regulator-name = "fixed-1.8V";
		regulator-min-microvolt = <0x1b7740>;
		regulator-max-microvolt = <0x1b7740>;
		regulator-boot-on;
		regulator-always-on;
		phandle = <0xa1>;
	};

	regulator1 {
		compatible = "regulator-fixed";
		regulator-name = "fixed-3.3V";
		regulator-min-microvolt = <0x325aa0>;
		regulator-max-microvolt = <0x325aa0>;
		regulator-boot-on;
		regulator-always-on;
		phandle = <0xa0>;
	};

	regulator-vcc-sdhi0 {
		compatible = "regulator-fixed";
		regulator-name = "SDHI0 Vcc";
		regulator-min-microvolt = <0x325aa0>;
		regulator-max-microvolt = <0x325aa0>;
		gpio = <0x26 0x02 0x00>;
		enable-active-high;
		phandle = <0x9c>;
	};

	regulator-vccq-sdhi0 {
		compatible = "regulator-gpio";
		regulator-name = "SDHI0 VccQ";
		regulator-min-microvolt = <0x1b7740>;
		regulator-max-microvolt = <0x325aa0>;
		gpios = <0x26 0x01 0x00>;
		gpios-states = <0x01>;
		states = <0x325aa0 0x01 0x1b7740 0x00>;
		phandle = <0x9d>;
	};

	x12 {
		compatible = "fixed-clock";
		#clock-cells = <0x00>;
		clock-frequency = <0x1770000>;
		phandle = <0x24>;
	};

	x23-clock {
		compatible = "fixed-clock";
		#clock-cells = <0x00>;
		clock-frequency = <0x17d7840>;
		phandle = <0x30>;
	};

	memory@48000000 {
		device_type = "memory";
		reg = <0x00 0x48000000 0x00 0x38000000>;
	};

	memory@500000000 {
		device_type = "memory";
		reg = <0x05 0x00 0x00 0x40000000>;
	};

	memory@600000000 {
		device_type = "memory";
		reg = <0x06 0x00 0x00 0x40000000>;
	};

	memory@700000000 {
		device_type = "memory";
		reg = <0x07 0x00 0x00 0x40000000>;
	};

	reserved-memory {
		#address-cells = <0x02>;
		#size-cells = <0x02>;
		ranges;

		linux,lossy_decompress@54000000 {
			no-map;
			reg = <0x00 0x54000000 0x00 0x3000000>;
			phandle = <0xde>;
		};

		linux,cma@57000000 {
			compatible = "shared-dma-pool";
			reusable;
			reg = <0x00 0x57000000 0x00 0x19000000>;
			linux,cma-default;
		};

		linux,multimedia@70000000 {
			compatible = "shared-dma-pool";
			reusable;
			reg = <0x00 0x70000000 0x00 0x10000000>;
			phandle = <0xdd>;
		};
	};

	mmngr {
		compatible = "renesas,mmngr";
		memory-region = <0xdd 0xde>;
	};

	mmngrbuf {
		compatible = "renesas,mmngrbuf";
	};

	vspm_if {
		compatible = "renesas,vspm_if";
	};

	versaclk-3 {
		compatible = "fixed-clock";
		#clock-cells = <0x00>;
		clock-frequency = <0x1f78a40>;
		phandle = <0xcb>;
	};

	versaclk-4 {
		compatible = "fixed-clock";
		#clock-cells = <0x00>;
		clock-frequency = <0x1f78a40>;
		phandle = <0xcc>;
	};

	clksndsel {
		#clock-cells = <0x00>;
		compatible = "gpio-mux-clock";
		clocks = <0x25 0x79>;
		select-gpios = <0x27 0x0d 0x00>;
		phandle = <0x2a>;
	};

	regulator-snd_3p3v {
		compatible = "regulator-fixed";
		regulator-name = "snd-3.3v";
		regulator-min-microvolt = <0x325aa0>;
		regulator-max-microvolt = <0x325aa0>;
		phandle = <0x2b>;
	};

	regulator-snd_vcc5v {
		compatible = "regulator-fixed";
		regulator-name = "snd-vcc5v";
		regulator-min-microvolt = <0x4c4b40>;
		regulator-max-microvolt = <0x4c4b40>;
		phandle = <0x2c>;
	};

	regulator-wlan_en {
		compatible = "regulator-fixed";
		regulator-name = "wlan-en-regulator";
		regulator-min-microvolt = <0x325aa0>;
		regulator-max-microvolt = <0x325aa0>;
		gpio = <0x4a 0x04 0x00>;
		startup-delay-us = <0x11170>;
		enable-active-high;
		phandle = <0xa3>;
	};

	regulator@9 {
		compatible = "regulator-fixed";
		regulator-name = "SD WiFi mux";
		regulator-min-microvolt = <0x325aa0>;
		regulator-max-microvolt = <0x325aa0>;
		gpio = <0x4a 0x05 0x00>;
		enable-active-low;
		regulator-always-on;
		phandle = <0x1b1>;
	};

	regulator@11 {
		compatible = "regulator-fixed";
		regulator-name = "radio_on";
		regulator-min-microvolt = <0x325aa0>;
		regulator-max-microvolt = <0x325aa0>;
		gpio = <0x4a 0x0d 0x00>;
		enable-active-high;
		regulator-always-on;
		phandle = <0x1b2>;
	};

	regulator@12 {
		compatible = "regulator-fixed";
		regulator-name = "mPCIe 3v3";
		regulator-min-microvolt = <0x325aa0>;
		regulator-max-microvolt = <0x325aa0>;
		gpio = <0xdf 0x0e 0x00>;
		enable-active-high;
		phandle = <0xaf>;
	};

	regulator@13 {
		compatible = "regulator-fixed";
		regulator-name = "mPCIe 1v8";
		regulator-min-microvolt = <0x1b7740>;
		regulator-max-microvolt = <0x1b7740>;
		gpio = <0xdf 0x0f 0x00>;
		startup-delay-us = <0x30d40>;
		enable-active-high;
		phandle = <0xb0>;
	};

	regulator@14 {
		compatible = "regulator-fixed";
		regulator-name = "Video-A PWR0";
		regulator-min-microvolt = <0xb71b00>;
		regulator-max-microvolt = <0xb71b00>;
		gpio = <0x32 0x09 0x00>;
		enable-active-high;
		phandle = <0x33>;
	};

	regulator@15 {
		compatible = "regulator-fixed";
		regulator-name = "Video-A PWR1";
		regulator-min-microvolt = <0xb71b00>;
		regulator-max-microvolt = <0xb71b00>;
		gpio = <0x32 0x08 0x00>;
		enable-active-high;
		phandle = <0x34>;
	};

	regulator@16 {
		compatible = "regulator-fixed";
		regulator-name = "Video-A PWR2";
		regulator-min-microvolt = <0xb71b00>;
		regulator-max-microvolt = <0xb71b00>;
		gpio = <0x32 0x0b 0x00>;
		enable-active-high;
		phandle = <0x35>;
	};

	regulator@17 {
		compatible = "regulator-fixed";
		regulator-name = "Video-A PWR3";
		regulator-min-microvolt = <0xb71b00>;
		regulator-max-microvolt = <0xb71b00>;
		gpio = <0x32 0x0a 0x00>;
		enable-active-high;
		phandle = <0x36>;
	};

	kim {
		compatible = "kim";
		shutdown-gpios = <0x4a 0x03 0x00>;
		dev_name = "/dev/ttySC1";
		flow_cntrl = <0x01>;
		baud_rate = <0x32dcd4>;
	};

	sound@0 {
		compatible = "audio-graph-card";
		label = "ak4613";
		dais = <0xe0 0xe1>;
		phandle = <0x1b3>;
	};

	sound@1 {
		compatible = "audio-graph-card";
		label = "pcm3168a";
		dais = <0xe2>;
		phandle = <0x1b4>;
	};

	sound@2 {
		compatible = "audio-graph-card";
		label = "radio";
		dais = <0xe3>;
		phandle = <0x1b5>;
	};

	sound@3 {
		compatible = "audio-graph-card";
		label = "wl18xx";
		dais = <0xe4>;
		phandle = <0x1b6>;
	};

	lvds {
		compatible = "panel-lvds";
		width-mm = <0xd2>;
		height-mm = <0x9e>;
		data-mapping = "jeida-24";
		phandle = <0x1b7>;

		port {

			endpoint {
				remote-endpoint = <0xe5>;
				phandle = <0xda>;
			};
		};

		panel-timing {
			clock-frequency = <0x3dfd240>;
			hactive = <0x500>;
			vactive = <0x320>;
			hsync-len = <0x28>;
			hfront-porch = <0x50>;
			hback-porch = <0x28>;
			vfront-porch = <0x0e>;
			vback-porch = <0x0e>;
			vsync-len = <0x04>;
		};
	};

	hdmi-out {
		compatible = "hdmi-connector";
		type = "a";

		port {

			endpoint {
				remote-endpoint = <0xe6>;
				phandle = <0x29>;
			};
		};
	};

	si468x@0 {
		compatible = "si,si468x-pcm";
		status = "okay";
		phandle = <0x1b8>;

		port {

			endpoint {
				remote-endpoint = <0xe7>;
				system-clock-frequency = <0xbb8000>;
				phandle = <0x8d>;
			};
		};
	};

	wl18xx_pcm@0 {
		compatible = "ti,wl18xx-pcm";
		status = "okay";
		phandle = <0x1b9>;

		port {

			endpoint {
				remote-endpoint = <0xe8>;
				phandle = <0x8f>;
			};
		};
	};

	camera_clk {
		compatible = "fixed-clock";
		#clock-cells = <0x00>;
		clock-frequency = <0x16e3600>;
		clock-output-names = "mclk";
		phandle = <0x42>;
	};

	ov5647_camera_clk {
		compatible = "fixed-clock";
		#clock-cells = <0x00>;
		clock-frequency = <0x17d7840>;
		clock-output-names = "xclk";
		phandle = <0x40>;
	};

	passthrough {
	};

	__symbols__ {
		audio_clk_a = "/audio_clk_a";
		audio_clk_b = "/audio_clk_b";
		audio_clk_c = "/audio_clk_c";
		can_clk = "/can";
		cluster0_opp0 = "/opp_table0";
		cluster0_opp1 = "/opp_table1";
		cluster0_opp2 = "/opp_table2";
		cluster0_opp3 = "/opp_table3";
		cluster0_opp4 = "/opp_table4";
		cluster0_opp5 = "/opp_table5";
		cluster0_opp6 = "/opp_table6";
		cluster0_opp7 = "/opp_table7";
		cluster1_opp = "/opp_table10";
		a57_0 = "/cpus/cpu@0";
		a57_1 = "/cpus/cpu@1";
		a57_2 = "/cpus/cpu@2";
		a57_3 = "/cpus/cpu@3";
		a53_0 = "/cpus/cpu@100";
		a53_1 = "/cpus/cpu@101";
		a53_2 = "/cpus/cpu@102";
		a53_3 = "/cpus/cpu@103";
		L2_CA57 = "/cpus/cache-controller-0";
		L2_CA53 = "/cpus/cache-controller-1";
		CPU_SLEEP_0 = "/cpus/idle-states/cpu-sleep-0";
		CPU_SLEEP_1 = "/cpus/idle-states/cpu-sleep-1";
		extal_clk = "/extal";
		extalr_clk = "/extalr";
		gsx_opp0 = "/gsx_opp_table0";
		gsx_opp1 = "/gsx_opp_table1";
		gsx_opp2 = "/gsx_opp_table2";
		gsx_opp3 = "/gsx_opp_table3";
		gsx_opp4 = "/gsx_opp_table4";
		gsx_opp5 = "/gsx_opp_table5";
		gsx_opp6 = "/gsx_opp_table6";
		gsx_opp7 = "/gsx_opp_table7";
		pcie_bus_clk = "/pcie_bus";
		scif_clk = "/scif";
		soc = "/soc";
		mfis = "/soc/mfis@e6260000";
		rwdt = "/soc/watchdog@e6020000";
		gpio0 = "/soc/gpio@e6050000";
		gpio1 = "/soc/gpio@e6051000";
		gpio2 = "/soc/gpio@e6052000";
		gpio3 = "/soc/gpio@e6053000";
		gpio4 = "/soc/gpio@e6054000";
		gpio5 = "/soc/gpio@e6055000";
		gpio6 = "/soc/gpio@e6055400";
		gpio7 = "/soc/gpio@e6055800";
		pfc = "/soc/pinctrl@e6060000";
		avb_pins = "/soc/pinctrl@e6060000/avb";
		i2c2_pins = "/soc/pinctrl@e6060000/i2c2";
		irq0_pins = "/soc/pinctrl@e6060000/irq0";
		scif2_pins = "/soc/pinctrl@e6060000/scif2";
		scif_clk_pins = "/soc/pinctrl@e6060000/scif_clk";
		sdhi0_pins = "/soc/pinctrl@e6060000/sd0";
		sdhi0_pins_uhs = "/soc/pinctrl@e6060000/sd0_uhs";
		sdhi2_pins = "/soc/pinctrl@e6060000/sd2";
		sound_pins = "/soc/pinctrl@e6060000/sound";
		sound_clk_pins = "/soc/pinctrl@e6060000/sound-clk";
		usb1_pins = "/soc/pinctrl@e6060000/usb1";
		can0_pins = "/soc/pinctrl@e6060000/can0";
		can1_pins = "/soc/pinctrl@e6060000/can1";
		canfd0_pins = "/soc/pinctrl@e6060000/canfd0";
		canfd1_pins = "/soc/pinctrl@e6060000/canfd1";
		du_pins = "/soc/pinctrl@e6060000/du";
		hscif0_pins = "/soc/pinctrl@e6060000/hscif0";
		hscif1_pins = "/soc/pinctrl@e6060000/hscif1";
		scif1_pins = "/soc/pinctrl@e6060000/scif1";
		sdhi3_pins = "/soc/pinctrl@e6060000/sdhi3";
		sound_pcm_pins = "/soc/pinctrl@e6060000/sound-pcm";
		usb0_pins = "/soc/pinctrl@e6060000/usb0";
		vin5_pins = "/soc/pinctrl@e6060000/vin5";
		cmt0 = "/soc/timer@e60f0000";
		cmt1 = "/soc/timer@e6130000";
		cmt2 = "/soc/timer@e6140000";
		cmt3 = "/soc/timer@e6148000";
		avs = "/soc/avs@e60a013c";
		cpg = "/soc/clock-controller@e6150000";
		rst = "/soc/reset-controller@e6160000";
		sysc = "/soc/system-controller@e6180000";
		tsc = "/soc/thermal@e6198000";
		intc_ex = "/soc/interrupt-controller@e61c0000";
		tmu0 = "/soc/timer@e61e0000";
		tmu1 = "/soc/timer@e6fc0000";
		tmu2 = "/soc/timer@e6fd0000";
		tmu3 = "/soc/timer@e6fe0000";
		tmu4 = "/soc/timer@ffc00000";
		i2c0 = "/soc/i2c@e6500000";
		i2c1 = "/soc/i2c@e6508000";
		i2c2 = "/soc/i2c@e6510000";
		ak4613 = "/soc/i2c@e6510000/codec@10";
		ak4613_endpoint = "/soc/i2c@e6510000/codec@10/port/endpoint";
		cs2000 = "/soc/i2c@e6510000/clk-multiplier@4f";
		i2cswitch2 = "/soc/i2c@e6510000/i2c-switch@71";
		adv7513_in = "/soc/i2c@e6510000/i2c-switch@71/i2c@4/hdmi@3d/ports/port@0/endpoint";
		adv7513_out = "/soc/i2c@e6510000/i2c-switch@71/i2c@4/hdmi@3d/ports/port@1/endpoint";
		polytouch = "/soc/i2c@e6510000/i2c-switch@71/i2c@6/edt-ft5x06@38";
		pcm3168a = "/soc/i2c@e6510000/i2c-switch@71/i2c@7/audio-codec@44";
		pcm3168a_endpoint = "/soc/i2c@e6510000/i2c-switch@71/i2c@7/audio-codec@44/port/endpoint";
		gpio_exp_74 = "/soc/i2c@e6510000/gpio@74";
		gpio_exp_75 = "/soc/i2c@e6510000/gpio@75";
		i2c3 = "/soc/i2c@e66d0000";
		i2c4 = "/soc/i2c@e66d8000";
		versaclock5 = "/soc/i2c@e66d8000/clock-generator@6a";
		i2cswitch4 = "/soc/i2c@e66d8000/i2c-switch@71";
		i2cswitch4_i2c1 = "/soc/i2c@e66d8000/i2c-switch@71/i2c@1";
		deser_in0 = "/soc/i2c@e66d8000/i2c-switch@71/i2c@1/deser@2c/ports/port@0/endpoint";
		deser_in1 = "/soc/i2c@e66d8000/i2c-switch@71/i2c@1/deser@2c/ports/port@1/endpoint";
		deser_in2 = "/soc/i2c@e66d8000/i2c-switch@71/i2c@1/deser@2c/ports/port@2/endpoint";
		deser_in3 = "/soc/i2c@e66d8000/i2c-switch@71/i2c@1/deser@2c/ports/port@3/endpoint";
		deser_out0 = "/soc/i2c@e66d8000/i2c-switch@71/i2c@1/deser@2c/ports/port@4/endpoint";
		camera_out0 = "/soc/i2c@e66d8000/i2c-switch@71/i2c@1/deser@2c/i2c@0/camera@60/port/endpoint";
		camera_out1 = "/soc/i2c@e66d8000/i2c-switch@71/i2c@1/deser@2c/i2c@1/camera@61/port/endpoint";
		camera_out2 = "/soc/i2c@e66d8000/i2c-switch@71/i2c@1/deser@2c/i2c@2/camera@62/port/endpoint";
		camera_out3 = "/soc/i2c@e66d8000/i2c-switch@71/i2c@1/deser@2c/i2c@3/camera@63/port/endpoint";
		ov5647_camera = "/soc/i2c@e66d8000/i2c-switch@71/i2c@4/ov5647@36";
		ov5647_camera_out = "/soc/i2c@e66d8000/i2c-switch@71/i2c@4/ov5647@36/port@0/endpoint";
		cmos_camera = "/soc/i2c@e66d8000/i2c-switch@71/i2c@5/ov5642@3c";
		cmos_camera_out = "/soc/i2c@e66d8000/i2c-switch@71/i2c@5/ov5642@3c/port@0/endpoint";
		i2cswitch4_i2c7 = "/soc/i2c@e66d8000/i2c-switch@71/i2c@7";
		gpio_exp_a_5c = "/soc/i2c@e66d8000/i2c-switch@71/i2c@7/gpio@5c";
		gpio_exp_76 = "/soc/i2c@e66d8000/gpio@76";
		gpio_exp_77 = "/soc/i2c@e66d8000/gpio@77";
		i2c5 = "/soc/i2c@e66e0000";
		i2c6 = "/soc/i2c@e66e8000";
		i2c_dvfs = "/soc/i2c@e60b0000";
		pmic = "/soc/i2c@e60b0000/pmic@30";
		dvfs = "/soc/i2c@e60b0000/pmic@30/regulators/dvfs";
		hscif0 = "/soc/serial@e6540000";
		hscif1 = "/soc/serial@e6550000";
		hscif2 = "/soc/serial@e6560000";
		hscif3 = "/soc/serial@e66a0000";
		hscif4 = "/soc/serial@e66b0000";
		hsusb = "/soc/usb@e6590000";
		hsusb3 = "/soc/usb@e659c000";
		usb_dmac0 = "/soc/dma-controller@e65a0000";
		usb_dmac1 = "/soc/dma-controller@e65b0000";
		usb_dmac2 = "/soc/dma-controller@e6460000";
		usb_dmac3 = "/soc/dma-controller@e6470000";
		usb3_phy0 = "/soc/usb-phy@e65ee000";
		arm_cc630p = "/soc/crypto@e6601000";
		dmac0 = "/soc/dma-controller@e6700000";
		dmac1 = "/soc/dma-controller@e7300000";
		dmac2 = "/soc/dma-controller@e7310000";
		ipmmu_mm = "/soc/iommu@e67b0000";
		ipmmu_ds0 = "/soc/iommu@e6740000";
		ipmmu_ds1 = "/soc/iommu@e7740000";
		ipmmu_hc = "/soc/iommu@e6570000";
		ipmmu_ir = "/soc/iommu@ff8b0000";
		ipmmu_mp0 = "/soc/iommu@ec670000";
		ipmmu_pv0 = "/soc/iommu@fd800000";
		ipmmu_pv1 = "/soc/iommu@fd950000";
		ipmmu_pv2 = "/soc/iommu@fd960000";
		ipmmu_pv3 = "/soc/iommu@fd970000";
		ipmmu_rt = "/soc/iommu@ffc80000";
		ipmmu_vc0 = "/soc/iommu@fe6b0000";
		ipmmu_vc1 = "/soc/iommu@fe6f0000";
		ipmmu_vi0 = "/soc/iommu@febd0000";
		ipmmu_vi1 = "/soc/iommu@febe0000";
		ipmmu_vp0 = "/soc/iommu@fe990000";
		ipmmu_vp1 = "/soc/iommu@fe980000";
		avb = "/soc/ethernet@e6800000";
		phy0 = "/soc/ethernet@e6800000/ethernet-phy@0";
		can0 = "/soc/can@e6c30000";
		can1 = "/soc/can@e6c38000";
		canfd = "/soc/can@e66c0000";
		pwm0 = "/soc/pwm@e6e30000";
		pwm1 = "/soc/pwm@e6e31000";
		pwm2 = "/soc/pwm@e6e32000";
		pwm3 = "/soc/pwm@e6e33000";
		pwm4 = "/soc/pwm@e6e34000";
		pwm5 = "/soc/pwm@e6e35000";
		pwm6 = "/soc/pwm@e6e36000";
		scif0 = "/soc/serial@e6e60000";
		scif1 = "/soc/serial@e6e68000";
		scif2 = "/soc/serial@e6e88000";
		scif3 = "/soc/serial@e6c50000";
		scif4 = "/soc/serial@e6c40000";
		scif5 = "/soc/serial@e6f30000";
		tpu = "/soc/pwm@e6e80000";
		mlp = "/soc/mlp@ec520000";
		msiof0 = "/soc/spi@e6e90000";
		msiof1 = "/soc/spi@e6ea0000";
		msiof2 = "/soc/spi@e6c00000";
		msiof3 = "/soc/spi@e6c10000";
		rpc0 = "/soc/rpc0@ee200000";
		vin0 = "/soc/video@e6ef0000";
		vin0csi20 = "/soc/video@e6ef0000/ports/port@1/endpoint@0";
		vin0csi40 = "/soc/video@e6ef0000/ports/port@1/endpoint@2";
		vin1 = "/soc/video@e6ef1000";
		vin1csi20 = "/soc/video@e6ef1000/ports/port@1/endpoint@0";
		vin1csi40 = "/soc/video@e6ef1000/ports/port@1/endpoint@2";
		vin2 = "/soc/video@e6ef2000";
		vin2csi20 = "/soc/video@e6ef2000/ports/port@1/endpoint@0";
		vin2csi40 = "/soc/video@e6ef2000/ports/port@1/endpoint@2";
		vin3 = "/soc/video@e6ef3000";
		vin3csi20 = "/soc/video@e6ef3000/ports/port@1/endpoint@0";
		vin3csi40 = "/soc/video@e6ef3000/ports/port@1/endpoint@2";
		vin4 = "/soc/video@e6ef4000";
		vin4csi20 = "/soc/video@e6ef4000/ports/port@1/endpoint@0";
		vin4csi41 = "/soc/video@e6ef4000/ports/port@1/endpoint@3";
		vin5 = "/soc/video@e6ef5000";
		vin5csi20 = "/soc/video@e6ef5000/ports/port@1/endpoint@0";
		vin5csi41 = "/soc/video@e6ef5000/ports/port@1/endpoint@3";
		vin5_in = "/soc/video@e6ef5000/ports/port@0/endpoint@0";
		vin6 = "/soc/video@e6ef6000";
		vin6csi20 = "/soc/video@e6ef6000/ports/port@1/endpoint@0";
		vin6csi41 = "/soc/video@e6ef6000/ports/port@1/endpoint@3";
		vin7 = "/soc/video@e6ef7000";
		vin7csi20 = "/soc/video@e6ef7000/ports/port@1/endpoint@0";
		vin7csi41 = "/soc/video@e6ef7000/ports/port@1/endpoint@3";
		drif00 = "/soc/rif@e6f40000";
		drif01 = "/soc/rif@e6f50000";
		drif10 = "/soc/rif@e6f60000";
		drif11 = "/soc/rif@e6f70000";
		drif20 = "/soc/rif@e6f80000";
		drif21 = "/soc/rif@e6f90000";
		drif30 = "/soc/rif@e6fa0000";
		drif31 = "/soc/rif@e6fb0000";
		rcar_sound = "/soc/sound@ec500000";
		dvc0 = "/soc/sound@ec500000/rcar_sound,dvc/dvc-0";
		dvc1 = "/soc/sound@ec500000/rcar_sound,dvc/dvc-1";
		mix0 = "/soc/sound@ec500000/rcar_sound,mix/mix-0";
		mix1 = "/soc/sound@ec500000/rcar_sound,mix/mix-1";
		ctu00 = "/soc/sound@ec500000/rcar_sound,ctu/ctu-0";
		ctu01 = "/soc/sound@ec500000/rcar_sound,ctu/ctu-1";
		ctu02 = "/soc/sound@ec500000/rcar_sound,ctu/ctu-2";
		ctu03 = "/soc/sound@ec500000/rcar_sound,ctu/ctu-3";
		ctu10 = "/soc/sound@ec500000/rcar_sound,ctu/ctu-4";
		ctu11 = "/soc/sound@ec500000/rcar_sound,ctu/ctu-5";
		ctu12 = "/soc/sound@ec500000/rcar_sound,ctu/ctu-6";
		ctu13 = "/soc/sound@ec500000/rcar_sound,ctu/ctu-7";
		src0 = "/soc/sound@ec500000/rcar_sound,src/src-0";
		src1 = "/soc/sound@ec500000/rcar_sound,src/src-1";
		src2 = "/soc/sound@ec500000/rcar_sound,src/src-2";
		src3 = "/soc/sound@ec500000/rcar_sound,src/src-3";
		src4 = "/soc/sound@ec500000/rcar_sound,src/src-4";
		src5 = "/soc/sound@ec500000/rcar_sound,src/src-5";
		src6 = "/soc/sound@ec500000/rcar_sound,src/src-6";
		src7 = "/soc/sound@ec500000/rcar_sound,src/src-7";
		src8 = "/soc/sound@ec500000/rcar_sound,src/src-8";
		src9 = "/soc/sound@ec500000/rcar_sound,src/src-9";
		ssiu00 = "/soc/sound@ec500000/rcar_sound,ssiu/ssiu-0";
		ssiu01 = "/soc/sound@ec500000/rcar_sound,ssiu/ssiu-1";
		ssiu02 = "/soc/sound@ec500000/rcar_sound,ssiu/ssiu-2";
		ssiu03 = "/soc/sound@ec500000/rcar_sound,ssiu/ssiu-3";
		ssiu04 = "/soc/sound@ec500000/rcar_sound,ssiu/ssiu-4";
		ssiu05 = "/soc/sound@ec500000/rcar_sound,ssiu/ssiu-5";
		ssiu06 = "/soc/sound@ec500000/rcar_sound,ssiu/ssiu-6";
		ssiu07 = "/soc/sound@ec500000/rcar_sound,ssiu/ssiu-7";
		ssiu10 = "/soc/sound@ec500000/rcar_sound,ssiu/ssiu-8";
		ssiu11 = "/soc/sound@ec500000/rcar_sound,ssiu/ssiu-9";
		ssiu12 = "/soc/sound@ec500000/rcar_sound,ssiu/ssiu-10";
		ssiu13 = "/soc/sound@ec500000/rcar_sound,ssiu/ssiu-11";
		ssiu14 = "/soc/sound@ec500000/rcar_sound,ssiu/ssiu-12";
		ssiu15 = "/soc/sound@ec500000/rcar_sound,ssiu/ssiu-13";
		ssiu16 = "/soc/sound@ec500000/rcar_sound,ssiu/ssiu-14";
		ssiu17 = "/soc/sound@ec500000/rcar_sound,ssiu/ssiu-15";
		ssiu20 = "/soc/sound@ec500000/rcar_sound,ssiu/ssiu-16";
		ssiu21 = "/soc/sound@ec500000/rcar_sound,ssiu/ssiu-17";
		ssiu22 = "/soc/sound@ec500000/rcar_sound,ssiu/ssiu-18";
		ssiu23 = "/soc/sound@ec500000/rcar_sound,ssiu/ssiu-19";
		ssiu24 = "/soc/sound@ec500000/rcar_sound,ssiu/ssiu-20";
		ssiu25 = "/soc/sound@ec500000/rcar_sound,ssiu/ssiu-21";
		ssiu26 = "/soc/sound@ec500000/rcar_sound,ssiu/ssiu-22";
		ssiu27 = "/soc/sound@ec500000/rcar_sound,ssiu/ssiu-23";
		ssiu30 = "/soc/sound@ec500000/rcar_sound,ssiu/ssiu-24";
		ssiu31 = "/soc/sound@ec500000/rcar_sound,ssiu/ssiu-25";
		ssiu32 = "/soc/sound@ec500000/rcar_sound,ssiu/ssiu-26";
		ssiu33 = "/soc/sound@ec500000/rcar_sound,ssiu/ssiu-27";
		ssiu34 = "/soc/sound@ec500000/rcar_sound,ssiu/ssiu-28";
		ssiu35 = "/soc/sound@ec500000/rcar_sound,ssiu/ssiu-29";
		ssiu36 = "/soc/sound@ec500000/rcar_sound,ssiu/ssiu-30";
		ssiu37 = "/soc/sound@ec500000/rcar_sound,ssiu/ssiu-31";
		ssiu40 = "/soc/sound@ec500000/rcar_sound,ssiu/ssiu-32";
		ssiu41 = "/soc/sound@ec500000/rcar_sound,ssiu/ssiu-33";
		ssiu42 = "/soc/sound@ec500000/rcar_sound,ssiu/ssiu-34";
		ssiu43 = "/soc/sound@ec500000/rcar_sound,ssiu/ssiu-35";
		ssiu44 = "/soc/sound@ec500000/rcar_sound,ssiu/ssiu-36";
		ssiu45 = "/soc/sound@ec500000/rcar_sound,ssiu/ssiu-37";
		ssiu46 = "/soc/sound@ec500000/rcar_sound,ssiu/ssiu-38";
		ssiu47 = "/soc/sound@ec500000/rcar_sound,ssiu/ssiu-39";
		ssiu50 = "/soc/sound@ec500000/rcar_sound,ssiu/ssiu-40";
		ssiu60 = "/soc/sound@ec500000/rcar_sound,ssiu/ssiu-41";
		ssiu70 = "/soc/sound@ec500000/rcar_sound,ssiu/ssiu-42";
		ssiu80 = "/soc/sound@ec500000/rcar_sound,ssiu/ssiu-43";
		ssiu90 = "/soc/sound@ec500000/rcar_sound,ssiu/ssiu-44";
		ssiu91 = "/soc/sound@ec500000/rcar_sound,ssiu/ssiu-45";
		ssiu92 = "/soc/sound@ec500000/rcar_sound,ssiu/ssiu-46";
		ssiu93 = "/soc/sound@ec500000/rcar_sound,ssiu/ssiu-47";
		ssiu94 = "/soc/sound@ec500000/rcar_sound,ssiu/ssiu-48";
		ssiu95 = "/soc/sound@ec500000/rcar_sound,ssiu/ssiu-49";
		ssiu96 = "/soc/sound@ec500000/rcar_sound,ssiu/ssiu-50";
		ssiu97 = "/soc/sound@ec500000/rcar_sound,ssiu/ssiu-51";
		ssi0 = "/soc/sound@ec500000/rcar_sound,ssi/ssi-0";
		ssi1 = "/soc/sound@ec500000/rcar_sound,ssi/ssi-1";
		ssi2 = "/soc/sound@ec500000/rcar_sound,ssi/ssi-2";
		ssi3 = "/soc/sound@ec500000/rcar_sound,ssi/ssi-3";
		ssi4 = "/soc/sound@ec500000/rcar_sound,ssi/ssi-4";
		ssi5 = "/soc/sound@ec500000/rcar_sound,ssi/ssi-5";
		ssi6 = "/soc/sound@ec500000/rcar_sound,ssi/ssi-6";
		ssi7 = "/soc/sound@ec500000/rcar_sound,ssi/ssi-7";
		ssi8 = "/soc/sound@ec500000/rcar_sound,ssi/ssi-8";
		ssi9 = "/soc/sound@ec500000/rcar_sound,ssi/ssi-9";
		rsnd_port0 = "/soc/sound@ec500000/ports/port@0";
		rsnd_for_ak4613 = "/soc/sound@ec500000/ports/port@0/endpoint";
		rsnd_port1 = "/soc/sound@ec500000/ports/port@1";
		rsnd_for_hdmi = "/soc/sound@ec500000/ports/port@1/endpoint";
		rsnd_port2 = "/soc/sound@ec500000/ports/port@2";
		rsnd_for_pcm3168a = "/soc/sound@ec500000/ports/port@2/endpoint";
		rsnd_port3 = "/soc/sound@ec500000/ports/port@3";
		rsnd_for_si468x = "/soc/sound@ec500000/ports/port@3/endpoint";
		rsnd_port4 = "/soc/sound@ec500000/ports/port@4";
		rsnd_for_wl18xx = "/soc/sound@ec500000/ports/port@4/endpoint";
		audma0 = "/soc/dma-controller@ec700000";
		audma1 = "/soc/dma-controller@ec720000";
		xhci0 = "/soc/usb@ee000000";
		usb3_peri0 = "/soc/usb@ee020000";
		ohci0 = "/soc/usb@ee080000";
		ohci1 = "/soc/usb@ee0a0000";
		ohci2 = "/soc/usb@ee0c0000";
		ohci3 = "/soc/usb@ee0e0000";
		ehci0 = "/soc/usb@ee080100";
		ehci1 = "/soc/usb@ee0a0100";
		ehci2 = "/soc/usb@ee0c0100";
		ehci3 = "/soc/usb@ee0e0100";
		usb2_phy0 = "/soc/usb-phy@ee080200";
		usb2_phy1 = "/soc/usb-phy@ee0a0200";
		usb2_phy2 = "/soc/usb-phy@ee0c0200";
		usb2_phy3 = "/soc/usb-phy@ee0e0200";
		sdhi0 = "/soc/mmc@ee100000";
		sdhi1 = "/soc/mmc@ee120000";
		sdhi2 = "/soc/mmc@ee140000";
		sdhi3 = "/soc/mmc@ee160000";
		wlcore = "/soc/mmc@ee160000/wlcore@2";
		sata = "/soc/sata@ee300000";
		gic = "/soc/interrupt-controller@f1010000";
		gsx = "/soc/gsx@fd000000";
		pciec0 = "/soc/pcie@fe000000";
		pciec1 = "/soc/pcie@ee800000";
		pciec0_ep = "/soc/pcie-ep@fe000000";
		pciec1_ep = "/soc/pcie-ep@ee800000";
		imr_v4l2_alloc = "/soc/imr_alloc";
		fcpcs = "/soc/vcp4@fe90f000";
		ivdp1c = "/soc/vcp4@fe8d0000";
		vcplf = "/soc/vcp4@fe910000";
		vdpb = "/soc/vcp4@fe900000";
		fdp0 = "/soc/fdpm@fe940000";
		fdp1 = "/soc/fdpm@fe944000";
		fcpvd0 = "/soc/fcp@fea27000";
		fcpvd1 = "/soc/fcp@fea2f000";
		fcpvd2 = "/soc/fcp@fea37000";
		vspbc = "/soc/vspm@fe920000";
		vspbd = "/soc/vspm@fe960000";
		vspd0 = "/soc/vsp@fea20000";
		vspd1 = "/soc/vsp@fea28000";
		vspd2 = "/soc/vsp@fea30000";
		vspi0 = "/soc/vspm@fe9a0000";
		vspi1 = "/soc/vspm@fe9b0000";
		cmm0 = "/soc/cmm@fea40000";
		cmm1 = "/soc/cmm@fea50000";
		cmm2 = "/soc/cmm@fea60000";
		cmm3 = "/soc/cmm@fea70000";
		csi20 = "/soc/csi2@fea80000";
		csi20_in = "/soc/csi2@fea80000/ports/port@0/endpoint";
		csi20vin0 = "/soc/csi2@fea80000/ports/port@1/endpoint@0";
		csi20vin1 = "/soc/csi2@fea80000/ports/port@1/endpoint@1";
		csi20vin2 = "/soc/csi2@fea80000/ports/port@1/endpoint@2";
		csi20vin3 = "/soc/csi2@fea80000/ports/port@1/endpoint@3";
		csi20vin4 = "/soc/csi2@fea80000/ports/port@1/endpoint@4";
		csi20vin5 = "/soc/csi2@fea80000/ports/port@1/endpoint@5";
		csi20vin6 = "/soc/csi2@fea80000/ports/port@1/endpoint@6";
		csi20vin7 = "/soc/csi2@fea80000/ports/port@1/endpoint@7";
		csi40 = "/soc/csi2@feaa0000";
		csi40_in = "/soc/csi2@feaa0000/ports/port@0/endpoint";
		csi40vin0 = "/soc/csi2@feaa0000/ports/port@1/endpoint@0";
		csi40vin1 = "/soc/csi2@feaa0000/ports/port@1/endpoint@1";
		csi40vin2 = "/soc/csi2@feaa0000/ports/port@1/endpoint@2";
		csi40vin3 = "/soc/csi2@feaa0000/ports/port@1/endpoint@3";
		csi41 = "/soc/csi2@feab0000";
		csi41vin4 = "/soc/csi2@feab0000/ports/port@1/endpoint@0";
		csi41vin5 = "/soc/csi2@feab0000/ports/port@1/endpoint@1";
		csi41vin6 = "/soc/csi2@feab0000/ports/port@1/endpoint@2";
		csi41vin7 = "/soc/csi2@feab0000/ports/port@1/endpoint@3";
		hdmi0 = "/soc/hdmi@fead0000";
		dw_hdmi0_in = "/soc/hdmi@fead0000/ports/port@0/endpoint";
		rcar_dw_hdmi0_out = "/soc/hdmi@fead0000/ports/port@1/endpoint";
		dw_hdmi0_snd_in = "/soc/hdmi@fead0000/ports/port@2/endpoint";
		hdmi1 = "/soc/hdmi@feae0000";
		dw_hdmi1_in = "/soc/hdmi@feae0000/ports/port@0/endpoint";
		du = "/soc/display@feb00000";
		du_out_rgb = "/soc/display@feb00000/ports/port@0/endpoint";
		du_out_hdmi0 = "/soc/display@feb00000/ports/port@1/endpoint";
		du_out_hdmi1 = "/soc/display@feb00000/ports/port@2/endpoint";
		du_out_lvds0 = "/soc/display@feb00000/ports/port@3/endpoint";
		lvds0 = "/soc/lvds@feb90000";
		lvds0_in = "/soc/lvds@feb90000/ports/port@0/endpoint";
		lvds0_out = "/soc/lvds@feb90000/ports/port@1/endpoint";
		rt_dmac0 = "/soc/dma-controller@ffc10000";
		rt_dmac1 = "/soc/dma-controller@ffc20000";
		prr = "/soc/chipid@fff00044";
		imp_distributer = "/soc/impdes0";
		usb3s0_clk = "/usb3s0";
		usb_extal_clk = "/usb_extal";
		audio_clkout = "/audio-clkout";
		hdmi0_con = "/hdmi0-out/port/endpoint";
		reg_1p8v = "/regulator0";
		reg_3p3v = "/regulator1";
		vcc_sdhi0 = "/regulator-vcc-sdhi0";
		vccq_sdhi0 = "/regulator-vccq-sdhi0";
		x12_clk = "/x12";
		x23_clk = "/x23-clock";
		lossy_decompress = "/reserved-memory/linux,lossy_decompress@54000000";
		mmp_reserved = "/reserved-memory/linux,multimedia@70000000";
		versaclock5_out3 = "/versaclk-3";
		versaclock5_out4 = "/versaclk-4";
		clksndsel = "/clksndsel";
		snd_3p3v = "/regulator-snd_3p3v";
		snd_vcc5v = "/regulator-snd_vcc5v";
		wlan_en = "/regulator-wlan_en";
		sd_wifi_mux = "/regulator@9";
		radio_switch = "/regulator@11";
		mpcie_3v3 = "/regulator@12";
		mpcie_1v8 = "/regulator@13";
		vdd_cam_a_0 = "/regulator@14";
		vdd_cam_a_1 = "/regulator@15";
		vdd_cam_a_2 = "/regulator@16";
		vdd_cam_a_3 = "/regulator@17";
		sound_card = "/sound@0";
		sound_ext = "/sound@1";
		sound_radio = "/sound@2";
		sound_wl18xx = "/sound@3";
		lvds = "/lvds";
		lvds_in = "/lvds/port/endpoint";
		hdmi_con = "/hdmi-out/port/endpoint";
		radio = "/si468x@0";
		si468x_endpoint = "/si468x@0/port/endpoint";
		wl18xx_pcm = "/wl18xx_pcm@0";
		wl18xx_endpoint = "/wl18xx_pcm@0/port/endpoint";
		camera_clk = "/camera_clk";
		ov5647_camera_clk = "/ov5647_camera_clk";
	};
};
